VERSION ""

NS_ :

BS_:

BU_: CGM_HS TCM_HS RDCM_HS EPS_HS ECM_HS EBCM_HS BSM_HS BCM_HS

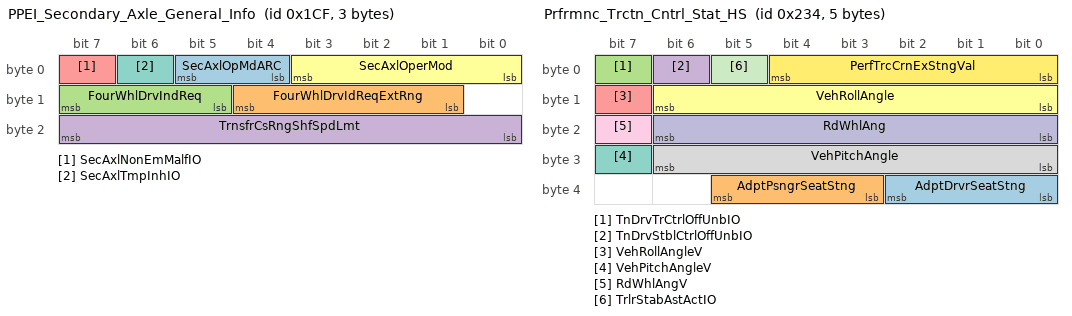
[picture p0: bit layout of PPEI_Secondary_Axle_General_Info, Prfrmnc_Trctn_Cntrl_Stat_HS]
BO_ 463 PPEI_Secondary_Axle_General_Info: 3 ECM_HS
 SG_ SecAxlOpMdARC : 5|2@0+ (1,0) [0|3] ""  CGM_HS,ECM_HS
 SG_ FourWhlDrvIdReqExtRng : 12|4@0+ (1,0) [0|15] ""  CGM_HS,BCM_HS
 SG_ FourWhlDrvIndReq : 15|3@0+ (1,0) [0|7] ""  CGM_HS,BCM_HS
 SG_ TrnsfrCsRngShfSpdLmt : 23|8@0+ (1,0) [0|255] "km / h"  CGM_HS,BCM_HS
 SG_ SecAxlNonEmMalfIO : 7|1@0+ (1,0) [0|1] ""  CGM_HS,BCM_HS
 SG_ SecAxlOperMod : 3|4@0+ (1,0) [0|15] ""  CGM_HS,TCM_HS,ECM_HS,EBCM_HS,BSM_HS,BCM_HS
 SG_ SecAxlTmpInhIO : 6|1@0+ (1,0) [0|1] ""  CGM_HS,BCM_HS

BO_ 869 CPS_Collision_Preparation_IO_HS: 4 CGM_HS
 SG_ TnDrvGapAdjUnbIO : 4|1@0+ (1,0) [0|1] ""  BCM_HS
 SG_ CPSCA_Resrv3Avail : 25|1@0+ (1,0) [0|1] ""  BCM_HS
 SG_ CPSCA_Resrv2Avail : 26|1@0+ (1,0) [0|1] ""  BCM_HS
 SG_ CPSCA_Resrv1Avail : 27|1@0+ (1,0) [0|1] ""  BCM_HS
 SG_ CPSCA_AlrtBrkStrAvail : 28|1@0+ (1,0) [0|1] ""  BCM_HS
 SG_ CPSCA_AlrtBrkAvail : 29|1@0+ (1,0) [0|1] ""  BCM_HS
 SG_ CPSCA_AlrtAvail : 30|1@0+ (1,0) [0|1] ""  BCM_HS
 SG_ CPSCA_OffAvail : 31|1@0+ (1,0) [0|1] ""  BCM_HS
 SG_ FwdClnMtgnBrkReqAct : 3|1@0+ (1,0) [0|1] ""  BCM_HS
 SG_ FCACustStngAvlbl : 23|1@0+ (1,0) [0|1] ""  BCM_HS
 SG_ FwdClnAlrtCustCrntSetngVal : 12|3@0+ (1,0) [0|7] ""  BCM_HS
 SG_ GNCustSetngAvlbl : 9|1@0+ (1,0) [0|1] ""  BCM_HS
 SG_ CPSUnblIO : 8|1@0+ (1,0) [0|1] ""  BCM_HS
 SG_ ColPrSysStngAvl : 7|1@0+ (1,0) [0|1] ""  BCM_HS
 SG_ CPSOffIO : 6|1@0+ (1,0) [0|1] ""  BCM_HS
 SG_ CPSFldIO : 5|1@0+ (1,0) [0|1] ""  BCM_HS
 SG_ ColPrSysCrntStng : 22|3@0+ (1,0) [0|7] ""  BCM_HS
 SG_ CPSAlrtOnlIO : 2|1@0+ (1,0) [0|1] ""  BCM_HS
 SG_ GNCustCrntStngVal : 15|3@0+ (1,0) [0|7] ""  BCM_HS

BO_ 564 Prfrmnc_Trctn_Cntrl_Stat_HS: 5 EBCM_HS
 SG_ AdptDrvrSeatStng : 34|3@0+ (1,0) [0|7] ""  CGM_HS,BCM_HS
 SG_ AdptPsngrSeatStng : 37|3@0+ (1,0) [0|7] ""  CGM_HS,BCM_HS
 SG_ TnDrvTrCtrlOffUnbIO : 7|1@0+ (1,0) [0|1] ""  CGM_HS,BCM_HS
 SG_ TnDrvStblCtrlOffUnbIO : 6|1@0+ (1,0) [0|1] ""  CGM_HS,BCM_HS
 SG_ VehRollAngleV : 15|1@0+ (1,0) [0|1] ""  CGM_HS,BCM_HS
 SG_ VehRollAngle : 14|7@0+ (0.703125,-45) [-45|44.296875] "deg"  CGM_HS,BCM_HS
 SG_ VehPitchAngleV : 31|1@0+ (1,0) [0|1] ""  CGM_HS,BCM_HS
 SG_ VehPitchAngle : 30|7@0+ (0.703125,-45) [-45|44.296875] "deg"  CGM_HS,BCM_HS
 SG_ RdWhlAngV : 23|1@0+ (1,0) [0|1] ""  CGM_HS,BCM_HS
 SG_ RdWhlAng : 22|7@0+ (0.703125,-45) [-45|44.296875] "deg"  CGM_HS,BCM_HS
 SG_ TrlrStabAstActIO : 5|1@0+ (1,0) [0|1] ""  CGM_HS,BCM_HS
 SG_ PerfTrcCrnExStngVal : 4|5@0+ (1,0) [0|31] ""  CGM_HS,BCM_HS

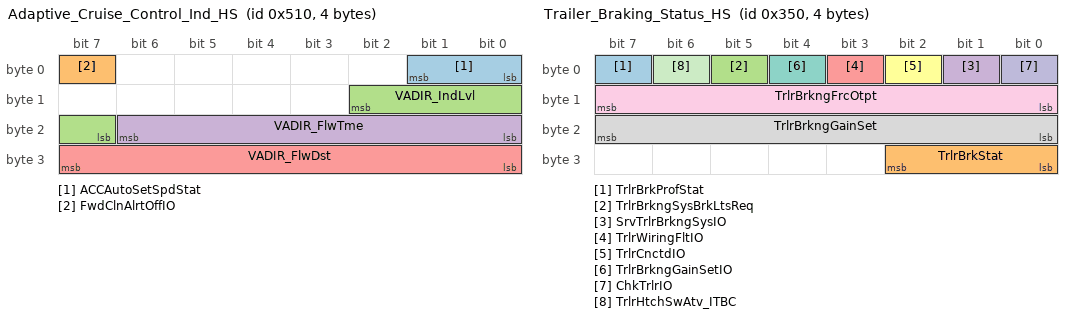
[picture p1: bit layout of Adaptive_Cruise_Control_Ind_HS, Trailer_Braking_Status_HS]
BO_ 1296 Adaptive_Cruise_Control_Ind_HS: 4 CGM_HS
 SG_ ACCAutoSetSpdStat : 1|2@0+ (1,0) [0|3] ""  BCM_HS
 SG_ FwdClnAlrtOffIO : 7|1@0+ (1,0) [0|1] ""  BCM_HS
 SG_ VADIR_IndLvl : 10|4@0+ (1,0) [0|15] ""  BCM_HS
 SG_ VADIR_FlwTme : 22|7@0+ (0.1,0) [0|12.7] "s"  BCM_HS
 SG_ VADIR_FlwDst : 31|8@0+ (1,0) [0|255] "m"  BCM_HS

BO_ 848 Trailer_Braking_Status_HS: 4 EBCM_HS
 SG_ TrlrBrkProfStat : 7|1@0+ (1,0) [0|1] ""  CGM_HS
 SG_ TrlrBrkStat : 26|3@0+ (1,0) [0|7] ""  CGM_HS,EBCM_HS
 SG_ TrlrBrkngSysBrkLtsReq : 5|1@0+ (1,0) [0|1] ""  CGM_HS,BCM_HS
 SG_ SrvTrlrBrkngSysIO : 1|1@0+ (1,0) [0|1] ""  CGM_HS,BCM_HS
 SG_ TrlrWiringFltIO : 3|1@0+ (1,0) [0|1] ""  CGM_HS,BCM_HS
 SG_ TrlrCnctdIO : 2|1@0+ (1,0) [0|1] ""  CGM_HS,BCM_HS
 SG_ TrlrBrkngGainSetIO : 4|1@0+ (1,0) [0|1] ""  CGM_HS,BCM_HS
 SG_ TrlrBrkngGainSet : 23|8@0+ (0.392157,0) [0|100.000035] "%"  CGM_HS,EBCM_HS,BCM_HS
 SG_ TrlrBrkngFrcOtpt : 15|8@0+ (0.392157,0) [0|100.000035] "%"  CGM_HS,EBCM_HS,BCM_HS
 SG_ ChkTrlrIO : 0|1@0+ (1,0) [0|1] ""  CGM_HS,BCM_HS
 SG_ TrlrHtchSwAtv_ITBC : 6|1@0+ (1,0) [0|1] ""  CGM_HS,BCM_HS

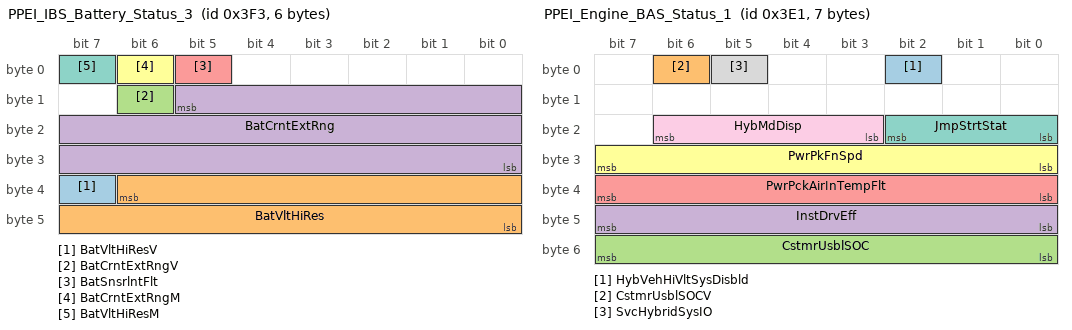
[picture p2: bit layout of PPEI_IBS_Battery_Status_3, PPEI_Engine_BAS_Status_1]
BO_ 1011 PPEI_IBS_Battery_Status_3: 6 ECM_HS
 SG_ BatVltHiResV : 39|1@0+ (1,0) [0|1] ""  CGM_HS,BCM_HS
 SG_ BatVltHiRes : 38|15@0+ (0.001,0) [0|32.767] "volts"  CGM_HS,BCM_HS
 SG_ BatCrntExtRngV : 14|1@0+ (1,0) [0|1] ""  CGM_HS,BCM_HS
 SG_ BatCrntExtRng : 13|22@0+ (0.001,-2097.152) [-2097.152|2097.151] "amps"  CGM_HS,BCM_HS
 SG_ BatSnsrlntFlt : 5|1@0+ (1,0) [0|1] ""  CGM_HS,BCM_HS
 SG_ BatCrntExtRngM : 6|1@0+ (1,0) [0|1] ""  CGM_HS,BCM_HS
 SG_ BatVltHiResM : 7|1@0+ (1,0) [0|1] ""  CGM_HS,BCM_HS

BO_ 993 PPEI_Engine_BAS_Status_1: 7 BSM_HS
 SG_ HybVehHiVltSysDisbld : 2|1@0+ (1,0) [0|1] ""  CGM_HS
 SG_ CstmrUsblSOCV : 6|1@0+ (1,0) [0|1] ""  CGM_HS,BCM_HS
 SG_ CstmrUsblSOC : 55|8@0+ (0.39216,0) [0|100.0008] "%"  CGM_HS,BCM_HS
 SG_ InstDrvEff : 47|8@0- (0.78125,0) [-100|99.21875] "%"  CGM_HS,BCM_HS
 SG_ PwrPckAirInTempFlt : 39|8@0+ (1,-40) [-40|215] "deg C"  CGM_HS,BCM_HS
 SG_ PwrPkFnSpd : 31|8@0+ (0.392157,0) [0|100.000035] "%"  CGM_HS,BCM_HS
 SG_ JmpStrtStat : 18|3@0+ (1,0) [0|7] ""  CGM_HS,BCM_HS
 SG_ SvcHybridSysIO : 5|1@0+ (1,0) [0|1] ""  CGM_HS,BCM_HS
 SG_ HybMdDisp : 22|4@0+ (1,0) [0|15] ""  CGM_HS,BCM_HS

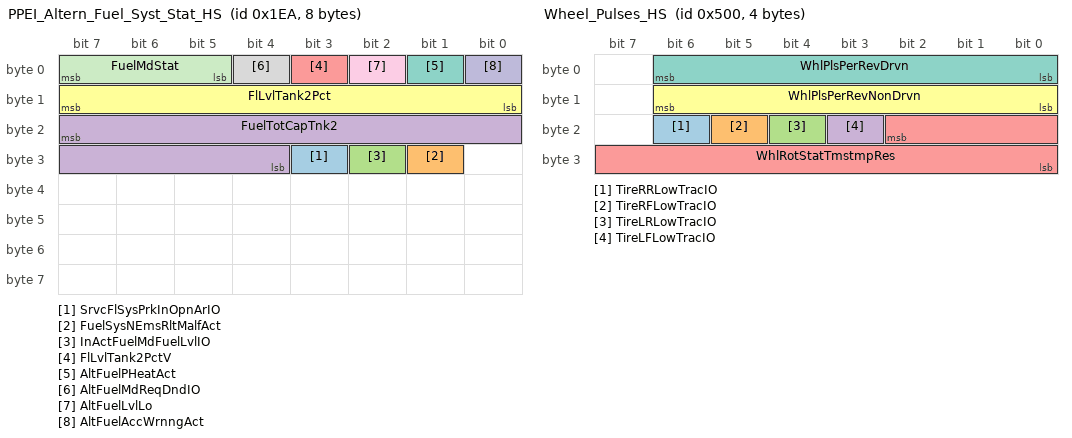
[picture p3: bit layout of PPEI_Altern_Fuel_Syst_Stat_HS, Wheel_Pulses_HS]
BO_ 490 PPEI_Altern_Fuel_Syst_Stat_HS: 8 ECM_HS
 SG_ SrvcFlSysPrkInOpnArIO : 27|1@0+ (1,0) [0|1] ""  CGM_HS,BCM_HS
 SG_ FuelSysNEmsRltMalfAct : 25|1@0+ (1,0) [0|1] ""  CGM_HS,BCM_HS
 SG_ InActFuelMdFuelLvlIO : 26|1@0+ (1,0) [0|1] ""  CGM_HS,BCM_HS
 SG_ FuelTotCapTnk2 : 23|12@0+ (0.125,0) [0|511.875] "liters"  CGM_HS,BCM_HS
 SG_ FlLvlTank2PctV : 3|1@0+ (1,0) [0|1] ""  CGM_HS,BCM_HS
 SG_ FlLvlTank2Pct : 15|8@0+ (0.392157,0) [0|100.000035] "%"  CGM_HS,BCM_HS
 SG_ AltFuelPHeatAct : 1|1@0+ (1,0) [0|1] ""  CGM_HS,ECM_HS,BCM_HS
 SG_ AltFuelMdReqDndIO : 4|1@0+ (1,0) [0|1] ""  CGM_HS,BCM_HS
 SG_ AltFuelLvlLo : 2|1@0+ (1,0) [0|1] ""  CGM_HS,ECM_HS,BCM_HS
 SG_ AltFuelAccWrnngAct : 0|1@0+ (1,0) [0|1] ""  CGM_HS,BCM_HS
 SG_ FuelMdStat : 7|3@0+ (1,0) [0|7] ""  CGM_HS,ECM_HS,BCM_HS

BO_ 452 PPEI_Torque_Request_Status: 8 ECM_HS
 SG_ ACCATCS_LmtgStat : 12|2@0+ (1,0) [0|3] ""  CGM_HS
 SG_ ACCATCS_RqStat : 15|3@0+ (1,0) [0|7] ""  CGM_HS
 SG_ RdLdNomAxlTrq : 10|19@0+ (0.125,-22534) [-22534|43001.875] "Nm"  CGM_HS
 SG_ CPSATCS_ReqStatus : 37|3@0+ (1,0) [0|7] ""  CGM_HS
 SG_ CPSATCS_LmtngStatus : 39|2@0+ (1,0) [0|3] ""  CGM_HS
 SG_ RVBATCS_ReqStat : 53|3@0+ (1,0) [0|7] ""  CGM_HS
 SG_ RVBATCS_LmtngStat : 55|2@0+ (1,0) [0|3] ""  CGM_HS
 SG_ FSpRgACCSwADdPVal : 50|2@0+ (1,0) [0|3] ""  CGM_HS,EBCM_HS
 SG_ FSpRgACCSwADdARC : 6|2@0+ (1,0) [0|3] ""  CGM_HS,EBCM_HS
 SG_ FSpRgACCSwADd : 7|1@0+ (1,0) [0|1] ""  CGM_HS,EBCM_HS
 SG_ AutBrkAccActPsStRC : 34|2@0+ (1,0) [0|3] ""  CGM_HS,EBCM_HS
 SG_ AutBrkAccActPsStPVal : 48|9@0+ (1,0) [0|511] ""  CGM_HS,EBCM_HS
 SG_ ABAAPS_AccPos : 47|8@0+ (0.392157,0) [0|100.000035] "%"  CGM_HS,EBCM_HS
 SG_ ABAAPS_AccPosV : 32|1@0+ (1,0) [0|1] ""  CGM_HS,EBCM_HS
 SG_ AccPdlOvrrdAtvProtVal : 1|2@0+ (1,0) [0|3] ""  CGM_HS,TCM_HS,EBCM_HS
 SG_ AccPdlOvrrdAtvARC : 3|2@0+ (1,0) [0|3] ""  CGM_HS,TCM_HS,EBCM_HS
 SG_ AccPdlOvrrdAtv : 4|1@0+ (1,0) [0|1] ""  CGM_HS,TCM_HS,EBCM_HS,BCM_HS

BO_ 1280 Wheel_Pulses_HS: 4 EBCM_HS
 SG_ TireRRLowTracIO : 22|1@0+ (1,0) [0|1] ""  CGM_HS,BCM_HS
 SG_ TireRFLowTracIO : 21|1@0+ (1,0) [0|1] ""  CGM_HS,BCM_HS
 SG_ TireLRLowTracIO : 20|1@0+ (1,0) [0|1] ""  CGM_HS,BCM_HS
 SG_ TireLFLowTracIO : 19|1@0+ (1,0) [0|1] ""  CGM_HS,BCM_HS
 SG_ WhlRotStatTmstmpRes : 18|11@0+ (0.002,0) [0|4.094] "uSec"  CGM_HS,EPS_HS,RDCM_HS,BCM_HS
 SG_ WhlPlsPerRevNonDrvn : 14|7@0+ (1,0) [0|127] ""  CGM_HS,EPS_HS,RDCM_HS,BCM_HS
 SG_ WhlPlsPerRevDrvn : 6|7@0+ (1,0) [0|127] ""  CGM_HS,EPS_HS,RDCM_HS,BCM_HS

BO_ 562 Driving_Mode_Control_HS: 8 EBCM_HS
 SG_ BrkSysAutBrkStat : 52|2@0+ (1,0) [0|3] ""  CGM_HS
 SG_ FSRACCBrkngReqDenied : 46|1@0+ (1,0) [0|1] ""  CGM_HS
 SG_ BrkSysExtHldCpbltyFld : 47|1@0+ (1,0) [0|1] ""  CGM_HS
 SG_ DrvlneMntsPerfMdRq : 50|3@0+ (1,0) [0|7] ""  CGM_HS,ECM_HS
 SG_ RideCntrlPerfMdRq : 18|3@0+ (1,0) [0|7] ""  CGM_HS
 SG_ StgSysPerfMdRq : 29|3@0+ (1,0) [0|7] ""  CGM_HS,EPS_HS
 SG_ DiffPerfMdRq : 26|3@0+ (1,0) [0|7] ""  CGM_HS
 SG_ ExhstPerfMdRq : 5|3@0+ (1,0) [0|7] ""  CGM_HS
 SG_ DrvMdCntrlState : 39|8@0+ (1,0) [0|255] ""  CGM_HS,EPS_HS,RDCM_HS
 SG_ AWDPerfMdRq : 2|3@0+ (1,0) [0|7] ""  CGM_HS,RDCM_HS
 SG_ SndPerfMdCsStAvl : 63|1@0+ (1,0) [0|1] ""  CGM_HS,BCM_HS
 SG_ SndPerfMdCsCrStVal : 62|3@0+ (1,0) [0|7] ""  CGM_HS,BCM_HS
 SG_ DispPerfMdCsStAvl : 59|1@0+ (1,0) [0|1] ""  CGM_HS,BCM_HS
 SG_ DispPerfMdCsCrStVal : 58|3@0+ (1,0) [0|7] ""  CGM_HS,BCM_HS
 SG_ SndEnhcmtPerfMdRq : 13|3@0+ (1,0) [0|7] ""  CGM_HS,BCM_HS
 SG_ DsplyPerfMdRq : 10|3@0+ (1,0) [0|7] ""  CGM_HS,BCM_HS
 SG_ HillDscntCntlSysStat : 55|3@0+ (1,0) [0|7] ""  CGM_HS,BCM_HS
 SG_ SusCustStngAvlbl : 23|1@0+ (1,0) [0|1] ""  CGM_HS,BCM_HS
 SG_ SusCustCurrStngVal : 45|3@0+ (1,0) [0|7] ""  CGM_HS,BCM_HS
 SG_ StrCustStngAvlbl : 7|1@0+ (1,0) [0|1] ""  CGM_HS,BCM_HS
 SG_ StrCustCurrStngVal : 42|3@0+ (1,0) [0|7] ""  CGM_HS,BCM_HS
 SG_ DrvlnCustStngAvlbl : 6|1@0+ (1,0) [0|1] ""  CGM_HS,BCM_HS
 SG_ DrvlnCustCurrStngVal : 22|3@0+ (1,0) [0|7] ""  CGM_HS,BCM_HS

BO_ 386 Environment_Id_Resp_4_HS: 8 EBCM_HS
 SG_ AdptCruzCtrlStg : 20|3@0+ (1,0) [0|7] ""  CGM_HS
 SG_ AHAct : 31|1@0+ (1,0) [0|1] ""  CGM_HS,BCM_HS
 SG_ AHEnbld : 30|1@0+ (1,0) [0|1] ""  CGM_HS,BCM_HS
 SG_ ShfToPrkBfExtngIO : 29|1@0+ (1,0) [0|1] ""  CGM_HS,BCM_HS
 SG_ AHServcIO : 28|1@0+ (1,0) [0|1] ""  CGM_HS,BCM_HS
 SG_ AHAppBrkPedlIO : 27|1@0+ (1,0) [0|1] ""  CGM_HS,BCM_HS
 SG_ AHDisbldStbltIO : 26|1@0+ (1,0) [0|1] ""  CGM_HS,BCM_HS
 SG_ AHDisbldDrOpnIO : 25|1@0+ (1,0) [0|1] ""  CGM_HS,BCM_HS
 SG_ PMVSS_Disps : 58|3@0+ (1,0) [0|7] ""  CGM_HS,BCM_HS
 SG_ PMVSS_Exhst : 61|3@0+ (1,0) [0|7] ""  CGM_HS,BCM_HS
 SG_ PMVSS_PsngrSeat : 48|3@0+ (1,0) [0|7] ""  CGM_HS,BCM_HS
 SG_ PMVSS_DrvrSeat : 51|3@0+ (1,0) [0|7] ""  CGM_HS,BCM_HS
 SG_ PMVSS_AdptCrsCnt : 54|3@0+ (1,0) [0|7] ""  CGM_HS,BCM_HS
 SG_ PMVSS_Drvln : 41|3@0+ (1,0) [0|7] ""  CGM_HS,BCM_HS
 SG_ PMVSS_Susp : 44|3@0+ (1,0) [0|7] ""  CGM_HS,BCM_HS
 SG_ PMVSS_Strng : 47|3@0+ (1,0) [0|7] ""  CGM_HS,BCM_HS
 SG_ PMVSS_Trans : 34|3@0+ (1,0) [0|7] ""  CGM_HS,BCM_HS
 SG_ PMVSS_Eng : 37|3@0+ (1,0) [0|7] ""  CGM_HS,BCM_HS
 SG_ PMVSS_Snd : 24|3@0+ (1,0) [0|7] ""  CGM_HS,BCM_HS
 SG_ AWDRecmndIO : 21|1@0+ (1,0) [0|1] ""  CGM_HS,BCM_HS
 SG_ EnvIdRsp4 : 7|16@0+ (1,0) [0|65535] ""  CGM_HS,BCM_HS
 SG_ EnvIdRspSt4 : 17|2@0+ (1,0) [0|3] ""  CGM_HS,BCM_HS

BO_ 532 Brake_Pedal_Driver_Status_HS: 6 EBCM_HS
 SG_ RedntVSEActARC : 38|2@0+ (1,0) [0|3] ""  CGM_HS,EPS_HS
 SG_ RedntVSEAct : 39|1@0+ (1,0) [0|1] ""  CGM_HS,EPS_HS
 SG_ AutoBrkngActARC : 22|2@0+ (1,0) [0|3] ""  CGM_HS
 SG_ VehHldDrvrDsblActvFlg : 36|1@0+ (1,0) [0|1] ""  CGM_HS
 SG_ ABSAutnmsBrkReqPVal : 41|2@0+ (1,0) [0|3] ""  CGM_HS
 SG_ AutoBrkngAvlbl : 17|1@0+ (1,0) [0|1] ""  CGM_HS,EPS_HS,ECM_HS
 SG_ ABSAutnmsBrkReqARC : 35|2@0+ (1,0) [0|3] ""  CGM_HS
 SG_ ABSAutnmsBrkReq : 33|1@0+ (1,0) [0|1] ""  CGM_HS
 SG_ ABSActvProtPVal : 43|2@0+ (1,0) [0|3] ""  CGM_HS,EPS_HS
 SG_ ABSActvProtARC : 45|2@0+ (1,0) [0|3] ""  CGM_HS,EPS_HS
 SG_ ABSActvProt : 46|1@0+ (1,0) [0|1] ""  CGM_HS,EPS_HS
 SG_ BrkPdDrvAPrsStaPVal : 16|9@0+ (1,0) [0|511] ""  CGM_HS
 SG_ BrkPdDrvAppPrsAlRC : 2|2@0+ (1,0) [0|3] ""  CGM_HS
 SG_ AutoBrkngAct : 18|1@0+ (1,0) [0|1] ""  CGM_HS
 SG_ HilRlbkCtrlActIO : 19|1@0+ (1,0) [0|1] ""  CGM_HS,BCM_HS
 SG_ HlStrAssActIO : 20|1@0+ (1,0) [0|1] ""  CGM_HS,BCM_HS
 SG_ BrkSysAutBrkFld : 5|1@0+ (1,0) [0|1] ""  CGM_HS,ECM_HS,BCM_HS
 SG_ IntBrkAssPreFilReq : 4|1@0+ (1,0) [0|1] "N/A"  CGM_HS,BCM_HS
 SG_ BrkSysMalFuncIndOn : 3|1@0+ (1,0) [0|1] ""  CGM_HS,BCM_HS
 SG_ BPDAPS_BkPDrvApPV : 8|1@0+ (1,0) [0|1] ""  CGM_HS,BCM_HS
 SG_ BPDAPS_BkPDrvApP : 0|8@0+ (75,0) [0|19125] "kPa"  CGM_HS,BCM_HS
 SG_ BrkFldLvlLwV : 7|1@0+ (1,0) [0|1] ""  CGM_HS,BCM_HS
 SG_ BrkFldLvlLw : 6|1@0+ (1,0) [0|1] ""  CGM_HS,BCM_HS

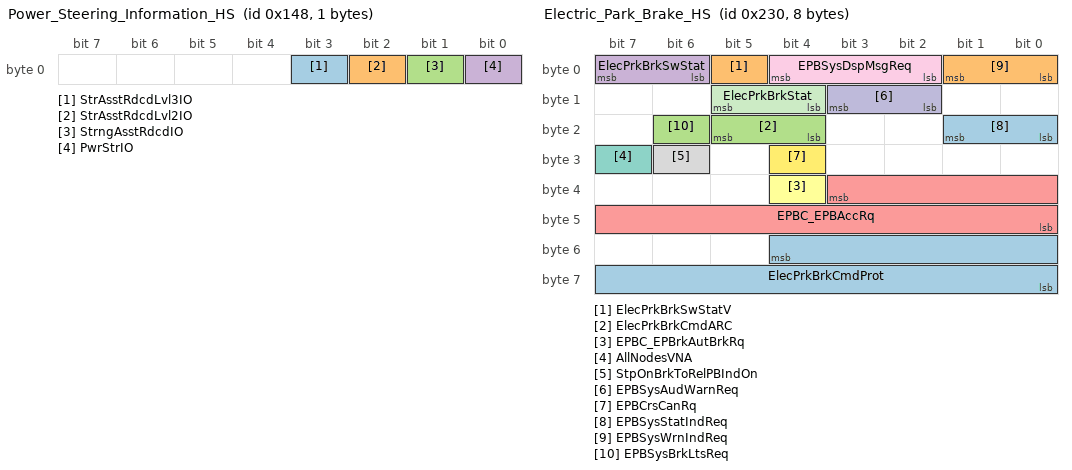
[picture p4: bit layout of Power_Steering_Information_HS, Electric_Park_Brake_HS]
BO_ 328 Power_Steering_Information_HS: 1 EBCM_HS
 SG_ StrAsstRdcdLvl3IO : 3|1@0+ (1,0) [0|1] ""  CGM_HS,BCM_HS
 SG_ StrAsstRdcdLvl2IO : 2|1@0+ (1,0) [0|1] ""  CGM_HS,BCM_HS
 SG_ StrngAsstRdcdIO : 1|1@0+ (1,0) [0|1] ""  CGM_HS,BCM_HS
 SG_ PwrStrIO : 0|1@0+ (1,0) [0|1] ""  CGM_HS,BCM_HS

BO_ 560 Electric_Park_Brake_HS: 8 EBCM_HS
 SG_ ElecPrkBrkCmdProt : 52|13@0+ (1,0) [0|8191] ""  CGM_HS
 SG_ ElecPrkBrkSwStatV : 5|1@0+ (1,0) [0|1] ""  CGM_HS
 SG_ ElecPrkBrkCmdARC : 21|2@0+ (1,0) [0|3] ""  CGM_HS
 SG_ ElecPrkBrkSwStat : 7|2@0+ (1,0) [0|3] ""  CGM_HS
 SG_ EPBC_EPBAccRq : 35|12@0- (0.01,0) [-20.48|20.47] "m/s^2"  CGM_HS
 SG_ EPBC_EPBrkAutBrkRq : 36|1@0+ (1,0) [0|1] ""  CGM_HS
 SG_ AllNodesVNA : 31|1@0+ (1,0) [0|1] ""  CGM_HS,BCM_HS
 SG_ StpOnBrkToRelPBIndOn : 30|1@0+ (1,0) [0|1] ""  CGM_HS,BCM_HS
 SG_ EPBSysDspMsgReq : 4|3@0+ (1,0) [0|7] ""  CGM_HS,BCM_HS
 SG_ EPBSysAudWarnReq : 11|2@0+ (1,0) [0|3] ""  CGM_HS,BCM_HS
 SG_ ElecPrkBrkStat : 13|2@0+ (1,0) [0|3] ""  CGM_HS,RDCM_HS,BCM_HS
 SG_ EPBCrsCanRq : 28|1@0+ (1,0) [0|1] ""  CGM_HS,BCM_HS
 SG_ EPBSysStatIndReq : 17|2@0+ (1,0) [0|3] ""  CGM_HS,BCM_HS
 SG_ EPBSysWrnIndReq : 1|2@0+ (1,0) [0|3] ""  CGM_HS,BCM_HS
 SG_ EPBSysBrkLtsReq : 22|1@0+ (1,0) [0|1] ""  CGM_HS,BCM_HS

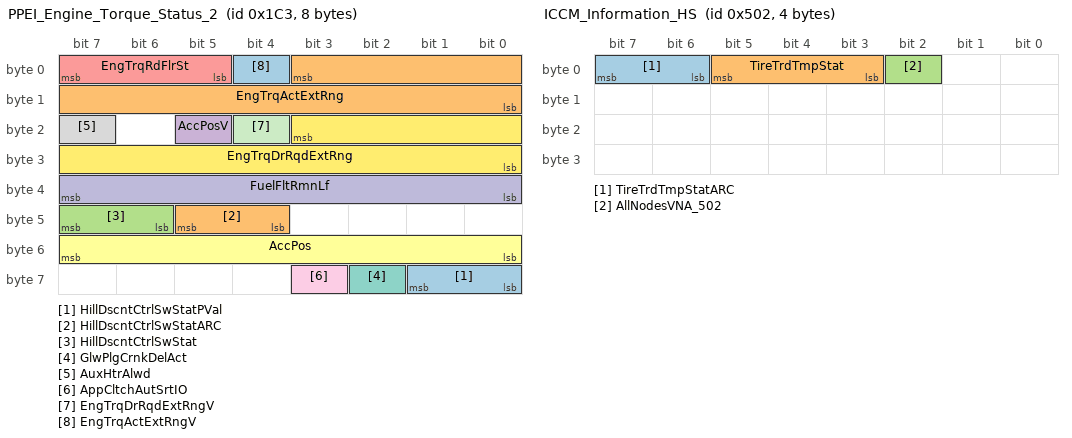
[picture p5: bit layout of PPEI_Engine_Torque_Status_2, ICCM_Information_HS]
BO_ 451 PPEI_Engine_Torque_Status_2: 8 ECM_HS
 SG_ HillDscntCtrlSwStatPVal : 57|2@0+ (1,0) [0|3] ""  CGM_HS,EBCM_HS
 SG_ HillDscntCtrlSwStatARC : 45|2@0+ (1,0) [0|3] ""  CGM_HS,EBCM_HS
 SG_ HillDscntCtrlSwStat : 47|2@0+ (1,0) [0|3] ""  CGM_HS,EBCM_HS
 SG_ AccPosV : 21|1@0+ (1,0) [0|1] ""  CGM_HS,RDCM_HS,EBCM_HS
 SG_ EngTrqRdFlrSt : 7|3@0+ (1,0) [0|7] ""  CGM_HS,EBCM_HS
 SG_ AccPos : 55|8@0+ (0.392157,0) [0|100.000035] "%"  CGM_HS,RDCM_HS,EBCM_HS,BSM_HS
 SG_ GlwPlgCrnkDelAct : 58|1@0+ (1,0) [0|1] ""  CGM_HS,BCM_HS
 SG_ AuxHtrAlwd : 23|1@0+ (1,0) [0|1] ""  CGM_HS,BCM_HS
 SG_ AppCltchAutSrtIO : 59|1@0+ (1,0) [0|1] ""  CGM_HS,BCM_HS
 SG_ FuelFltRmnLf : 39|8@0+ (0.392157,0) [0|100.000035] "%"  CGM_HS,BCM_HS
 SG_ EngTrqDrRqdExtRngV : 20|1@0+ (1,0) [0|1] ""  CGM_HS,RDCM_HS,EBCM_HS,BCM_HS
 SG_ EngTrqDrRqdExtRng : 19|12@0+ (0.5,-848) [-848|1199.5] "Nm"  CGM_HS,RDCM_HS,EBCM_HS,BCM_HS
 SG_ EngTrqActExtRngV : 4|1@0+ (1,0) [0|1] ""  CGM_HS,EPS_HS,RDCM_HS,EBCM_HS,BCM_HS
 SG_ EngTrqActExtRng : 3|12@0+ (0.5,-848) [-848|1199.5] "Nm"  CGM_HS,EPS_HS,RDCM_HS,EBCM_HS,BCM_HS

BO_ 1282 ICCM_Information_HS: 4 EBCM_HS
 SG_ TireTrdTmpStatARC : 7|2@0+ (1,0) [0|3] ""  CGM_HS,EBCM_HS
 SG_ TireTrdTmpStat : 5|3@0+ (1,0) [0|7] ""  CGM_HS,EBCM_HS,BCM_HS
 SG_ AllNodesVNA_502 : 2|1@0+ (1,0) [0|1] ""  CGM_HS,BCM_HS

BO_ 2033 PCU_Req_to_SDM_HS: 8 CGM_HS
 SG_ PCUInfo : 7|64@0+ (1,0) [0|1.84467440737096E+019] ""  CGM_HS,BCM_HS

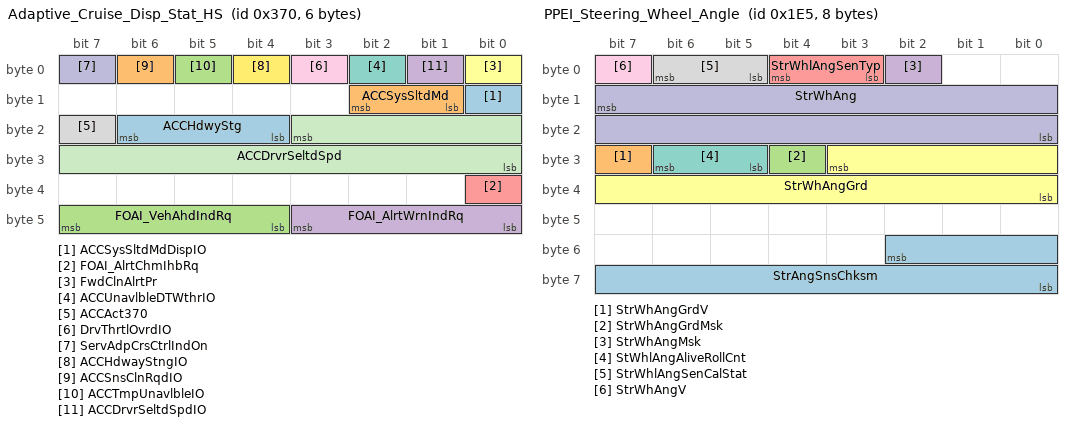
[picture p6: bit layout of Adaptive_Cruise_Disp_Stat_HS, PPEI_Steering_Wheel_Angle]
BO_ 880 Adaptive_Cruise_Disp_Stat_HS: 6 CGM_HS
 SG_ ACCSysSltdMdDispIO : 8|1@0+ (1,0) [0|1] ""  BCM_HS
 SG_ ACCSysSltdMd : 10|2@0+ (1,0) [0|3] ""  BCM_HS
 SG_ FOAI_VehAhdIndRq : 47|4@0+ (1,0) [0|15] ""  BCM_HS
 SG_ FOAI_AlrtWrnIndRq : 43|4@0+ (1,0) [0|15] ""  BCM_HS
 SG_ FOAI_AlrtChmIhbRq : 32|1@0+ (1,0) [0|1] ""  BCM_HS
 SG_ FwdClnAlrtPr : 0|1@0+ (1,0) [0|1] ""  BCM_HS
 SG_ ACCUnavlbleDTWthrIO : 2|1@0+ (1,0) [0|1] ""  BCM_HS
 SG_ ACCAct370 : 23|1@0+ (1,0) [0|1] ""  TCM_HS,EBCM_HS,BCM_HS
 SG_ DrvThrtlOvrdIO : 3|1@0+ (1,0) [0|1] ""  BCM_HS
 SG_ ServAdpCrsCtrlIndOn : 7|1@0+ (1,0) [0|1] ""  BCM_HS
 SG_ ACCDrvrSeltdSpd : 19|12@0+ (0.0625,0) [0|255.9375] "km / h"  ECM_HS,BCM_HS
 SG_ ACCHdwayStngIO : 4|1@0+ (1,0) [0|1] ""  BCM_HS
 SG_ ACCHdwyStg : 22|3@0+ (1,0) [0|7] ""  BCM_HS
 SG_ ACCSnsClnRqdIO : 6|1@0+ (1,0) [0|1] ""  BCM_HS
 SG_ ACCTmpUnavlbleIO : 5|1@0+ (1,0) [0|1] ""  BCM_HS
 SG_ ACCDrvrSeltdSpdIO : 1|1@0+ (1,0) [0|1] ""  BCM_HS

BO_ 577 USDT_Req_to_BCM_HS: 8 CGM_HS
 SG_ DgnInf : 7|64@0+ (1,0) [0|1.84467440737096E+019] ""  BCM_HS

BO_ 485 PPEI_Steering_Wheel_Angle: 8 EBCM_HS
 SG_ StrAngSnsChksm : 50|11@0+ (1,0) [0|2047] ""  CGM_HS,TCM_HS,EPS_HS,ECM_HS,EBCM_HS
 SG_ StrWhAngGrdV : 31|1@0+ (1,0) [0|1] ""  CGM_HS,TCM_HS,RDCM_HS,EPS_HS,ECM_HS,EBCM_HS
 SG_ StrWhAngGrdMsk : 28|1@0+ (1,0) [0|1] ""  CGM_HS,EPS_HS,EBCM_HS
 SG_ StrWhAngMsk : 2|1@0+ (1,0) [0|1] ""  CGM_HS,TCM_HS,RDCM_HS,EPS_HS,ECM_HS,EBCM_HS
 SG_ StrWhlAngSenTyp : 4|2@0+ (1,0) [0|3] ""  CGM_HS,EPS_HS,EBCM_HS
 SG_ StrWhAngGrd : 27|12@0- (1,0) [-2048|2047] "deg/sec"  CGM_HS,TCM_HS,RDCM_HS,EPS_HS,ECM_HS,EBCM_HS
 SG_ StWhlAngAliveRollCnt : 30|2@0+ (1,0) [0|3] ""  CGM_HS,TCM_HS,RDCM_HS,EPS_HS,ECM_HS,EBCM_HS
 SG_ StrWhlAngSenCalStat : 6|2@0+ (1,0) [0|3] ""  CGM_HS,TCM_HS,RDCM_HS,EPS_HS,ECM_HS,EBCM_HS,BCM_HS
 SG_ StrWhAngV : 7|1@0+ (1,0) [0|1] ""  CGM_HS,TCM_HS,RDCM_HS,EPS_HS,ECM_HS,EBCM_HS,BCM_HS
 SG_ StrWhAng : 15|16@0- (0.0625,0) [-2048|2047.9375] "deg"  CGM_HS,TCM_HS,RDCM_HS,EPS_HS,ECM_HS,EBCM_HS,BCM_HS

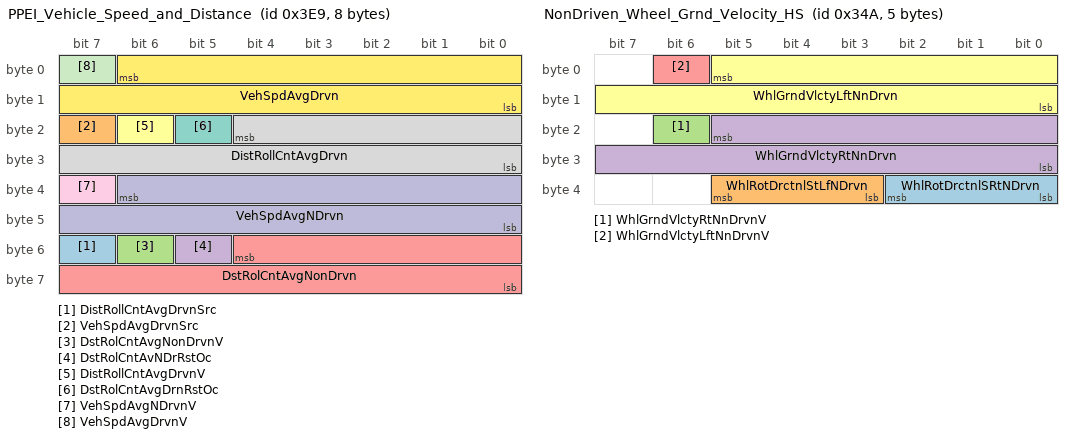
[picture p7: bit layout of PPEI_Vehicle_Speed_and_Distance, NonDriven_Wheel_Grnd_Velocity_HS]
BO_ 1001 PPEI_Vehicle_Speed_and_Distance: 8 ECM_HS
 SG_ DistRollCntAvgDrvnSrc : 55|1@0+ (1,0) [0|1] ""  CGM_HS,TCM_HS,EPS_HS,EBCM_HS,BSM_HS,BCM_HS
 SG_ VehSpdAvgDrvnSrc : 23|1@0+ (1,0) [0|1] ""  CGM_HS,TCM_HS,EPS_HS,EBCM_HS,BCM_HS
 SG_ DstRolCntAvgNonDrvnV : 54|1@0+ (1,0) [0|1] ""  CGM_HS,EPS_HS,EBCM_HS,BSM_HS,BCM_HS
 SG_ DstRolCntAvNDrRstOc : 53|1@0+ (1,0) [0|1] ""  CGM_HS,EPS_HS,EBCM_HS,BSM_HS,BCM_HS
 SG_ DstRolCntAvgNonDrvn : 52|13@0+ (0.125,0) [0|1023.875] "m"  CGM_HS,EPS_HS,EBCM_HS,BSM_HS,BCM_HS
 SG_ DistRollCntAvgDrvnV : 22|1@0+ (1,0) [0|1] ""  CGM_HS,TCM_HS,EPS_HS,EBCM_HS,BSM_HS,BCM_HS
 SG_ DstRolCntAvgDrnRstOc : 21|1@0+ (1,0) [0|1] ""  CGM_HS,TCM_HS,EPS_HS,EBCM_HS,BSM_HS,BCM_HS
 SG_ DistRollCntAvgDrvn : 20|13@0+ (0.125,0) [0|1023.875] "m"  CGM_HS,TCM_HS,EPS_HS,EBCM_HS,BSM_HS,BCM_HS
 SG_ VehSpdAvgNDrvnV : 39|1@0+ (1,0) [0|1] ""  CGM_HS,EPS_HS,EBCM_HS,BSM_HS,BCM_HS
 SG_ VehSpdAvgNDrvn : 38|15@0+ (0.015625,0) [0|511.984375] "km / h"  CGM_HS,EPS_HS,EBCM_HS,BSM_HS,BCM_HS
 SG_ VehSpdAvgDrvnV : 7|1@0+ (1,0) [0|1] ""  CGM_HS,TCM_HS,EPS_HS,EBCM_HS,BSM_HS,BCM_HS
 SG_ VehSpdAvgDrvn : 6|15@0+ (0.015625,0) [0|511.984375] "km / h"  CGM_HS,TCM_HS,EPS_HS,EBCM_HS,BSM_HS,BCM_HS

BO_ 961 PPEI_Powertrain_Immobilizer_Data: 8 ECM_HS
 SG_ PTImmblzerInfo : 7|64@0+ (1,0) [0|1.84467440737096E+019] ""  CGM_HS,ECM_HS,BCM_HS

BO_ 842 NonDriven_Wheel_Grnd_Velocity_HS: 5 EBCM_HS
 SG_ WhlRotDrctnlSRtNDrvn : 34|3@0+ (1,0) [0|7] ""  CGM_HS,EPS_HS
 SG_ WhlRotDrctnlStLfNDrvn : 37|3@0+ (1,0) [0|7] ""  CGM_HS,EPS_HS
 SG_ WhlGrndVlctyRtNnDrvnV : 22|1@0+ (1,0) [0|1] ""  CGM_HS,RDCM_HS,EPS_HS,BCM_HS
 SG_ WhlGrndVlctyRtNnDrvn : 21|14@0+ (0.03125,0) [0|511.96875] "km / h"  CGM_HS,RDCM_HS,EPS_HS,BCM_HS
 SG_ WhlGrndVlctyLftNnDrvnV : 6|1@0+ (1,0) [0|1] ""  CGM_HS,RDCM_HS,EPS_HS,BCM_HS
 SG_ WhlGrndVlctyLftNnDrvn : 5|14@0+ (0.03125,0) [0|511.96875] "km / h"  CGM_HS,RDCM_HS,EPS_HS,BCM_HS

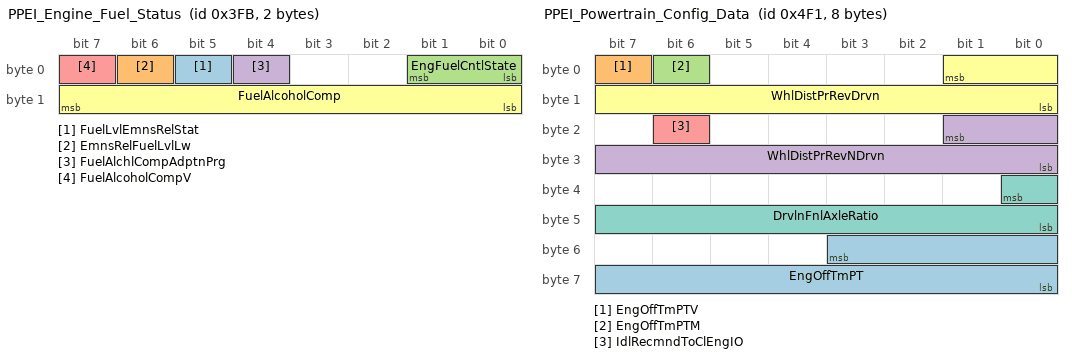
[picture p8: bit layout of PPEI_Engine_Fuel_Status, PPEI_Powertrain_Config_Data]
BO_ 1019 PPEI_Engine_Fuel_Status: 2 ECM_HS
 SG_ FuelLvlEmnsRelStat : 5|1@0+ (1,0) [0|1] ""  CGM_HS
 SG_ EmnsRelFuelLvlLw : 6|1@0+ (1,0) [0|1] ""  CGM_HS
 SG_ EngFuelCntlState : 1|2@0+ (1,0) [0|3] ""  CGM_HS
 SG_ FuelAlchlCompAdptnPrg : 4|1@0+ (1,0) [0|1] ""  CGM_HS,BCM_HS
 SG_ FuelAlcoholCompV : 7|1@0+ (1,0) [0|1] ""  CGM_HS,BSM_HS,BCM_HS
 SG_ FuelAlcoholComp : 15|8@0+ (0.392157,0) [0|100.000035] "%"  CGM_HS,BSM_HS,BCM_HS

BO_ 1265 PPEI_Powertrain_Config_Data: 8 ECM_HS
 SG_ EngOffTmPT : 51|12@0+ (0.5,0) [0|2047.5] "min"  CGM_HS,TCM_HS,EBCM_HS
 SG_ EngOffTmPTV : 7|1@0+ (1,0) [0|1] ""  CGM_HS,TCM_HS,EBCM_HS
 SG_ EngOffTmPTM : 6|1@0+ (1,0) [0|1] ""  CGM_HS,TCM_HS,EBCM_HS
 SG_ WhlDistPrRevNDrvn : 17|10@0+ (3,800) [800|3869] "mm"  CGM_HS,TCM_HS,RDCM_HS,EPS_HS,EBCM_HS
 SG_ IdlRecmndToClEngIO : 22|1@0+ (1,0) [0|1] ""  CGM_HS,BCM_HS
 SG_ WhlDistPrRevDrvn : 1|10@0+ (3,800) [800|3869] "mm"  CGM_HS,TCM_HS,RDCM_HS,EPS_HS,EBCM_HS,BCM_HS
 SG_ DrvlnFnlAxleRatio : 32|9@0+ (0.01,2) [2|7.11] ""  CGM_HS,TCM_HS,EBCM_HS,BCM_HS

BO_ 417 ETEI_Engine_General_Status: 7 ECM_HS
 SG_ EngRunng : 30|1@0+ (1,0) [0|1] ""  TCM_HS
 SG_ EngCrsCntrlMode : 29|3@0+ (1,0) [0|7] ""  CGM_HS,TCM_HS
 SG_ EngPstOxgSnsDgAstRq : 31|1@0+ (1,0) [0|1] ""  CGM_HS,TCM_HS
 SG_ CrsCtrlCnstSpdAct : 26|1@0+ (1,0) [0|1] ""  CGM_HS,TCM_HS
 SG_ WrmUpShftPtrnRq : 25|1@0+ (1,0) [0|1] ""  CGM_HS,TCM_HS
 SG_ EngIdlSpdRdcdRng : 39|8@0+ (8,0) [0|2040] "rpm"  CGM_HS,TCM_HS
 SG_ EngAlwCltAdp : 24|1@0+ (1,0) [0|1] ""  CGM_HS,TCM_HS
 SG_ BsTrgtEngIdlSpd : 47|8@0+ (8,0) [0|2040] "rpm"  CGM_HS,TCM_HS
 SG_ AccPdlPosPcntFullRngV : 17|1@0+ (1,0) [0|1] ""  CGM_HS,TCM_HS
 SG_ AccPdlPosPcntFullRng : 55|8@0+ (0.392157,0) [0|100.000035] "%"  CGM_HS,TCM_HS
 SG_ DslPrtFltrIdlRgtnMdReq : 20|1@0+ (1,0) [0|1] ""  CGM_HS,TCM_HS
 SG_ DslPartFltrClngAlgActM : 18|1@0+ (1,0) [0|1] ""  CGM_HS,TCM_HS
 SG_ DslPartFltrClngAlgAct : 19|1@0+ (1,0) [0|1] ""  CGM_HS,TCM_HS
 SG_ EngCylDeactMd : 9|2@0+ (1,0) [0|3] ""  CGM_HS,TCM_HS
 SG_ ParkNeutralSwStatV : 21|1@0+ (1,0) [0|1] ""  CGM_HS,TCM_HS
 SG_ ParkNeutralSwStat : 22|1@0+ (1,0) [0|1] ""  CGM_HS,TCM_HS
 SG_ EngColdHiIdleActive : 23|1@0+ (1,0) [0|1] ""  CGM_HS,TCM_HS
 SG_ EngCyDactTqSmtAct : 6|1@0+ (1,0) [0|1] ""  CGM_HS,TCM_HS
 SG_ EngBrkStat : 15|2@0+ (1,0) [0|3] ""  CGM_HS,TCM_HS
 SG_ TracCntlSysPwrtrnInhbt : 12|1@0+ (1,0) [0|1] ""  CGM_HS,TCM_HS
 SG_ EngMtlProtAtv : 11|1@0+ (1,0) [0|1] ""  CGM_HS,TCM_HS
 SG_ EngDgTrqCnvClUnlkRqd : 7|1@0+ (1,0) [0|1] ""  CGM_HS,TCM_HS
 SG_ EngCyldrDeactReqd : 10|1@0+ (1,0) [0|1] ""  CGM_HS,TCM_HS
 SG_ ETGRReqdGear : 3|4@0+ (1,0) [0|15] ""  CGM_HS,TCM_HS
 SG_ ETGRReqType : 5|2@0+ (1,0) [0|3] ""  CGM_HS,TCM_HS
 SG_ ACCmCltEngd : 13|1@0+ (1,0) [0|1] ""  CGM_HS,TCM_HS,BCM_HS

BO_ 1233 PPEI_Engine_General_Status_5: 8 ECM_HS
 SG_ a_12VBatSysUnstab : 30|1@0+ (1,0) [0|1] ""  BCM_HS,CGM_HS
 SG_ PTExPrtclFltWrng3IO : 63|1@0+ (1,0) [0|1] ""  CGM_HS,BCM_HS
 SG_ PTExPartFltManRegStat : 62|3@0+ (1,0) [0|7] ""  CGM_HS,BCM_HS
 SG_ EngShtdwnAct : 48|1@0+ (1,0) [0|1] ""  CGM_HS,BCM_HS
 SG_ EngShtdwnPndgIO : 49|1@0+ (1,0) [0|1] ""  CGM_HS,BCM_HS
 SG_ FuelFltChgNwIO : 51|1@0+ (1,0) [0|1] ""  CGM_HS,BCM_HS
 SG_ PTExPrtclFltrWrn2IO : 50|1@0+ (1,0) [0|1] ""  CGM_HS,BCM_HS
 SG_ PTHiElecLdReqd : 52|1@0+ (1,0) [0|1] ""  CGM_HS,BCM_HS
 SG_ PTExPrtclFltrWrnIO : 53|1@0+ (1,0) [0|1] ""  CGM_HS,BCM_HS
 SG_ AirCndOffIO : 0|1@0+ (1,0) [0|1] ""  CGM_HS,BCM_HS
 SG_ DslGlwPlgIO : 55|1@0+ (1,0) [0|1] ""  CGM_HS,BCM_HS
 SG_ RdcdPwrIO : 31|1@0+ (1,0) [0|1] ""  CGM_HS,BCM_HS
 SG_ FuelTotCap : 27|12@0+ (0.125,0) [0|511.875] "liters"  CGM_HS,BCM_HS
 SG_ FlLvlPctV : 28|1@0+ (1,0) [0|1] ""  CGM_HS,BCM_HS
 SG_ FlLvlPct : 47|8@0+ (0.392157,0) [0|100.000035] "%"  CGM_HS,BCM_HS
 SG_ EngWtrInFlIO : 54|1@0+ (1,0) [0|1] ""  CGM_HS,BCM_HS
 SG_ EngOilTmpV : 7|1@0+ (1,0) [0|1] ""  CGM_HS,EPS_HS,BCM_HS
 SG_ EngOilTmp : 15|8@0+ (1,-40) [-40|215] "deg C"  CGM_HS,EPS_HS,BCM_HS
 SG_ EngOilPrsV : 6|1@0+ (1,0) [0|1] ""  CGM_HS,BCM_HS
 SG_ EngOilPrsLwIO : 5|1@0+ (1,0) [0|1] ""  CGM_HS,BCM_HS
 SG_ EngOilPrs : 23|8@0+ (4,0) [0|1020] "kPa"  CGM_HS,BCM_HS
 SG_ EngOilLvlLwIO : 4|1@0+ (1,0) [0|1] ""  CGM_HS,BCM_HS
 SG_ EngOilChngIO : 3|1@0+ (1,0) [0|1] ""  CGM_HS,BCM_HS
 SG_ EngHt_StpEngIO : 1|1@0+ (1,0) [0|1] ""  CGM_HS,BCM_HS
 SG_ EngHotFuelEnrchmntIO : 2|1@0+ (1,0) [0|1] ""  CGM_HS,BCM_HS
 SG_ CkFlFilrCapIO : 29|1@0+ (1,0) [0|1] ""  CGM_HS,BCM_HS

BO_ 1217 PPEI_Engine_General_Status_4: 8 ECM_HS
 SG_ LDMaxEngCltTmpRchd : 55|1@0+ (1,0) [0|1] ""  CGM_HS,TCM_HS
 SG_ LDMinEngCltTmpRchd : 43|1@0+ (1,0) [0|1] ""  CGM_HS,TCM_HS
 SG_ CdClrInhbt : 42|1@0+ (1,0) [0|1] ""  CGM_HS,TCM_HS,EBCM_HS,BSM_HS
 SG_ LegPstDTCClrDrvCyCm : 40|1@0+ (1,0) [0|1] ""  CGM_HS,TCM_HS,EBCM_HS,BSM_HS
 SG_ EngIntAirTmpM : 44|1@0+ (1,0) [0|1] ""  CGM_HS,TCM_HS,BSM_HS
 SG_ LegDiagColdStCndMet : 47|1@0+ (1,0) [0|1] ""  CGM_HS,TCM_HS,EBCM_HS,BSM_HS
 SG_ LegDiagColdStCndFltPr : 46|1@0+ (1,0) [0|1] ""  CGM_HS,TCM_HS,EBCM_HS,BSM_HS
 SG_ LegDiagStndCndMet : 2|1@0+ (1,0) [0|1] ""  CGM_HS,TCM_HS,EBCM_HS,BSM_HS
 SG_ LegDiagStndCndFltPr : 1|1@0+ (1,0) [0|1] ""  CGM_HS,TCM_HS,EBCM_HS,BSM_HS
 SG_ EngWrmUpAch : 0|1@0+ (1,0) [0|1] ""  CGM_HS,TCM_HS,EBCM_HS,BSM_HS
 SG_ DslExhFldRmngDstHRsV : 41|1@0+ (1,0) [0|1] ""  CGM_HS,BCM_HS
 SG_ DslExhFldRmngDstHRs : 54|15@0+ (2,0) [0|65534] "km"  CGM_HS,BCM_HS
 SG_ EngOilHotIO : 45|1@0+ (1,0) [0|1] ""  CGM_HS,BCM_HS
 SG_ OAT_PT_EstV : 3|1@0+ (1,0) [0|1] ""  CGM_HS,TCM_HS,RDCM_HS,EBCM_HS,BSM_HS,BCM_HS
 SG_ OAT_PT_EstM : 4|1@0+ (1,0) [0|1] ""  CGM_HS,TCM_HS,RDCM_HS,EBCM_HS,BSM_HS,BCM_HS
 SG_ OAT_PT_Est : 39|8@0+ (0.5,-40) [-40|87.5] "deg C"  CGM_HS,TCM_HS,RDCM_HS,EBCM_HS,BSM_HS,BCM_HS
 SG_ EngIntAirTmpV : 5|1@0+ (1,0) [0|1] ""  CGM_HS,TCM_HS,RDCM_HS,EBCM_HS,BSM_HS,BCM_HS
 SG_ EngIntAirTmp : 31|8@0+ (1,-40) [-40|215] "deg C"  CGM_HS,TCM_HS,RDCM_HS,EBCM_HS,BSM_HS,BCM_HS
 SG_ EngCltTmpV : 6|1@0+ (1,0) [0|1] ""  CGM_HS,TCM_HS,EPS_HS,EBCM_HS,BSM_HS,BCM_HS
 SG_ EngCltTmp : 23|8@0+ (1,-40) [-40|215] "deg C"  CGM_HS,TCM_HS,EPS_HS,EBCM_HS,BSM_HS,BCM_HS
 SG_ BarPrsAbsV : 7|1@0+ (1,0) [0|1] ""  CGM_HS,TCM_HS,EBCM_HS,BSM_HS,BCM_HS
 SG_ BarPrsAbs : 15|8@0+ (0.5,0) [0|127.5] "kPa"  CGM_HS,TCM_HS,EBCM_HS,BSM_HS,BCM_HS

BO_ 665 PTEI_Bkup_Alt_Fuel_Syst_Cmd_HS: 6 ECM_HS
 SG_ EngFuelCntlState_299 : 47|2@0+ (1,0) [0|3] ""  CGM_HS
 SG_ TotAltFClsLpCBn2LwRes : 39|8@0- (0.0078125,0) [-1|0.9921875] ""  CGM_HS
 SG_ TotAltFClsLpCBn1LwRes : 15|8@0- (0.0078125,0) [-1|0.9921875] ""  CGM_HS
 SG_ RelBsAltFuelMassLwRes : 31|8@0+ (0.00390625,0) [0|0.99609375] ""  CGM_HS
 SG_ RdGasFuelDsblAct : 7|1@0+ (1,0) [0|1] ""  CGM_HS
 SG_ RdDistFuelMdCmd : 2|3@0+ (1,0) [0|7] ""  CGM_HS
 SG_ PetrolFuelSysReqAval : 4|2@0+ (1,0) [0|3] ""  CGM_HS
 SG_ AltFuelSysReqAlwd : 5|1@0+ (1,0) [0|1] ""  CGM_HS
 SG_ AltFuelInjHCmdLwRes : 16|1@0+ (1,0) [0|1] ""  CGM_HS
 SG_ AltFuelInjGCmdLwRes : 17|1@0+ (1,0) [0|1] ""  CGM_HS
 SG_ AltFuelInjFCmdLwRes : 18|1@0+ (1,0) [0|1] ""  CGM_HS
 SG_ AltFuelInjECmdLwRes : 19|1@0+ (1,0) [0|1] ""  CGM_HS
 SG_ AltFuelInjDCmdLwRes : 20|1@0+ (1,0) [0|1] ""  CGM_HS
 SG_ AltFuelInjCCmdLwRes : 21|1@0+ (1,0) [0|1] ""  CGM_HS
 SG_ AltFuelInjBCmdLwRes : 22|1@0+ (1,0) [0|1] ""  CGM_HS
 SG_ AltFuelInjACmdLwRes : 23|1@0+ (1,0) [0|1] ""  CGM_HS
 SG_ BiFuelRflGaslinIndReq : 45|3@0+ (1,0) [0|7] ""  CGM_HS,BCM_HS

BO_TX_BU_ 463 : RDCM_HS,ECM_HS;
BO_TX_BU_ 328 : EPS_HS,EBCM_HS;
BO_TX_BU_ 485 : EPS_HS,EBCM_HS;
CM_ BO_ 869 "EOCM algorithm will transmit this message at a 40 ms periodic rate";
CM_ SG_ 532 BrkSysAutBrkFld "BrakeSystemAutomaticBrakingFailed";
CM_ SG_ 532 IntBrkAssPreFilReq "IntelligentBrakeAssistPreFillRequest";
CM_ BO_ 880 "EOCM algorithm will transmit this message at a 40 ms periodic rate";
CM_ SG_ 880 ACCHdwyStg "Headway is the  time which results from dividing the following distance (or gap) between vehicles by the vehicle speed.  This setting allows the driver to choose a Headway Setting without actually knowing the value of this time.";
CM_ BO_ 485 "6443-Power Steering Indication On in this frame not used by GlobalA /JD";
CM_ SG_ 417 DslPrtFltrIdlRgtnMdReq "Diesel signal could be shared with a Gasoline application";
CM_ SG_ 417 DslPartFltrClngAlgActM "Diesel signal could be shared with a Gasoline application";
CM_ SG_ 417 DslPartFltrClngAlgAct "Diesel signal could be shared with a Gasoline application";
CM_ SG_ 417 TracCntlSysPwrtrnInhbt "ETEI 3.1";
BA_DEF_ SG_  "GenSigSendOnInit" ENUM  "Not Initialized","Application","Handler","DLCLS","DLCHS","DLCCE","DLCFO";
BA_DEF_ SG_  "GenSigSendType" ENUM  "not used","not used","not used","not used","not used","not used","not used","NoSigSendType","not used","not used","OnAnyChange","OnChangeIfActive","OnDelta","DLCLS","DLCHS","DLCCE","DLCFO";
BA_DEF_ SG_  "GenSigDeltaValue" INT 0 0;
BA_DEF_ SG_  "VNSigAllNodes" ENUM  "No","Yes","DLCLS","DLCHS","DLCCE","DLCFO";
BA_DEF_ SG_  "VNSigSLHSSharedDiagnostic" ENUM  "No","Yes","DLCLS","DLCHS","DLCCE","DLCFO";
BA_DEF_ SG_  "VNSigSLHS_VNReq" ENUM  "No","Yes","DLCLS","DLCHS","DLCCE","DLCFO";
BA_DEF_ SG_  "SignalType" STRING ;
BA_DEF_ SG_  "PacketOrder" INT 0 65535;
BA_DEF_ SG_  "SignalLongName" STRING ;
BA_DEF_ SG_  "GenSigStartValue" INT 0 65535;
BA_DEF_ SG_  "TxSignalSendOnInit" ENUM  "Not Initialized","Application","Handler";
BA_DEF_ BO_  "GenMsgILSupport" ENUM  "No","Yes","DLCLS","DLCHS","DLCCE","DLCFO";
BA_DEF_ BO_  "AppGenMsgCycleTime" INT 0 0;
BA_DEF_ BO_  "TpApplType" STRING ;
BA_DEF_ BO_  "Prio" INT 0 7;
BA_DEF_ BO_  "MessageSubnet" ENUM  "LS","MS","HS","CE","PE","HV","FO","S1","HE","LE","HE2","DLCLS","DLCHS","DLCCE","DLCFO","vector_leerstring";
BA_DEF_ BO_  "DiagState" ENUM  "No","Yes";
BA_DEF_ BO_  "GenMsgIlSupport" ENUM  "No","Yes";
BA_DEF_ BO_  "GenMsgStartDelayTime" INT 0 100000;
BA_DEF_ BO_  "GenMsgDelayTime" INT 0 100000;
BA_DEF_ BO_  "GenMsgCycleTime" INT 0 100000;
BA_DEF_ BO_  "GenMsgSendType" ENUM  "cyclicX","spontanX","cyclicIfActiveX","spontanWithDelay","cyclicAndSpontanX","cyclicAndSpontanWithDelay","spontanWithRepitition","cyclicIfActiveAndSpontanWD";
BA_DEF_ BO_  "DiagResponse" ENUM  "No","Yes";
BA_DEF_ BO_  "DiagRequest" ENUM  "No","Yes";
BA_DEF_ BO_  "NmMessage" ENUM  "No","Yes";
BA_DEF_REL_ BU_SG_REL_  "GenSigSuprvResp" ENUM  "None","Notify App","Substitute Default","DLCLS","DLCHS","DLCCE","DLCFO";
BA_DEF_REL_ BU_SG_REL_  "GenSigSuprvRespSubValue" INT 0 65535;
BA_DEF_REL_ BU_SG_REL_  "GenSigRxStartValue" STRING ;
BA_DEF_REL_ BU_SG_REL_  "GenSigVDAFailResp" ENUM  "No","Yes","DLCLS","DLCHS","DLCCE","DLCFO";
BA_DEF_REL_ BU_SG_REL_  "GenSigVDAFailComment" STRING ;
BA_DEF_REL_ BU_SG_REL_  "GenSigVBitRespComment" STRING ;
BA_DEF_REL_ BU_SG_REL_  "GenSigVBitResp" ENUM  "No","Yes","DLCLS","DLCHS","DLCCE","DLCFO";
BA_DEF_REL_ BU_SG_REL_  "GenSigSuprvRespComment" STRING ;
BA_DEF_REL_ BU_SG_REL_  "GenSigTimeoutMsg" HEX 0 268435455;
BA_DEF_REL_ BU_SG_REL_  "GenSigTimeoutTime" INT 0 5000;
BA_DEF_DEF_  "GenSigSendOnInit" "Not Initialized";
BA_DEF_DEF_  "GenSigSendType" "NoSigSendType";
BA_DEF_DEF_  "GenSigDeltaValue" 0;
BA_DEF_DEF_  "VNSigAllNodes" "No";
BA_DEF_DEF_  "VNSigSLHSSharedDiagnostic" "No";
BA_DEF_DEF_  "VNSigSLHS_VNReq" "No";
BA_DEF_DEF_  "SignalType" "";
BA_DEF_DEF_  "PacketOrder" 0;
BA_DEF_DEF_  "SignalLongName" "";
BA_DEF_DEF_  "GenSigStartValue" 0;
BA_DEF_DEF_  "TxSignalSendOnInit" "Not Initialized";
BA_DEF_DEF_  "GenMsgILSupport" "Yes";
BA_DEF_DEF_  "AppGenMsgCycleTime" 0;
BA_DEF_DEF_  "TpApplType" "";
BA_DEF_DEF_  "Prio" 0;
BA_DEF_DEF_  "MessageSubnet" "LS";
BA_DEF_DEF_  "DiagState" "No";
BA_DEF_DEF_  "GenMsgIlSupport" "Yes";
BA_DEF_DEF_  "GenMsgStartDelayTime" 0;
BA_DEF_DEF_  "GenMsgDelayTime" 0;
BA_DEF_DEF_  "GenMsgCycleTime" 0;
BA_DEF_DEF_  "GenMsgSendType" "spontanX";
BA_DEF_DEF_  "DiagResponse" "No";
BA_DEF_DEF_  "DiagRequest" "No";
BA_DEF_DEF_  "NmMessage" "No";
BA_DEF_DEF_REL_ "GenSigSuprvResp" "None";
BA_DEF_DEF_REL_ "GenSigSuprvRespSubValue" 0;
BA_DEF_DEF_REL_ "GenSigRxStartValue" "";
BA_DEF_DEF_REL_ "GenSigVDAFailResp" "No";
BA_DEF_DEF_REL_ "GenSigVDAFailComment" "";
BA_DEF_DEF_REL_ "GenSigVBitRespComment" "";
BA_DEF_DEF_REL_ "GenSigVBitResp" "No";
BA_DEF_DEF_REL_ "GenSigSuprvRespComment" "";
BA_DEF_DEF_REL_ "GenSigTimeoutMsg" 0;
BA_DEF_DEF_REL_ "GenSigTimeoutTime" 0;
BA_ "GenMsgSendType" BO_ 463 0;
BA_ "GenMsgCycleTime" BO_ 463 100;
BA_ "MessageSubnet" BO_ 463 2;
BA_ "MessageSubnet" BO_ 869 2;
BA_ "AppGenMsgCycleTime" BO_ 869 40;
BA_ "GenMsgSendType" BO_ 564 0;
BA_ "GenMsgCycleTime" BO_ 564 100;
BA_ "MessageSubnet" BO_ 564 2;
BA_ "GenMsgSendType" BO_ 1296 0;
BA_ "GenMsgCycleTime" BO_ 1296 100;
BA_ "MessageSubnet" BO_ 1296 2;
BA_ "GenMsgSendType" BO_ 848 0;
BA_ "GenMsgCycleTime" BO_ 848 50;
BA_ "MessageSubnet" BO_ 848 2;
BA_ "GenMsgSendType" BO_ 1011 0;
BA_ "GenMsgCycleTime" BO_ 1011 250;
BA_ "MessageSubnet" BO_ 1011 2;
BA_ "GenMsgSendType" BO_ 993 0;
BA_ "GenMsgCycleTime" BO_ 993 100;
BA_ "MessageSubnet" BO_ 993 2;
BA_ "GenMsgSendType" BO_ 490 0;
BA_ "GenMsgCycleTime" BO_ 490 12;
BA_ "MessageSubnet" BO_ 490 2;
BA_ "GenMsgSendType" BO_ 452 0;
BA_ "GenMsgCycleTime" BO_ 452 25;
BA_ "MessageSubnet" BO_ 452 2;
BA_ "GenMsgSendType" BO_ 1280 0;
BA_ "GenMsgCycleTime" BO_ 1280 1000;
BA_ "MessageSubnet" BO_ 1280 2;
BA_ "GenMsgSendType" BO_ 562 0;
BA_ "GenMsgCycleTime" BO_ 562 50;
BA_ "MessageSubnet" BO_ 562 2;
BA_ "GenMsgSendType" BO_ 386 0;
BA_ "GenMsgCycleTime" BO_ 386 100;
BA_ "MessageSubnet" BO_ 386 2;
BA_ "GenMsgSendType" BO_ 532 0;
BA_ "GenMsgCycleTime" BO_ 532 50;
BA_ "MessageSubnet" BO_ 532 2;
BA_ "GenMsgSendType" BO_ 328 0;
BA_ "GenMsgCycleTime" BO_ 328 1000;
BA_ "GenMsgDelayTime" BO_ 328 100;
BA_ "MessageSubnet" BO_ 328 2;
BA_ "GenMsgSendType" BO_ 560 0;
BA_ "GenMsgCycleTime" BO_ 560 50;
BA_ "MessageSubnet" BO_ 560 2;
BA_ "GenMsgSendType" BO_ 451 0;
BA_ "GenMsgCycleTime" BO_ 451 25;
BA_ "MessageSubnet" BO_ 451 2;
BA_ "GenMsgSendType" BO_ 1282 0;
BA_ "GenMsgCycleTime" BO_ 1282 500;
BA_ "MessageSubnet" BO_ 1282 2;
BA_ "MessageSubnet" BO_ 2033 2;
BA_ "MessageSubnet" BO_ 880 2;
BA_ "AppGenMsgCycleTime" BO_ 880 40;
BA_ "DiagRequest" BO_ 577 1;
BA_ "MessageSubnet" BO_ 577 2;
BA_ "GenMsgSendType" BO_ 485 0;
BA_ "GenMsgCycleTime" BO_ 485 10;
BA_ "MessageSubnet" BO_ 485 2;
BA_ "GenMsgSendType" BO_ 1001 0;
BA_ "GenMsgCycleTime" BO_ 1001 100;
BA_ "MessageSubnet" BO_ 1001 2;
BA_ "GenMsgSendType" BO_ 961 0;
BA_ "GenMsgCycleTime" BO_ 961 100;
BA_ "MessageSubnet" BO_ 961 2;
BA_ "GenMsgSendType" BO_ 842 0;
BA_ "GenMsgCycleTime" BO_ 842 50;
BA_ "MessageSubnet" BO_ 842 2;
BA_ "GenMsgSendType" BO_ 1019 0;
BA_ "GenMsgCycleTime" BO_ 1019 250;
BA_ "MessageSubnet" BO_ 1019 2;
BA_ "GenMsgSendType" BO_ 1265 0;
BA_ "GenMsgCycleTime" BO_ 1265 1000;
BA_ "MessageSubnet" BO_ 1265 2;
BA_ "GenMsgSendType" BO_ 417 0;
BA_ "GenMsgCycleTime" BO_ 417 25;
BA_ "MessageSubnet" BO_ 417 2;
BA_ "GenMsgSendType" BO_ 1233 0;
BA_ "GenMsgCycleTime" BO_ 1233 500;
BA_ "MessageSubnet" BO_ 1233 2;
BA_ "GenMsgSendType" BO_ 1217 0;
BA_ "GenMsgCycleTime" BO_ 1217 500;
BA_ "MessageSubnet" BO_ 1217 2;
BA_ "GenMsgSendType" BO_ 665 0;
BA_ "GenMsgCycleTime" BO_ 665 100;
BA_ "MessageSubnet" BO_ 665 2;
BA_ "SignalLongName" SG_ 463 SecAxlOpMdARC "Secondary Axle Operational Mode Alive Rolling Count";
BA_ "SignalType" SG_ 463 SecAxlOpMdARC "UNM";
BA_ "VNSigAllNodes" SG_ 463 SecAxlOpMdARC 1;
BA_ "SignalLongName" SG_ 463 FourWhlDrvIdReqExtRng "Four Wheel Drive Indication Request Extended Range";
BA_ "SignalType" SG_ 463 FourWhlDrvIdReqExtRng "ENM";
BA_ "VNSigAllNodes" SG_ 463 FourWhlDrvIdReqExtRng 1;
BA_ "GenSigSendType" SG_ 463 FourWhlDrvIdReqExtRng 10;
BA_ "GenSigSendOnInit" SG_ 463 FourWhlDrvIdReqExtRng 2;
BA_ "SignalLongName" SG_ 463 FourWhlDrvIndReq "Four Wheel Drive Indication Request";
BA_ "SignalType" SG_ 463 FourWhlDrvIndReq "ENM";
BA_ "VNSigAllNodes" SG_ 463 FourWhlDrvIndReq 1;
BA_ "SignalLongName" SG_ 463 TrnsfrCsRngShfSpdLmt "Transfer Case Range Shift Speed Limit";
BA_ "SignalType" SG_ 463 TrnsfrCsRngShfSpdLmt "UNM";
BA_ "VNSigAllNodes" SG_ 463 TrnsfrCsRngShfSpdLmt 1;
BA_ "SignalLongName" SG_ 463 SecAxlNonEmMalfIO "Secondary Axle Non-emissions Malf Ind On";
BA_ "SignalType" SG_ 463 SecAxlNonEmMalfIO "BLN";
BA_ "VNSigAllNodes" SG_ 463 SecAxlNonEmMalfIO 1;
BA_ "SignalLongName" SG_ 463 SecAxlOperMod "Secondary Axle Operational Mode";
BA_ "SignalType" SG_ 463 SecAxlOperMod "ENM";
BA_ "VNSigAllNodes" SG_ 463 SecAxlOperMod 1;
BA_ "SignalLongName" SG_ 463 SecAxlTmpInhIO "Secondary Axle Temporary Inhibit Indication On";
BA_ "SignalType" SG_ 463 SecAxlTmpInhIO "BLN";
BA_ "VNSigAllNodes" SG_ 463 SecAxlTmpInhIO 1;
BA_ "SignalLongName" SG_ 869 TnDrvGapAdjUnbIO "Teen Driver Gap Adjust Unavailable Indication On";
BA_ "SignalType" SG_ 869 TnDrvGapAdjUnbIO "BLN";
BA_ "VNSigAllNodes" SG_ 869 TnDrvGapAdjUnbIO 1;
BA_ "GenSigSendType" SG_ 869 TnDrvGapAdjUnbIO 10;
BA_ "SignalLongName" SG_ 869 CPSCA_Resrv3Avail "Collision Preparation System Customization Available : Reserved3 Available";
BA_ "PacketOrder" SG_ 869 CPSCA_Resrv3Avail 7;
BA_ "SignalType" SG_ 869 CPSCA_Resrv3Avail "BLN";
BA_ "VNSigAllNodes" SG_ 869 CPSCA_Resrv3Avail 1;
BA_ "GenSigSendType" SG_ 869 CPSCA_Resrv3Avail 10;
BA_ "GenSigSendOnInit" SG_ 869 CPSCA_Resrv3Avail 1;
BA_ "SignalLongName" SG_ 869 CPSCA_Resrv2Avail "Collision Preparation System Customization Available : Reserved2 Available";
BA_ "PacketOrder" SG_ 869 CPSCA_Resrv2Avail 6;
BA_ "SignalType" SG_ 869 CPSCA_Resrv2Avail "BLN";
BA_ "VNSigAllNodes" SG_ 869 CPSCA_Resrv2Avail 1;
BA_ "GenSigSendType" SG_ 869 CPSCA_Resrv2Avail 10;
BA_ "GenSigSendOnInit" SG_ 869 CPSCA_Resrv2Avail 1;
BA_ "SignalLongName" SG_ 869 CPSCA_Resrv1Avail "Collision Preparation System Customization Available : Reserved1 Available";
BA_ "PacketOrder" SG_ 869 CPSCA_Resrv1Avail 5;
BA_ "SignalType" SG_ 869 CPSCA_Resrv1Avail "BLN";
BA_ "VNSigAllNodes" SG_ 869 CPSCA_Resrv1Avail 1;
BA_ "GenSigSendType" SG_ 869 CPSCA_Resrv1Avail 10;
BA_ "GenSigSendOnInit" SG_ 869 CPSCA_Resrv1Avail 1;
BA_ "SignalLongName" SG_ 869 CPSCA_AlrtBrkStrAvail "Collision Preparation System Customization Available : Alert and Brake and Steer Available";
BA_ "PacketOrder" SG_ 869 CPSCA_AlrtBrkStrAvail 4;
BA_ "SignalType" SG_ 869 CPSCA_AlrtBrkStrAvail "BLN";
BA_ "VNSigAllNodes" SG_ 869 CPSCA_AlrtBrkStrAvail 1;
BA_ "GenSigSendType" SG_ 869 CPSCA_AlrtBrkStrAvail 10;
BA_ "GenSigSendOnInit" SG_ 869 CPSCA_AlrtBrkStrAvail 1;
BA_ "GenSigStartValue" SG_ 869 CPSCA_AlrtBrkAvail 1;
BA_ "SignalLongName" SG_ 869 CPSCA_AlrtBrkAvail "Collision Preparation System Customization Available : Alert and Brake Available";
BA_ "PacketOrder" SG_ 869 CPSCA_AlrtBrkAvail 3;
BA_ "SignalType" SG_ 869 CPSCA_AlrtBrkAvail "BLN";
BA_ "VNSigAllNodes" SG_ 869 CPSCA_AlrtBrkAvail 1;
BA_ "GenSigSendType" SG_ 869 CPSCA_AlrtBrkAvail 10;
BA_ "GenSigSendOnInit" SG_ 869 CPSCA_AlrtBrkAvail 1;
BA_ "GenSigStartValue" SG_ 869 CPSCA_AlrtAvail 1;
BA_ "SignalLongName" SG_ 869 CPSCA_AlrtAvail "Collision Preparation System Customization Available : Alert Available";
BA_ "PacketOrder" SG_ 869 CPSCA_AlrtAvail 2;
BA_ "SignalType" SG_ 869 CPSCA_AlrtAvail "BLN";
BA_ "VNSigAllNodes" SG_ 869 CPSCA_AlrtAvail 1;
BA_ "GenSigSendType" SG_ 869 CPSCA_AlrtAvail 10;
BA_ "GenSigSendOnInit" SG_ 869 CPSCA_AlrtAvail 1;
BA_ "GenSigStartValue" SG_ 869 CPSCA_OffAvail 1;
BA_ "SignalLongName" SG_ 869 CPSCA_OffAvail "Collision Preparation System Customization Available : Off Available";
BA_ "PacketOrder" SG_ 869 CPSCA_OffAvail 1;
BA_ "SignalType" SG_ 869 CPSCA_OffAvail "BLN";
BA_ "VNSigAllNodes" SG_ 869 CPSCA_OffAvail 1;
BA_ "GenSigSendType" SG_ 869 CPSCA_OffAvail 10;
BA_ "GenSigSendOnInit" SG_ 869 CPSCA_OffAvail 1;
BA_ "SignalLongName" SG_ 869 FwdClnMtgnBrkReqAct "Forward Collision Mitigation Braking Request Active";
BA_ "SignalType" SG_ 869 FwdClnMtgnBrkReqAct "BLN";
BA_ "VNSigAllNodes" SG_ 869 FwdClnMtgnBrkReqAct 1;
BA_ "GenSigSendType" SG_ 869 FwdClnMtgnBrkReqAct 10;
BA_ "SignalLongName" SG_ 869 FCACustStngAvlbl "Forward Collision Alert Customization Setting Available";
BA_ "SignalType" SG_ 869 FCACustStngAvlbl "BLN";
BA_ "VNSigAllNodes" SG_ 869 FCACustStngAvlbl 1;
BA_ "GenSigSendType" SG_ 869 FCACustStngAvlbl 10;
BA_ "GenSigSendOnInit" SG_ 869 FCACustStngAvlbl 2;
BA_ "SignalLongName" SG_ 869 FwdClnAlrtCustCrntSetngVal "Forward Collision Alert Customization Current Setting Value";
BA_ "SignalType" SG_ 869 FwdClnAlrtCustCrntSetngVal "ENM";
BA_ "VNSigAllNodes" SG_ 869 FwdClnAlrtCustCrntSetngVal 1;
BA_ "GenSigSendType" SG_ 869 FwdClnAlrtCustCrntSetngVal 10;
BA_ "GenSigSendOnInit" SG_ 869 FwdClnAlrtCustCrntSetngVal 2;
BA_ "SignalLongName" SG_ 869 GNCustSetngAvlbl "Go Notifier Customization Setting Available";
BA_ "SignalType" SG_ 869 GNCustSetngAvlbl "BLN";
BA_ "VNSigAllNodes" SG_ 869 GNCustSetngAvlbl 1;
BA_ "SignalLongName" SG_ 869 CPSUnblIO "Collision Preparation System Unavailable Indication On";
BA_ "SignalType" SG_ 869 CPSUnblIO "BLN";
BA_ "VNSigAllNodes" SG_ 869 CPSUnblIO 1;
BA_ "SignalLongName" SG_ 869 ColPrSysStngAvl "Collision Preparation System Setting Available";
BA_ "SignalType" SG_ 869 ColPrSysStngAvl "BLN";
BA_ "VNSigAllNodes" SG_ 869 ColPrSysStngAvl 1;
BA_ "SignalLongName" SG_ 869 CPSOffIO "Collision Preparation System Off Indication On";
BA_ "SignalType" SG_ 869 CPSOffIO "BLN";
BA_ "VNSigAllNodes" SG_ 869 CPSOffIO 1;
BA_ "SignalLongName" SG_ 869 CPSFldIO "Collision Preparation System Failed Indication On";
BA_ "SignalType" SG_ 869 CPSFldIO "BLN";
BA_ "VNSigAllNodes" SG_ 869 CPSFldIO 1;
BA_ "SignalLongName" SG_ 869 ColPrSysCrntStng "Collision Preparation System Current Setting Value";
BA_ "SignalType" SG_ 869 ColPrSysCrntStng "ENM";
BA_ "VNSigAllNodes" SG_ 869 ColPrSysCrntStng 1;
BA_ "SignalLongName" SG_ 869 CPSAlrtOnlIO "Collision Preparation System Alert Only Indication On";
BA_ "SignalType" SG_ 869 CPSAlrtOnlIO "BLN";
BA_ "VNSigAllNodes" SG_ 869 CPSAlrtOnlIO 1;
BA_ "SignalLongName" SG_ 869 GNCustCrntStngVal "Go Notifier Customization Current Setting Value";
BA_ "SignalType" SG_ 869 GNCustCrntStngVal "ENM";
BA_ "VNSigAllNodes" SG_ 869 GNCustCrntStngVal 1;
BA_ "SignalLongName" SG_ 564 AdptDrvrSeatStng "Adaptive Driver Seat Setting";
BA_ "SignalType" SG_ 564 AdptDrvrSeatStng "ENM";
BA_ "VNSigAllNodes" SG_ 564 AdptDrvrSeatStng 1;
BA_ "SignalLongName" SG_ 564 AdptPsngrSeatStng "Adaptive Passenger Seat Setting";
BA_ "SignalType" SG_ 564 AdptPsngrSeatStng "ENM";
BA_ "VNSigAllNodes" SG_ 564 AdptPsngrSeatStng 1;
BA_ "SignalLongName" SG_ 564 TnDrvTrCtrlOffUnbIO "Teen Driver Traction Control Off Unavailable Indication On";
BA_ "SignalType" SG_ 564 TnDrvTrCtrlOffUnbIO "BLN";
BA_ "VNSigAllNodes" SG_ 564 TnDrvTrCtrlOffUnbIO 1;
BA_ "GenSigSendType" SG_ 564 TnDrvTrCtrlOffUnbIO 10;
BA_ "SignalLongName" SG_ 564 TnDrvStblCtrlOffUnbIO "Teen Driver Stability Control Off Unavailable Indication On";
BA_ "SignalType" SG_ 564 TnDrvStblCtrlOffUnbIO "BLN";
BA_ "VNSigAllNodes" SG_ 564 TnDrvStblCtrlOffUnbIO 1;
BA_ "GenSigSendType" SG_ 564 TnDrvStblCtrlOffUnbIO 10;
BA_ "SignalLongName" SG_ 564 VehRollAngleV "Vehicle Roll Angle Validity";
BA_ "SignalType" SG_ 564 VehRollAngleV "ENM";
BA_ "VNSigAllNodes" SG_ 564 VehRollAngleV 1;
BA_ "SignalLongName" SG_ 564 VehRollAngle "Vehicle Roll Angle";
BA_ "SignalType" SG_ 564 VehRollAngle "UNM";
BA_ "VNSigAllNodes" SG_ 564 VehRollAngle 1;
BA_ "SignalLongName" SG_ 564 VehPitchAngleV "Vehicle Pitch Angle Validity";
BA_ "SignalType" SG_ 564 VehPitchAngleV "ENM";
BA_ "VNSigAllNodes" SG_ 564 VehPitchAngleV 1;
BA_ "SignalLongName" SG_ 564 VehPitchAngle "Vehicle Pitch Angle";
BA_ "SignalType" SG_ 564 VehPitchAngle "UNM";
BA_ "VNSigAllNodes" SG_ 564 VehPitchAngle 1;
BA_ "SignalLongName" SG_ 564 RdWhlAngV "Road Wheel Angle Validity";
BA_ "SignalType" SG_ 564 RdWhlAngV "ENM";
BA_ "VNSigAllNodes" SG_ 564 RdWhlAngV 1;
BA_ "SignalLongName" SG_ 564 RdWhlAng "Road Wheel Angle";
BA_ "SignalType" SG_ 564 RdWhlAng "UNM";
BA_ "VNSigAllNodes" SG_ 564 RdWhlAng 1;
BA_ "SignalLongName" SG_ 564 TrlrStabAstActIO "Trailer Stability Assist Active Indication On";
BA_ "SignalType" SG_ 564 TrlrStabAstActIO "BLN";
BA_ "VNSigAllNodes" SG_ 564 TrlrStabAstActIO 1;
BA_ "SignalLongName" SG_ 564 PerfTrcCrnExStngVal "Performance Traction Corner Exit Setting Value";
BA_ "SignalType" SG_ 564 PerfTrcCrnExStngVal "ENM";
BA_ "VNSigAllNodes" SG_ 564 PerfTrcCrnExStngVal 1;
BA_ "SignalLongName" SG_ 1296 ACCAutoSetSpdStat "Adaptive Cruise Control Auto Set Speed Status";
BA_ "SignalType" SG_ 1296 ACCAutoSetSpdStat "ENM";
BA_ "VNSigAllNodes" SG_ 1296 ACCAutoSetSpdStat 1;
BA_ "SignalLongName" SG_ 1296 FwdClnAlrtOffIO "Forward Collision Alert Off Indication On";
BA_ "SignalType" SG_ 1296 FwdClnAlrtOffIO "BLN";
BA_ "VNSigAllNodes" SG_ 1296 FwdClnAlrtOffIO 1;
BA_ "SignalLongName" SG_ 1296 VADIR_IndLvl "Vehicle Ahead Distance Indication Request : Indication Level";
BA_ "PacketOrder" SG_ 1296 VADIR_IndLvl 1;
BA_ "SignalType" SG_ 1296 VADIR_IndLvl "ENM";
BA_ "VNSigAllNodes" SG_ 1296 VADIR_IndLvl 1;
BA_ "GenSigSendType" SG_ 1296 VADIR_IndLvl 10;
BA_ "GenSigSendOnInit" SG_ 1296 VADIR_IndLvl 1;
BA_ "SignalLongName" SG_ 1296 VADIR_FlwTme "Vehicle Ahead Distance Indication Request : Following Time";
BA_ "PacketOrder" SG_ 1296 VADIR_FlwTme 2;
BA_ "SignalType" SG_ 1296 VADIR_FlwTme "UNM";
BA_ "VNSigAllNodes" SG_ 1296 VADIR_FlwTme 1;
BA_ "GenSigDeltaValue" SG_ 1296 VADIR_FlwTme 1;
BA_ "GenSigSendType" SG_ 1296 VADIR_FlwTme 12;
BA_ "GenSigSendOnInit" SG_ 1296 VADIR_FlwTme 1;
BA_ "SignalLongName" SG_ 1296 VADIR_FlwDst "Vehicle Ahead Distance Indication Request : Following Distance";
BA_ "PacketOrder" SG_ 1296 VADIR_FlwDst 3;
BA_ "SignalType" SG_ 1296 VADIR_FlwDst "UNM";
BA_ "VNSigAllNodes" SG_ 1296 VADIR_FlwDst 1;
BA_ "GenSigDeltaValue" SG_ 1296 VADIR_FlwDst 1;
BA_ "GenSigSendType" SG_ 1296 VADIR_FlwDst 12;
BA_ "GenSigSendOnInit" SG_ 1296 VADIR_FlwDst 1;
BA_ "SignalLongName" SG_ 848 TrlrBrkProfStat "Trailer Brake Profile Status";
BA_ "SignalType" SG_ 848 TrlrBrkProfStat "ENM";
BA_ "VNSigAllNodes" SG_ 848 TrlrBrkProfStat 1;
BA_ "SignalLongName" SG_ 848 TrlrBrkStat "Trailer Brake Status";
BA_ "SignalType" SG_ 848 TrlrBrkStat "ENM";
BA_ "VNSigAllNodes" SG_ 848 TrlrBrkStat 1;
BA_ "SignalLongName" SG_ 848 TrlrBrkngSysBrkLtsReq "Trailer Braking System Brake Lights Requested";
BA_ "SignalType" SG_ 848 TrlrBrkngSysBrkLtsReq "BLN";
BA_ "VNSigAllNodes" SG_ 848 TrlrBrkngSysBrkLtsReq 1;
BA_ "SignalLongName" SG_ 848 SrvTrlrBrkngSysIO "ServiceTrailer Braking System Indication On";
BA_ "SignalType" SG_ 848 SrvTrlrBrkngSysIO "BLN";
BA_ "VNSigAllNodes" SG_ 848 SrvTrlrBrkngSysIO 1;
BA_ "SignalLongName" SG_ 848 TrlrWiringFltIO "Trailer Wiring Fault Indication On";
BA_ "SignalType" SG_ 848 TrlrWiringFltIO "BLN";
BA_ "VNSigAllNodes" SG_ 848 TrlrWiringFltIO 1;
BA_ "SignalLongName" SG_ 848 TrlrCnctdIO "Trailer Connected Indication On";
BA_ "SignalType" SG_ 848 TrlrCnctdIO "BLN";
BA_ "VNSigAllNodes" SG_ 848 TrlrCnctdIO 1;
BA_ "SignalLongName" SG_ 848 TrlrBrkngGainSetIO "Trailer Braking Gain Setting Indication On";
BA_ "SignalType" SG_ 848 TrlrBrkngGainSetIO "BLN";
BA_ "VNSigAllNodes" SG_ 848 TrlrBrkngGainSetIO 1;
BA_ "SignalLongName" SG_ 848 TrlrBrkngGainSet "Trailer Braking Gain Setting";
BA_ "SignalType" SG_ 848 TrlrBrkngGainSet "UNM";
BA_ "VNSigAllNodes" SG_ 848 TrlrBrkngGainSet 1;
BA_ "SignalLongName" SG_ 848 TrlrBrkngFrcOtpt "Trailer Braking Force Output";
BA_ "SignalType" SG_ 848 TrlrBrkngFrcOtpt "UNM";
BA_ "VNSigAllNodes" SG_ 848 TrlrBrkngFrcOtpt 1;
BA_ "SignalLongName" SG_ 848 ChkTrlrIO "Check Trailer Indication On";
BA_ "SignalType" SG_ 848 ChkTrlrIO "BLN";
BA_ "VNSigAllNodes" SG_ 848 ChkTrlrIO 1;
BA_ "SignalLongName" SG_ 848 TrlrHtchSwAtv_ITBC "Trailer Hitch Switch Active ITBC";
BA_ "SignalType" SG_ 848 TrlrHtchSwAtv_ITBC "BLN";
BA_ "VNSigAllNodes" SG_ 848 TrlrHtchSwAtv_ITBC 1;
BA_ "SignalLongName" SG_ 1011 BatVltHiResV "Battery Voltage High Resolution Validity";
BA_ "SignalType" SG_ 1011 BatVltHiResV "ENM";
BA_ "VNSigAllNodes" SG_ 1011 BatVltHiResV 1;
BA_ "GenSigStartValue" SG_ 1011 BatVltHiRes 12800;
BA_ "SignalLongName" SG_ 1011 BatVltHiRes "Battery Voltage High Resolution";
BA_ "SignalType" SG_ 1011 BatVltHiRes "UNM";
BA_ "VNSigAllNodes" SG_ 1011 BatVltHiRes 1;
BA_ "SignalLongName" SG_ 1011 BatCrntExtRngV "Battery Current Extended Range Validity";
BA_ "SignalType" SG_ 1011 BatCrntExtRngV "ENM";
BA_ "VNSigAllNodes" SG_ 1011 BatCrntExtRngV 1;
BA_ "SignalLongName" SG_ 1011 BatCrntExtRng "Battery Current Extended Range";
BA_ "SignalType" SG_ 1011 BatCrntExtRng "UNM";
BA_ "VNSigAllNodes" SG_ 1011 BatCrntExtRng 1;
BA_ "SignalLongName" SG_ 1011 BatSnsrlntFlt "Intelligent Battery Sensor Internal Fault";
BA_ "SignalType" SG_ 1011 BatSnsrlntFlt "BLN";
BA_ "VNSigAllNodes" SG_ 1011 BatSnsrlntFlt 1;
BA_ "SignalLongName" SG_ 1011 BatCrntExtRngM "Battery Current Extended Range Mask";
BA_ "SignalType" SG_ 1011 BatCrntExtRngM "ENM";
BA_ "VNSigAllNodes" SG_ 1011 BatCrntExtRngM 1;
BA_ "SignalLongName" SG_ 1011 BatVltHiResM "Battery Voltage High Resolution Mask";
BA_ "SignalType" SG_ 1011 BatVltHiResM "ENM";
BA_ "VNSigAllNodes" SG_ 1011 BatVltHiResM 1;
BA_ "SignalLongName" SG_ 993 HybVehHiVltSysDisbld "Hybrid Vehicle High Voltage System Disabled";
BA_ "SignalType" SG_ 993 HybVehHiVltSysDisbld "BLN";
BA_ "VNSigAllNodes" SG_ 993 HybVehHiVltSysDisbld 1;
BA_ "SignalLongName" SG_ 993 CstmrUsblSOCV "Customer Usable State of Charge Validity";
BA_ "SignalType" SG_ 993 CstmrUsblSOCV "ENM";
BA_ "VNSigAllNodes" SG_ 993 CstmrUsblSOCV 1;
BA_ "GenSigSendType" SG_ 993 CstmrUsblSOCV 10;
BA_ "GenSigSendOnInit" SG_ 993 CstmrUsblSOCV 1;
BA_ "SignalLongName" SG_ 993 CstmrUsblSOC "Customer Usable State of Charge";
BA_ "SignalType" SG_ 993 CstmrUsblSOC "UNM";
BA_ "VNSigAllNodes" SG_ 993 CstmrUsblSOC 1;
BA_ "GenSigDeltaValue" SG_ 993 CstmrUsblSOC 1;
BA_ "GenSigSendType" SG_ 993 CstmrUsblSOC 12;
BA_ "GenSigSendOnInit" SG_ 993 CstmrUsblSOC 1;
BA_ "SignalLongName" SG_ 993 InstDrvEff "Instantaneous Drive Efficiency";
BA_ "SignalType" SG_ 993 InstDrvEff "SNM";
BA_ "VNSigAllNodes" SG_ 993 InstDrvEff 1;
BA_ "GenSigDeltaValue" SG_ 993 InstDrvEff 1;
BA_ "GenSigSendType" SG_ 993 InstDrvEff 12;
BA_ "GenSigSendOnInit" SG_ 993 InstDrvEff 1;
BA_ "SignalLongName" SG_ 993 PwrPckAirInTempFlt "Power Pack Air Inlet Temperature Filtered";
BA_ "SignalType" SG_ 993 PwrPckAirInTempFlt "UNM";
BA_ "VNSigAllNodes" SG_ 993 PwrPckAirInTempFlt 1;
BA_ "SignalLongName" SG_ 993 PwrPkFnSpd "Power Pack Fan Speed";
BA_ "SignalType" SG_ 993 PwrPkFnSpd "UNM";
BA_ "VNSigAllNodes" SG_ 993 PwrPkFnSpd 1;
BA_ "SignalLongName" SG_ 993 JmpStrtStat "Jump Start Status";
BA_ "SignalType" SG_ 993 JmpStrtStat "ENM";
BA_ "VNSigAllNodes" SG_ 993 JmpStrtStat 1;
BA_ "GenSigSendType" SG_ 993 JmpStrtStat 10;
BA_ "GenSigSendOnInit" SG_ 993 JmpStrtStat 1;
BA_ "SignalLongName" SG_ 993 SvcHybridSysIO "Service Hybrid System Indication On";
BA_ "SignalType" SG_ 993 SvcHybridSysIO "BLN";
BA_ "VNSigAllNodes" SG_ 993 SvcHybridSysIO 1;
BA_ "GenSigSendType" SG_ 993 SvcHybridSysIO 10;
BA_ "GenSigSendOnInit" SG_ 993 SvcHybridSysIO 1;
BA_ "SignalLongName" SG_ 993 HybMdDisp "Hybrid Mode Display";
BA_ "SignalType" SG_ 993 HybMdDisp "ENM";
BA_ "VNSigAllNodes" SG_ 993 HybMdDisp 1;
BA_ "GenSigSendType" SG_ 993 HybMdDisp 10;
BA_ "GenSigSendOnInit" SG_ 993 HybMdDisp 1;
BA_ "SignalLongName" SG_ 490 SrvcFlSysPrkInOpnArIO "Service Fuel System Park In Open Area Indication On";
BA_ "SignalType" SG_ 490 SrvcFlSysPrkInOpnArIO "BLN";
BA_ "VNSigAllNodes" SG_ 490 SrvcFlSysPrkInOpnArIO 1;
BA_ "GenSigSendType" SG_ 490 SrvcFlSysPrkInOpnArIO 10;
BA_ "SignalLongName" SG_ 490 FuelSysNEmsRltMalfAct "Fuel System Non Emissions Related Malfunction Active";
BA_ "SignalType" SG_ 490 FuelSysNEmsRltMalfAct "BLN";
BA_ "VNSigAllNodes" SG_ 490 FuelSysNEmsRltMalfAct 1;
BA_ "GenSigSendType" SG_ 490 FuelSysNEmsRltMalfAct 10;
BA_ "SignalLongName" SG_ 490 InActFuelMdFuelLvlIO "Inactive Fuel Mode Fuel Level Indication On";
BA_ "SignalType" SG_ 490 InActFuelMdFuelLvlIO "BLN";
BA_ "VNSigAllNodes" SG_ 490 InActFuelMdFuelLvlIO 1;
BA_ "GenSigSendType" SG_ 490 InActFuelMdFuelLvlIO 10;
BA_ "SignalLongName" SG_ 490 FuelTotCapTnk2 "Fuel Total Capacity Tank 2";
BA_ "SignalType" SG_ 490 FuelTotCapTnk2 "UNM";
BA_ "VNSigAllNodes" SG_ 490 FuelTotCapTnk2 1;
BA_ "SignalLongName" SG_ 490 FlLvlTank2PctV "Fuel Level Tank 2 Percent Validity";
BA_ "SignalType" SG_ 490 FlLvlTank2PctV "ENM";
BA_ "VNSigAllNodes" SG_ 490 FlLvlTank2PctV 1;
BA_ "SignalLongName" SG_ 490 FlLvlTank2Pct "Fuel Level Tank 2 Percent";
BA_ "SignalType" SG_ 490 FlLvlTank2Pct "UNM";
BA_ "VNSigAllNodes" SG_ 490 FlLvlTank2Pct 1;
BA_ "SignalLongName" SG_ 490 AltFuelPHeatAct "Alternative Fuel Pre-heating Active";
BA_ "SignalType" SG_ 490 AltFuelPHeatAct "BLN";
BA_ "VNSigAllNodes" SG_ 490 AltFuelPHeatAct 1;
BA_ "SignalLongName" SG_ 490 AltFuelMdReqDndIO "Alternative Fuel Mode Request Denied Indication On";
BA_ "SignalType" SG_ 490 AltFuelMdReqDndIO "BLN";
BA_ "VNSigAllNodes" SG_ 490 AltFuelMdReqDndIO 1;
BA_ "SignalLongName" SG_ 490 AltFuelLvlLo "Alternative Fuel Level Low";
BA_ "SignalType" SG_ 490 AltFuelLvlLo "BLN";
BA_ "VNSigAllNodes" SG_ 490 AltFuelLvlLo 1;
BA_ "SignalLongName" SG_ 490 AltFuelAccWrnngAct "Alternative Fuel Acceleration Warning Active";
BA_ "SignalType" SG_ 490 AltFuelAccWrnngAct "BLN";
BA_ "VNSigAllNodes" SG_ 490 AltFuelAccWrnngAct 1;
BA_ "SignalLongName" SG_ 490 FuelMdStat "Fuel Mode Status";
BA_ "SignalType" SG_ 490 FuelMdStat "ENM";
BA_ "VNSigAllNodes" SG_ 490 FuelMdStat 1;
BA_ "SignalLongName" SG_ 452 ACCATCS_LmtgStat "Adaptive Cruise Control Axle Torque Command Status : Limiting Status";
BA_ "PacketOrder" SG_ 452 ACCATCS_LmtgStat 2;
BA_ "SignalType" SG_ 452 ACCATCS_LmtgStat "ENM";
BA_ "VNSigAllNodes" SG_ 452 ACCATCS_LmtgStat 1;
BA_ "SignalLongName" SG_ 452 ACCATCS_RqStat "Adaptive Cruise Control Axle Torque Command Status : Request Status";
BA_ "PacketOrder" SG_ 452 ACCATCS_RqStat 1;
BA_ "SignalType" SG_ 452 ACCATCS_RqStat "ENM";
BA_ "VNSigAllNodes" SG_ 452 ACCATCS_RqStat 1;
BA_ "SignalLongName" SG_ 452 RdLdNomAxlTrq "Road Load Nominal Axle Torque";
BA_ "SignalType" SG_ 452 RdLdNomAxlTrq "UNM";
BA_ "VNSigAllNodes" SG_ 452 RdLdNomAxlTrq 1;
BA_ "SignalLongName" SG_ 452 CPSATCS_ReqStatus "Collision Preparation System Axle Torque Command Status : Request Status";
BA_ "PacketOrder" SG_ 452 CPSATCS_ReqStatus 2;
BA_ "SignalType" SG_ 452 CPSATCS_ReqStatus "ENM";
BA_ "VNSigAllNodes" SG_ 452 CPSATCS_ReqStatus 1;
BA_ "SignalLongName" SG_ 452 CPSATCS_LmtngStatus "Collision Preparation System Axle Torque Command Status : Limiting Status";
BA_ "PacketOrder" SG_ 452 CPSATCS_LmtngStatus 1;
BA_ "SignalType" SG_ 452 CPSATCS_LmtngStatus "ENM";
BA_ "VNSigAllNodes" SG_ 452 CPSATCS_LmtngStatus 1;
BA_ "SignalLongName" SG_ 452 RVBATCS_ReqStat "Rear Virtual Bumper Axle Torque Command Status : Request Status";
BA_ "PacketOrder" SG_ 452 RVBATCS_ReqStat 2;
BA_ "SignalType" SG_ 452 RVBATCS_ReqStat "ENM";
BA_ "VNSigAllNodes" SG_ 452 RVBATCS_ReqStat 1;
BA_ "SignalLongName" SG_ 452 RVBATCS_LmtngStat "Rear Virtual Bumper Axle Torque Command Status : Limiting Status";
BA_ "PacketOrder" SG_ 452 RVBATCS_LmtngStat 1;
BA_ "SignalType" SG_ 452 RVBATCS_LmtngStat "ENM";
BA_ "VNSigAllNodes" SG_ 452 RVBATCS_LmtngStat 1;
BA_ "SignalLongName" SG_ 452 FSpRgACCSwADdPVal "Full Speed Range ACC Cruise Switch Action Detected Protection Value";
BA_ "SignalType" SG_ 452 FSpRgACCSwADdPVal "UNM";
BA_ "VNSigAllNodes" SG_ 452 FSpRgACCSwADdPVal 1;
BA_ "SignalLongName" SG_ 452 FSpRgACCSwADdARC "Full Speed Range ACC Cruise Switch Action Detected Alive Rolling Count";
BA_ "SignalType" SG_ 452 FSpRgACCSwADdARC "UNM";
BA_ "VNSigAllNodes" SG_ 452 FSpRgACCSwADdARC 1;
BA_ "SignalLongName" SG_ 452 FSpRgACCSwADd "Full Speed Range ACC Cruise Switch Action Detected";
BA_ "SignalType" SG_ 452 FSpRgACCSwADd "BLN";
BA_ "VNSigAllNodes" SG_ 452 FSpRgACCSwADd 1;
BA_ "SignalLongName" SG_ 452 AutBrkAccActPsStRC "Autonomous Braking Accelerator Actual Position Status Rolling Count";
BA_ "SignalType" SG_ 452 AutBrkAccActPsStRC "UNM";
BA_ "VNSigAllNodes" SG_ 452 AutBrkAccActPsStRC 1;
BA_ "SignalLongName" SG_ 452 AutBrkAccActPsStPVal "Autonomous Braking Accelerator Actual Position Status Protection Value";
BA_ "SignalType" SG_ 452 AutBrkAccActPsStPVal "UNM";
BA_ "VNSigAllNodes" SG_ 452 AutBrkAccActPsStPVal 1;
BA_ "SignalLongName" SG_ 452 ABAAPS_AccPos "Autonomous Braking Accelerator Actual Position Status : Accelerator Position";
BA_ "PacketOrder" SG_ 452 ABAAPS_AccPos 2;
BA_ "SignalType" SG_ 452 ABAAPS_AccPos "UNM";
BA_ "VNSigAllNodes" SG_ 452 ABAAPS_AccPos 1;
BA_ "SignalLongName" SG_ 452 ABAAPS_AccPosV "Autonomous Braking Accelerator Actual Position Status : Accelerator Position Validity";
BA_ "PacketOrder" SG_ 452 ABAAPS_AccPosV 1;
BA_ "SignalType" SG_ 452 ABAAPS_AccPosV "ENM";
BA_ "VNSigAllNodes" SG_ 452 ABAAPS_AccPosV 1;
BA_ "SignalLongName" SG_ 452 AccPdlOvrrdAtvProtVal "Accelerator Pedal Override Active Protection Value";
BA_ "SignalType" SG_ 452 AccPdlOvrrdAtvProtVal "UNM";
BA_ "VNSigAllNodes" SG_ 452 AccPdlOvrrdAtvProtVal 1;
BA_ "SignalLongName" SG_ 452 AccPdlOvrrdAtvARC "Accelerator Pedal Override Active Alive Rolling Count";
BA_ "SignalType" SG_ 452 AccPdlOvrrdAtvARC "UNM";
BA_ "VNSigAllNodes" SG_ 452 AccPdlOvrrdAtvARC 1;
BA_ "SignalLongName" SG_ 452 AccPdlOvrrdAtv "Accelerator Pedal Override Active";
BA_ "SignalType" SG_ 452 AccPdlOvrrdAtv "BLN";
BA_ "VNSigAllNodes" SG_ 452 AccPdlOvrrdAtv 1;
BA_ "SignalLongName" SG_ 1280 TireRRLowTracIO "Tire Right Rear Low Traction Indication On";
BA_ "SignalType" SG_ 1280 TireRRLowTracIO "BLN";
BA_ "VNSigAllNodes" SG_ 1280 TireRRLowTracIO 1;
BA_ "GenSigSendType" SG_ 1280 TireRRLowTracIO 10;
BA_ "SignalLongName" SG_ 1280 TireRFLowTracIO "Tire Right Front Low Traction Indication On";
BA_ "SignalType" SG_ 1280 TireRFLowTracIO "BLN";
BA_ "VNSigAllNodes" SG_ 1280 TireRFLowTracIO 1;
BA_ "GenSigSendType" SG_ 1280 TireRFLowTracIO 10;
BA_ "SignalLongName" SG_ 1280 TireLRLowTracIO "Tire Left Rear Low Traction Indication On";
BA_ "SignalType" SG_ 1280 TireLRLowTracIO "BLN";
BA_ "VNSigAllNodes" SG_ 1280 TireLRLowTracIO 1;
BA_ "GenSigSendType" SG_ 1280 TireLRLowTracIO 10;
BA_ "SignalLongName" SG_ 1280 TireLFLowTracIO "Tire Left Front Low Traction Indication On";
BA_ "SignalType" SG_ 1280 TireLFLowTracIO "BLN";
BA_ "VNSigAllNodes" SG_ 1280 TireLFLowTracIO 1;
BA_ "GenSigSendType" SG_ 1280 TireLFLowTracIO 10;
BA_ "SignalLongName" SG_ 1280 WhlRotStatTmstmpRes "Wheel Rotational Status Timestamp Resolution";
BA_ "SignalType" SG_ 1280 WhlRotStatTmstmpRes "UNM";
BA_ "VNSigAllNodes" SG_ 1280 WhlRotStatTmstmpRes 1;
BA_ "SignalLongName" SG_ 1280 WhlPlsPerRevNonDrvn "Wheel Pulses Per Revolution Non Driven";
BA_ "SignalType" SG_ 1280 WhlPlsPerRevNonDrvn "UNM";
BA_ "VNSigAllNodes" SG_ 1280 WhlPlsPerRevNonDrvn 1;
BA_ "SignalLongName" SG_ 1280 WhlPlsPerRevDrvn "Wheel Pulses Per Revolution Driven";
BA_ "SignalType" SG_ 1280 WhlPlsPerRevDrvn "UNM";
BA_ "VNSigAllNodes" SG_ 1280 WhlPlsPerRevDrvn 1;
BA_ "SignalLongName" SG_ 562 BrkSysAutBrkStat "Brake System Automatic Braking Status";
BA_ "SignalType" SG_ 562 BrkSysAutBrkStat "ENM";
BA_ "VNSigAllNodes" SG_ 562 BrkSysAutBrkStat 1;
BA_ "SignalLongName" SG_ 562 FSRACCBrkngReqDenied "Full Speed Range Adaptive Cruise Control Braking Request Denied";
BA_ "SignalType" SG_ 562 FSRACCBrkngReqDenied "BLN";
BA_ "VNSigAllNodes" SG_ 562 FSRACCBrkngReqDenied 1;
BA_ "SignalLongName" SG_ 562 BrkSysExtHldCpbltyFld "Brake System Extended Hold Capability Failed";
BA_ "SignalType" SG_ 562 BrkSysExtHldCpbltyFld "BLN";
BA_ "VNSigAllNodes" SG_ 562 BrkSysExtHldCpbltyFld 1;
BA_ "SignalLongName" SG_ 562 DrvlneMntsPerfMdRq "Driveline Mounts Performance Mode Request";
BA_ "SignalType" SG_ 562 DrvlneMntsPerfMdRq "ENM";
BA_ "VNSigAllNodes" SG_ 562 DrvlneMntsPerfMdRq 1;
BA_ "SignalLongName" SG_ 562 RideCntrlPerfMdRq "Ride Control Performance Mode Request";
BA_ "SignalType" SG_ 562 RideCntrlPerfMdRq "ENM";
BA_ "VNSigAllNodes" SG_ 562 RideCntrlPerfMdRq 1;
BA_ "SignalLongName" SG_ 562 StgSysPerfMdRq "Steering System Performance Mode Request";
BA_ "SignalType" SG_ 562 StgSysPerfMdRq "ENM";
BA_ "VNSigAllNodes" SG_ 562 StgSysPerfMdRq 1;
BA_ "SignalLongName" SG_ 562 DiffPerfMdRq "Differential Performance Mode Request";
BA_ "SignalType" SG_ 562 DiffPerfMdRq "ENM";
BA_ "VNSigAllNodes" SG_ 562 DiffPerfMdRq 1;
BA_ "SignalLongName" SG_ 562 ExhstPerfMdRq "Exhaust Performance Mode Request";
BA_ "SignalType" SG_ 562 ExhstPerfMdRq "ENM";
BA_ "VNSigAllNodes" SG_ 562 ExhstPerfMdRq 1;
BA_ "SignalLongName" SG_ 562 DrvMdCntrlState "Driving Mode Control State";
BA_ "SignalType" SG_ 562 DrvMdCntrlState "UNM";
BA_ "VNSigAllNodes" SG_ 562 DrvMdCntrlState 1;
BA_ "SignalLongName" SG_ 562 AWDPerfMdRq "AWD Performance Mode Request";
BA_ "SignalType" SG_ 562 AWDPerfMdRq "ENM";
BA_ "VNSigAllNodes" SG_ 562 AWDPerfMdRq 1;
BA_ "SignalLongName" SG_ 562 SndPerfMdCsStAvl "Sound Performance Mode Customization Setting Available";
BA_ "SignalType" SG_ 562 SndPerfMdCsStAvl "BLN";
BA_ "VNSigAllNodes" SG_ 562 SndPerfMdCsStAvl 1;
BA_ "SignalLongName" SG_ 562 SndPerfMdCsCrStVal "Sound Performance Mode Customization Current Setting Value";
BA_ "SignalType" SG_ 562 SndPerfMdCsCrStVal "ENM";
BA_ "VNSigAllNodes" SG_ 562 SndPerfMdCsCrStVal 1;
BA_ "SignalLongName" SG_ 562 DispPerfMdCsStAvl "Display Performance Mode Customization Setting Available";
BA_ "SignalType" SG_ 562 DispPerfMdCsStAvl "BLN";
BA_ "VNSigAllNodes" SG_ 562 DispPerfMdCsStAvl 1;
BA_ "SignalLongName" SG_ 562 DispPerfMdCsCrStVal "Display Performance Mode Customization Current Setting Value";
BA_ "SignalType" SG_ 562 DispPerfMdCsCrStVal "ENM";
BA_ "VNSigAllNodes" SG_ 562 DispPerfMdCsCrStVal 1;
BA_ "SignalLongName" SG_ 562 SndEnhcmtPerfMdRq "Sound Enhancement Performance Mode Request";
BA_ "SignalType" SG_ 562 SndEnhcmtPerfMdRq "ENM";
BA_ "VNSigAllNodes" SG_ 562 SndEnhcmtPerfMdRq 1;
BA_ "SignalLongName" SG_ 562 DsplyPerfMdRq "Display Performance Mode Request";
BA_ "SignalType" SG_ 562 DsplyPerfMdRq "ENM";
BA_ "VNSigAllNodes" SG_ 562 DsplyPerfMdRq 1;
BA_ "GenSigSendType" SG_ 562 DsplyPerfMdRq 10;
BA_ "SignalLongName" SG_ 562 HillDscntCntlSysStat "Hill Descent Control System Status";
BA_ "SignalType" SG_ 562 HillDscntCntlSysStat "ENM";
BA_ "VNSigAllNodes" SG_ 562 HillDscntCntlSysStat 1;
BA_ "SignalLongName" SG_ 562 SusCustStngAvlbl "Suspension Customization Setting Available";
BA_ "SignalType" SG_ 562 SusCustStngAvlbl "BLN";
BA_ "VNSigAllNodes" SG_ 562 SusCustStngAvlbl 1;
BA_ "SignalLongName" SG_ 562 SusCustCurrStngVal "Suspension Customization Current Setting Value";
BA_ "SignalType" SG_ 562 SusCustCurrStngVal "ENM";
BA_ "VNSigAllNodes" SG_ 562 SusCustCurrStngVal 1;
BA_ "SignalLongName" SG_ 562 StrCustStngAvlbl "Steering Customization Setting Available";
BA_ "SignalType" SG_ 562 StrCustStngAvlbl "BLN";
BA_ "VNSigAllNodes" SG_ 562 StrCustStngAvlbl 1;
BA_ "SignalLongName" SG_ 562 StrCustCurrStngVal "Steering Customization Current Setting Value";
BA_ "SignalType" SG_ 562 StrCustCurrStngVal "ENM";
BA_ "VNSigAllNodes" SG_ 562 StrCustCurrStngVal 1;
BA_ "SignalLongName" SG_ 562 DrvlnCustStngAvlbl "Driveline Customization Setting Available";
BA_ "SignalType" SG_ 562 DrvlnCustStngAvlbl "BLN";
BA_ "VNSigAllNodes" SG_ 562 DrvlnCustStngAvlbl 1;
BA_ "SignalLongName" SG_ 562 DrvlnCustCurrStngVal "Driveline Customization Current Setting Value";
BA_ "SignalType" SG_ 562 DrvlnCustCurrStngVal "ENM";
BA_ "VNSigAllNodes" SG_ 562 DrvlnCustCurrStngVal 1;
BA_ "SignalLongName" SG_ 386 AdptCruzCtrlStg "Adaptive Cruise Control Setting";
BA_ "SignalType" SG_ 386 AdptCruzCtrlStg "ENM";
BA_ "VNSigAllNodes" SG_ 386 AdptCruzCtrlStg 1;
BA_ "SignalLongName" SG_ 386 AHAct "Auto Hold Active";
BA_ "SignalType" SG_ 386 AHAct "BLN";
BA_ "VNSigAllNodes" SG_ 386 AHAct 1;
BA_ "SignalLongName" SG_ 386 AHEnbld "Auto Hold Enabled";
BA_ "SignalType" SG_ 386 AHEnbld "BLN";
BA_ "VNSigAllNodes" SG_ 386 AHEnbld 1;
BA_ "SignalLongName" SG_ 386 ShfToPrkBfExtngIO "Shift To Park Before Exiting Indication On";
BA_ "SignalType" SG_ 386 ShfToPrkBfExtngIO "BLN";
BA_ "VNSigAllNodes" SG_ 386 ShfToPrkBfExtngIO 1;
BA_ "SignalLongName" SG_ 386 AHServcIO "Auto Hold Service Indication On";
BA_ "SignalType" SG_ 386 AHServcIO "BLN";
BA_ "VNSigAllNodes" SG_ 386 AHServcIO 1;
BA_ "SignalLongName" SG_ 386 AHAppBrkPedlIO "Auto Hold Apply Brake Pedal Indication On";
BA_ "SignalType" SG_ 386 AHAppBrkPedlIO "BLN";
BA_ "VNSigAllNodes" SG_ 386 AHAppBrkPedlIO 1;
BA_ "SignalLongName" SG_ 386 AHDisbldStbltIO "Auto Hold Disabled Seatbelt Indication On";
BA_ "SignalType" SG_ 386 AHDisbldStbltIO "BLN";
BA_ "VNSigAllNodes" SG_ 386 AHDisbldStbltIO 1;
BA_ "SignalLongName" SG_ 386 AHDisbldDrOpnIO "Auto Hold Disabled Door Open Indication On";
BA_ "SignalType" SG_ 386 AHDisbldDrOpnIO "BLN";
BA_ "VNSigAllNodes" SG_ 386 AHDisbldDrOpnIO 1;
BA_ "SignalLongName" SG_ 386 PMVSS_Disps "Performance Mode Visualization Screen Status : Displays";
BA_ "PacketOrder" SG_ 386 PMVSS_Disps 11;
BA_ "SignalType" SG_ 386 PMVSS_Disps "ENM";
BA_ "VNSigAllNodes" SG_ 386 PMVSS_Disps 1;
BA_ "GenSigSendType" SG_ 386 PMVSS_Disps 10;
BA_ "GenSigSendOnInit" SG_ 386 PMVSS_Disps 2;
BA_ "SignalLongName" SG_ 386 PMVSS_Exhst "Performance Mode Visualization Screen Status : Exhaust";
BA_ "PacketOrder" SG_ 386 PMVSS_Exhst 10;
BA_ "SignalType" SG_ 386 PMVSS_Exhst "ENM";
BA_ "VNSigAllNodes" SG_ 386 PMVSS_Exhst 1;
BA_ "GenSigSendType" SG_ 386 PMVSS_Exhst 10;
BA_ "GenSigSendOnInit" SG_ 386 PMVSS_Exhst 2;
BA_ "SignalLongName" SG_ 386 PMVSS_PsngrSeat "Performance Mode Visualization Screen Status : Passenger Seat";
BA_ "PacketOrder" SG_ 386 PMVSS_PsngrSeat 9;
BA_ "SignalType" SG_ 386 PMVSS_PsngrSeat "ENM";
BA_ "VNSigAllNodes" SG_ 386 PMVSS_PsngrSeat 1;
BA_ "GenSigSendType" SG_ 386 PMVSS_PsngrSeat 10;
BA_ "GenSigSendOnInit" SG_ 386 PMVSS_PsngrSeat 2;
BA_ "SignalLongName" SG_ 386 PMVSS_DrvrSeat "Performance Mode Visualization Screen Status : Driver Seat";
BA_ "PacketOrder" SG_ 386 PMVSS_DrvrSeat 8;
BA_ "SignalType" SG_ 386 PMVSS_DrvrSeat "ENM";
BA_ "VNSigAllNodes" SG_ 386 PMVSS_DrvrSeat 1;
BA_ "GenSigSendType" SG_ 386 PMVSS_DrvrSeat 10;
BA_ "GenSigSendOnInit" SG_ 386 PMVSS_DrvrSeat 2;
BA_ "SignalLongName" SG_ 386 PMVSS_AdptCrsCnt "Performance Mode Visualization Screen Status : Adaptive Cruise Control";
BA_ "PacketOrder" SG_ 386 PMVSS_AdptCrsCnt 7;
BA_ "SignalType" SG_ 386 PMVSS_AdptCrsCnt "ENM";
BA_ "VNSigAllNodes" SG_ 386 PMVSS_AdptCrsCnt 1;
BA_ "GenSigSendType" SG_ 386 PMVSS_AdptCrsCnt 10;
BA_ "GenSigSendOnInit" SG_ 386 PMVSS_AdptCrsCnt 2;
BA_ "SignalLongName" SG_ 386 PMVSS_Drvln "Performance Mode Visualization Screen Status : Driveline";
BA_ "PacketOrder" SG_ 386 PMVSS_Drvln 6;
BA_ "SignalType" SG_ 386 PMVSS_Drvln "ENM";
BA_ "VNSigAllNodes" SG_ 386 PMVSS_Drvln 1;
BA_ "GenSigSendType" SG_ 386 PMVSS_Drvln 10;
BA_ "GenSigSendOnInit" SG_ 386 PMVSS_Drvln 2;
BA_ "SignalLongName" SG_ 386 PMVSS_Susp "Performance Mode Visualization Screen Status : Suspension";
BA_ "PacketOrder" SG_ 386 PMVSS_Susp 5;
BA_ "SignalType" SG_ 386 PMVSS_Susp "ENM";
BA_ "VNSigAllNodes" SG_ 386 PMVSS_Susp 1;
BA_ "GenSigSendType" SG_ 386 PMVSS_Susp 10;
BA_ "GenSigSendOnInit" SG_ 386 PMVSS_Susp 2;
BA_ "SignalLongName" SG_ 386 PMVSS_Strng "Performance Mode Visualization Screen Status : Steering";
BA_ "PacketOrder" SG_ 386 PMVSS_Strng 4;
BA_ "SignalType" SG_ 386 PMVSS_Strng "ENM";
BA_ "VNSigAllNodes" SG_ 386 PMVSS_Strng 1;
BA_ "GenSigSendType" SG_ 386 PMVSS_Strng 10;
BA_ "GenSigSendOnInit" SG_ 386 PMVSS_Strng 2;
BA_ "SignalLongName" SG_ 386 PMVSS_Trans "Performance Mode Visualization Screen Status : Transmission";
BA_ "PacketOrder" SG_ 386 PMVSS_Trans 3;
BA_ "SignalType" SG_ 386 PMVSS_Trans "ENM";
BA_ "VNSigAllNodes" SG_ 386 PMVSS_Trans 1;
BA_ "GenSigSendType" SG_ 386 PMVSS_Trans 10;
BA_ "GenSigSendOnInit" SG_ 386 PMVSS_Trans 2;
BA_ "SignalLongName" SG_ 386 PMVSS_Eng "Performance Mode Visualization Screen Status : Engine";
BA_ "PacketOrder" SG_ 386 PMVSS_Eng 2;
BA_ "SignalType" SG_ 386 PMVSS_Eng "ENM";
BA_ "VNSigAllNodes" SG_ 386 PMVSS_Eng 1;
BA_ "GenSigSendType" SG_ 386 PMVSS_Eng 10;
BA_ "GenSigSendOnInit" SG_ 386 PMVSS_Eng 2;
BA_ "SignalLongName" SG_ 386 PMVSS_Snd "Performance Mode Visualization Screen Status : Sound";
BA_ "PacketOrder" SG_ 386 PMVSS_Snd 1;
BA_ "SignalType" SG_ 386 PMVSS_Snd "ENM";
BA_ "VNSigAllNodes" SG_ 386 PMVSS_Snd 1;
BA_ "GenSigSendType" SG_ 386 PMVSS_Snd 10;
BA_ "GenSigSendOnInit" SG_ 386 PMVSS_Snd 2;
BA_ "SignalLongName" SG_ 386 AWDRecmndIO "All Wheel Drive Recommended Indication On";
BA_ "SignalType" SG_ 386 AWDRecmndIO "BLN";
BA_ "VNSigAllNodes" SG_ 386 AWDRecmndIO 1;
BA_ "GenSigSendType" SG_ 386 AWDRecmndIO 10;
BA_ "SignalLongName" SG_ 386 EnvIdRsp4 "Environment Identification Response 4";
BA_ "SignalType" SG_ 386 EnvIdRsp4 "UNM";
BA_ "VNSigAllNodes" SG_ 386 EnvIdRsp4 1;
BA_ "SignalLongName" SG_ 386 EnvIdRspSt4 "Environment Identification Response Status 4";
BA_ "SignalType" SG_ 386 EnvIdRspSt4 "ENM";
BA_ "VNSigAllNodes" SG_ 386 EnvIdRspSt4 1;
BA_ "SignalLongName" SG_ 532 RedntVSEActARC "Redundant Vehicle Stability Enhancement System Active Alive Rolling Count";
BA_ "SignalType" SG_ 532 RedntVSEActARC "UNM";
BA_ "VNSigAllNodes" SG_ 532 RedntVSEActARC 1;
BA_ "SignalLongName" SG_ 532 RedntVSEAct "Redundant Vehicle Stability Enhancement System Active";
BA_ "SignalType" SG_ 532 RedntVSEAct "BLN";
BA_ "VNSigAllNodes" SG_ 532 RedntVSEAct 1;
BA_ "SignalLongName" SG_ 532 AutoBrkngActARC "Automatic Braking Active Alive Rolling Count";
BA_ "SignalType" SG_ 532 AutoBrkngActARC "UNM";
BA_ "VNSigAllNodes" SG_ 532 AutoBrkngActARC 1;
BA_ "SignalLongName" SG_ 532 VehHldDrvrDsblActvFlg "Vehicle Hold Driver Disable Active Flag";
BA_ "SignalType" SG_ 532 VehHldDrvrDsblActvFlg "BLN";
BA_ "VNSigAllNodes" SG_ 532 VehHldDrvrDsblActvFlg 1;
BA_ "SignalLongName" SG_ 532 ABSAutnmsBrkReqPVal "Antilock Brake System Autonomous Braking Request Protection Value";
BA_ "SignalType" SG_ 532 ABSAutnmsBrkReqPVal "UNM";
BA_ "VNSigAllNodes" SG_ 532 ABSAutnmsBrkReqPVal 1;
BA_ "SignalLongName" SG_ 532 AutoBrkngAvlbl "Automatic Braking Available";
BA_ "SignalType" SG_ 532 AutoBrkngAvlbl "BLN";
BA_ "VNSigAllNodes" SG_ 532 AutoBrkngAvlbl 1;
BA_ "SignalLongName" SG_ 532 ABSAutnmsBrkReqARC "Antilock Brake System Autonomous Braking Request Alive Rolling Count";
BA_ "SignalType" SG_ 532 ABSAutnmsBrkReqARC "UNM";
BA_ "VNSigAllNodes" SG_ 532 ABSAutnmsBrkReqARC 1;
BA_ "SignalLongName" SG_ 532 ABSAutnmsBrkReq "Antilock Brake System Autonomous Braking Request";
BA_ "SignalType" SG_ 532 ABSAutnmsBrkReq "BLN";
BA_ "VNSigAllNodes" SG_ 532 ABSAutnmsBrkReq 1;
BA_ "SignalLongName" SG_ 532 ABSActvProtPVal "Antilock Brake System Active Protected Protection Value";
BA_ "SignalType" SG_ 532 ABSActvProtPVal "UNM";
BA_ "VNSigAllNodes" SG_ 532 ABSActvProtPVal 1;
BA_ "SignalLongName" SG_ 532 ABSActvProtARC "Antilock Brake System Active Protected Alive Rolling Count";
BA_ "SignalType" SG_ 532 ABSActvProtARC "UNM";
BA_ "VNSigAllNodes" SG_ 532 ABSActvProtARC 1;
BA_ "SignalLongName" SG_ 532 ABSActvProt "Antilock Brake System Active Protected";
BA_ "SignalType" SG_ 532 ABSActvProt "BLN";
BA_ "VNSigAllNodes" SG_ 532 ABSActvProt 1;
BA_ "SignalLongName" SG_ 532 BrkPdDrvAPrsStaPVal "Brake Pedal Driver Applied Pressure Status Protection Value";
BA_ "SignalType" SG_ 532 BrkPdDrvAPrsStaPVal "UNM";
BA_ "VNSigAllNodes" SG_ 532 BrkPdDrvAPrsStaPVal 1;
BA_ "SignalLongName" SG_ 532 BrkPdDrvAppPrsAlRC "Brake Pedal Driver Applied Pressure Alive Rolling Count";
BA_ "SignalType" SG_ 532 BrkPdDrvAppPrsAlRC "UNM";
BA_ "VNSigAllNodes" SG_ 532 BrkPdDrvAppPrsAlRC 1;
BA_ "SignalLongName" SG_ 532 AutoBrkngAct "Automatic Braking Active";
BA_ "SignalType" SG_ 532 AutoBrkngAct "BLN";
BA_ "VNSigAllNodes" SG_ 532 AutoBrkngAct 1;
BA_ "SignalLongName" SG_ 532 HilRlbkCtrlActIO "Hill Rollback Control Active Indiction On";
BA_ "SignalType" SG_ 532 HilRlbkCtrlActIO "BLN";
BA_ "VNSigAllNodes" SG_ 532 HilRlbkCtrlActIO 1;
BA_ "GenSigSendType" SG_ 532 HilRlbkCtrlActIO 10;
BA_ "SignalLongName" SG_ 532 HlStrAssActIO "Hill Start Assist Active Indication On";
BA_ "SignalType" SG_ 532 HlStrAssActIO "BLN";
BA_ "VNSigAllNodes" SG_ 532 HlStrAssActIO 1;
BA_ "SignalLongName" SG_ 532 BrkSysAutBrkFld "Brake System Automatic Braking Failed";
BA_ "SignalType" SG_ 532 BrkSysAutBrkFld "BLN";
BA_ "VNSigAllNodes" SG_ 532 BrkSysAutBrkFld 1;
BA_ "SignalLongName" SG_ 532 IntBrkAssPreFilReq "Inteligent Brake Assist Pre-Fil Request";
BA_ "SignalType" SG_ 532 IntBrkAssPreFilReq "BLN";
BA_ "VNSigAllNodes" SG_ 532 IntBrkAssPreFilReq 1;
BA_ "SignalLongName" SG_ 532 BrkSysMalFuncIndOn "Brake System Malfunction Indication On";
BA_ "SignalType" SG_ 532 BrkSysMalFuncIndOn "BLN";
BA_ "VNSigAllNodes" SG_ 532 BrkSysMalFuncIndOn 1;
BA_ "SignalLongName" SG_ 532 BPDAPS_BkPDrvApPV "Brake Pedal Driver Applied Pressure Status : Brake Pedal Driver Applied Pressure Validity";
BA_ "PacketOrder" SG_ 532 BPDAPS_BkPDrvApPV 2;
BA_ "SignalType" SG_ 532 BPDAPS_BkPDrvApPV "ENM";
BA_ "VNSigAllNodes" SG_ 532 BPDAPS_BkPDrvApPV 1;
BA_ "SignalLongName" SG_ 532 BPDAPS_BkPDrvApP "Brake Pedal Driver Applied Pressure Status : Brake Pedal Driver Applied Pressure";
BA_ "PacketOrder" SG_ 532 BPDAPS_BkPDrvApP 1;
BA_ "SignalType" SG_ 532 BPDAPS_BkPDrvApP "UNM";
BA_ "VNSigAllNodes" SG_ 532 BPDAPS_BkPDrvApP 1;
BA_ "SignalLongName" SG_ 532 BrkFldLvlLwV "Brake Fluid Level Low Validity";
BA_ "SignalType" SG_ 532 BrkFldLvlLwV "ENM";
BA_ "VNSigAllNodes" SG_ 532 BrkFldLvlLwV 1;
BA_ "SignalLongName" SG_ 532 BrkFldLvlLw "Brake Fluid Level Low";
BA_ "SignalType" SG_ 532 BrkFldLvlLw "BLN";
BA_ "VNSigAllNodes" SG_ 532 BrkFldLvlLw 1;
BA_ "SignalLongName" SG_ 328 StrAsstRdcdLvl3IO "Steering Assist Reduced Level 3 Indication On";
BA_ "SignalType" SG_ 328 StrAsstRdcdLvl3IO "BLN";
BA_ "VNSigAllNodes" SG_ 328 StrAsstRdcdLvl3IO 1;
BA_ "GenSigSendType" SG_ 328 StrAsstRdcdLvl3IO 10;
BA_ "SignalLongName" SG_ 328 StrAsstRdcdLvl2IO "Steering Assist Reduced Level 2 Indication On";
BA_ "SignalType" SG_ 328 StrAsstRdcdLvl2IO "BLN";
BA_ "VNSigAllNodes" SG_ 328 StrAsstRdcdLvl2IO 1;
BA_ "GenSigSendType" SG_ 328 StrAsstRdcdLvl2IO 10;
BA_ "SignalLongName" SG_ 328 StrngAsstRdcdIO "Steering Assist Reduced Indication On";
BA_ "SignalType" SG_ 328 StrngAsstRdcdIO "BLN";
BA_ "VNSigAllNodes" SG_ 328 StrngAsstRdcdIO 1;
BA_ "GenSigSendType" SG_ 328 StrngAsstRdcdIO 10;
BA_ "SignalLongName" SG_ 328 PwrStrIO "Power Steering Indication On";
BA_ "SignalType" SG_ 328 PwrStrIO "BLN";
BA_ "VNSigAllNodes" SG_ 328 PwrStrIO 1;
BA_ "GenSigSendType" SG_ 328 PwrStrIO 10;
BA_ "SignalLongName" SG_ 560 ElecPrkBrkCmdProt "Electric Park Brake Command Protection";
BA_ "SignalType" SG_ 560 ElecPrkBrkCmdProt "UNM";
BA_ "VNSigAllNodes" SG_ 560 ElecPrkBrkCmdProt 1;
BA_ "SignalLongName" SG_ 560 ElecPrkBrkSwStatV "Electric Park Brake Switch Status Validity";
BA_ "SignalType" SG_ 560 ElecPrkBrkSwStatV "ENM";
BA_ "VNSigAllNodes" SG_ 560 ElecPrkBrkSwStatV 1;
BA_ "SignalLongName" SG_ 560 ElecPrkBrkCmdARC "Electric Park Brake Command Alive Rolling Count";
BA_ "SignalType" SG_ 560 ElecPrkBrkCmdARC "UNM";
BA_ "VNSigAllNodes" SG_ 560 ElecPrkBrkCmdARC 1;
BA_ "SignalLongName" SG_ 560 ElecPrkBrkSwStat "Electric Park Brake Switch Status";
BA_ "SignalType" SG_ 560 ElecPrkBrkSwStat "ENM";
BA_ "VNSigAllNodes" SG_ 560 ElecPrkBrkSwStat 1;
BA_ "SignalLongName" SG_ 560 EPBC_EPBAccRq "Electric Park Brake Command : Electric Park Brake Acceleration Requested";
BA_ "PacketOrder" SG_ 560 EPBC_EPBAccRq 2;
BA_ "SignalType" SG_ 560 EPBC_EPBAccRq "SNM";
BA_ "VNSigAllNodes" SG_ 560 EPBC_EPBAccRq 1;
BA_ "SignalLongName" SG_ 560 EPBC_EPBrkAutBrkRq "Electric Park Brake Command : Electric Park Brake Automatic Braking Requested";
BA_ "PacketOrder" SG_ 560 EPBC_EPBrkAutBrkRq 1;
BA_ "SignalType" SG_ 560 EPBC_EPBrkAutBrkRq "BLN";
BA_ "VNSigAllNodes" SG_ 560 EPBC_EPBrkAutBrkRq 1;
BA_ "SignalLongName" SG_ 560 AllNodesVNA "All Nodes Virtual Network Activation";
BA_ "SignalType" SG_ 560 AllNodesVNA "ENM";
BA_ "VNSigSLHS_VNReq" SG_ 560 AllNodesVNA 1;
BA_ "VNSigAllNodes" SG_ 560 AllNodesVNA 1;
BA_ "SignalLongName" SG_ 560 StpOnBrkToRelPBIndOn "Step On Brake To Release Park Brake Indication On";
BA_ "SignalType" SG_ 560 StpOnBrkToRelPBIndOn "BLN";
BA_ "VNSigAllNodes" SG_ 560 StpOnBrkToRelPBIndOn 1;
BA_ "SignalLongName" SG_ 560 EPBSysDspMsgReq "Electric Park Brake System Display Message Request";
BA_ "SignalType" SG_ 560 EPBSysDspMsgReq "ENM";
BA_ "VNSigAllNodes" SG_ 560 EPBSysDspMsgReq 1;
BA_ "SignalLongName" SG_ 560 EPBSysAudWarnReq "Electric Park Brake System Audible Warning Request";
BA_ "SignalType" SG_ 560 EPBSysAudWarnReq "ENM";
BA_ "VNSigAllNodes" SG_ 560 EPBSysAudWarnReq 1;
BA_ "SignalLongName" SG_ 560 ElecPrkBrkStat "Electric Park Brake Status";
BA_ "SignalType" SG_ 560 ElecPrkBrkStat "ENM";
BA_ "VNSigAllNodes" SG_ 560 ElecPrkBrkStat 1;
BA_ "SignalLongName" SG_ 560 EPBCrsCanRq "Electric Park Brake Cruise Control Cancel Requested";
BA_ "SignalType" SG_ 560 EPBCrsCanRq "BLN";
BA_ "VNSigAllNodes" SG_ 560 EPBCrsCanRq 1;
BA_ "SignalLongName" SG_ 560 EPBSysStatIndReq "Electric Park Brake System Status Indication Request";
BA_ "SignalType" SG_ 560 EPBSysStatIndReq "ENM";
BA_ "VNSigAllNodes" SG_ 560 EPBSysStatIndReq 1;
BA_ "SignalLongName" SG_ 560 EPBSysWrnIndReq "Electric Park Brake System Warning Indication Request";
BA_ "SignalType" SG_ 560 EPBSysWrnIndReq "ENM";
BA_ "VNSigAllNodes" SG_ 560 EPBSysWrnIndReq 1;
BA_ "SignalLongName" SG_ 560 EPBSysBrkLtsReq "Electric Park Brake System Brake Lights Requested";
BA_ "SignalType" SG_ 560 EPBSysBrkLtsReq "BLN";
BA_ "VNSigAllNodes" SG_ 560 EPBSysBrkLtsReq 1;
BA_ "SignalLongName" SG_ 451 HillDscntCtrlSwStatPVal "Hill Descent Control Switch Status Protection Value";
BA_ "SignalType" SG_ 451 HillDscntCtrlSwStatPVal "UNM";
BA_ "VNSigAllNodes" SG_ 451 HillDscntCtrlSwStatPVal 1;
BA_ "SignalLongName" SG_ 451 HillDscntCtrlSwStatARC "Hill Descent Control Switch Status Alive Rolling Count";
BA_ "SignalType" SG_ 451 HillDscntCtrlSwStatARC "UNM";
BA_ "VNSigAllNodes" SG_ 451 HillDscntCtrlSwStatARC 1;
BA_ "SignalLongName" SG_ 451 HillDscntCtrlSwStat "Hill Descent Control Switch Status";
BA_ "SignalType" SG_ 451 HillDscntCtrlSwStat "ENM";
BA_ "VNSigAllNodes" SG_ 451 HillDscntCtrlSwStat 1;
BA_ "SignalLongName" SG_ 451 AccPosV "Accelerator Effective Position Validity";
BA_ "SignalType" SG_ 451 AccPosV "ENM";
BA_ "VNSigAllNodes" SG_ 451 AccPosV 1;
BA_ "SignalLongName" SG_ 451 EngTrqRdFlrSt "Engine Torque Reduction Failure Status";
BA_ "SignalType" SG_ 451 EngTrqRdFlrSt "ENM";
BA_ "VNSigAllNodes" SG_ 451 EngTrqRdFlrSt 1;
BA_ "SignalLongName" SG_ 451 AccPos "Accelerator Effective Position";
BA_ "SignalType" SG_ 451 AccPos "UNM";
BA_ "VNSigAllNodes" SG_ 451 AccPos 1;
BA_ "SignalLongName" SG_ 451 GlwPlgCrnkDelAct "Glow Plugs Crank Delay Active";
BA_ "SignalType" SG_ 451 GlwPlgCrnkDelAct "BLN";
BA_ "VNSigAllNodes" SG_ 451 GlwPlgCrnkDelAct 1;
BA_ "SignalLongName" SG_ 451 AuxHtrAlwd "Auxiliary Heater Allowed";
BA_ "SignalType" SG_ 451 AuxHtrAlwd "BLN";
BA_ "VNSigAllNodes" SG_ 451 AuxHtrAlwd 1;
BA_ "GenSigSendType" SG_ 451 AuxHtrAlwd 10;
BA_ "SignalLongName" SG_ 451 AppCltchAutSrtIO "Apply Clutch For Automatic Start Indication On";
BA_ "SignalType" SG_ 451 AppCltchAutSrtIO "BLN";
BA_ "VNSigAllNodes" SG_ 451 AppCltchAutSrtIO 1;
BA_ "SignalLongName" SG_ 451 FuelFltRmnLf "Fuel Filter Remaining Life";
BA_ "SignalType" SG_ 451 FuelFltRmnLf "UNM";
BA_ "VNSigAllNodes" SG_ 451 FuelFltRmnLf 1;
BA_ "SignalLongName" SG_ 451 EngTrqDrRqdExtRngV "Engine Torque Driver Requested Extended Range Validity";
BA_ "SignalType" SG_ 451 EngTrqDrRqdExtRngV "ENM";
BA_ "VNSigAllNodes" SG_ 451 EngTrqDrRqdExtRngV 1;
BA_ "GenSigStartValue" SG_ 451 EngTrqDrRqdExtRng 1696;
BA_ "SignalLongName" SG_ 451 EngTrqDrRqdExtRng "Engine Torque Driver Requested Extended Range";
BA_ "SignalType" SG_ 451 EngTrqDrRqdExtRng "UNM";
BA_ "VNSigAllNodes" SG_ 451 EngTrqDrRqdExtRng 1;
BA_ "SignalLongName" SG_ 451 EngTrqActExtRngV "Engine Torque Actual Extended Range Validity";
BA_ "SignalType" SG_ 451 EngTrqActExtRngV "ENM";
BA_ "VNSigAllNodes" SG_ 451 EngTrqActExtRngV 1;
BA_ "GenSigStartValue" SG_ 451 EngTrqActExtRng 1696;
BA_ "SignalLongName" SG_ 451 EngTrqActExtRng "Engine Torque Actual Extended Range";
BA_ "SignalType" SG_ 451 EngTrqActExtRng "UNM";
BA_ "VNSigAllNodes" SG_ 451 EngTrqActExtRng 1;
BA_ "SignalLongName" SG_ 1282 TireTrdTmpStatARC "Tire Tread Temperature Status Alive Rolling Count";
BA_ "SignalType" SG_ 1282 TireTrdTmpStatARC "UNM";
BA_ "VNSigAllNodes" SG_ 1282 TireTrdTmpStatARC 1;
BA_ "SignalLongName" SG_ 1282 TireTrdTmpStat "Tire Tread Temperature Status";
BA_ "SignalType" SG_ 1282 TireTrdTmpStat "ENM";
BA_ "VNSigAllNodes" SG_ 1282 TireTrdTmpStat 1;
BA_ "GenSigSendType" SG_ 1282 TireTrdTmpStat 10;
BA_ "SignalLongName" SG_ 1282 AllNodesVNA_502 "All Nodes Virtual Network Activation";
BA_ "SignalType" SG_ 1282 AllNodesVNA_502 "ENM";
BA_ "VNSigSLHS_VNReq" SG_ 1282 AllNodesVNA_502 1;
BA_ "VNSigAllNodes" SG_ 1282 AllNodesVNA_502 1;
BA_ "SignalLongName" SG_ 2033 PCUInfo "Pyrotechnical Control Unit Information";
BA_ "SignalType" SG_ 2033 PCUInfo "UNM";
BA_ "VNSigAllNodes" SG_ 2033 PCUInfo 1;
BA_ "GenSigDeltaValue" SG_ 2033 PCUInfo 1;
BA_ "GenSigSendType" SG_ 2033 PCUInfo 12;
BA_ "SignalLongName" SG_ 880 ACCSysSltdMdDispIO "Adaptive Cruise Control System Selected Mode Display Indication On";
BA_ "SignalType" SG_ 880 ACCSysSltdMdDispIO "BLN";
BA_ "VNSigAllNodes" SG_ 880 ACCSysSltdMdDispIO 1;
BA_ "GenSigSendType" SG_ 880 ACCSysSltdMdDispIO 10;
BA_ "GenSigSendOnInit" SG_ 880 ACCSysSltdMdDispIO 2;
BA_ "SignalLongName" SG_ 880 ACCSysSltdMd "Adaptive Cruise Control System Selected Mode";
BA_ "SignalType" SG_ 880 ACCSysSltdMd "ENM";
BA_ "VNSigAllNodes" SG_ 880 ACCSysSltdMd 1;
BA_ "GenSigSendType" SG_ 880 ACCSysSltdMd 10;
BA_ "GenSigSendOnInit" SG_ 880 ACCSysSltdMd 2;
BA_ "SignalLongName" SG_ 880 FOAI_VehAhdIndRq "Forward Object Alert Indications : Vehicle Ahead Indication Request";
BA_ "PacketOrder" SG_ 880 FOAI_VehAhdIndRq 2;
BA_ "SignalType" SG_ 880 FOAI_VehAhdIndRq "ENM";
BA_ "VNSigAllNodes" SG_ 880 FOAI_VehAhdIndRq 1;
BA_ "SignalLongName" SG_ 880 FOAI_AlrtWrnIndRq "Forward Object Alert Indications : Alert Warning Indication Request";
BA_ "PacketOrder" SG_ 880 FOAI_AlrtWrnIndRq 3;
BA_ "SignalType" SG_ 880 FOAI_AlrtWrnIndRq "ENM";
BA_ "VNSigAllNodes" SG_ 880 FOAI_AlrtWrnIndRq 1;
BA_ "SignalLongName" SG_ 880 FOAI_AlrtChmIhbRq "Forward Object Alert Indications : Alert Warning Chime Inhibit Request";
BA_ "PacketOrder" SG_ 880 FOAI_AlrtChmIhbRq 1;
BA_ "SignalType" SG_ 880 FOAI_AlrtChmIhbRq "ENM";
BA_ "VNSigAllNodes" SG_ 880 FOAI_AlrtChmIhbRq 1;
BA_ "SignalLongName" SG_ 880 FwdClnAlrtPr "Forward Collision Alert Present";
BA_ "SignalType" SG_ 880 FwdClnAlrtPr "BLN";
BA_ "VNSigAllNodes" SG_ 880 FwdClnAlrtPr 1;
BA_ "SignalLongName" SG_ 880 ACCUnavlbleDTWthrIO "Adaptive Cruise Unavailable Due To Weather Indication On";
BA_ "SignalType" SG_ 880 ACCUnavlbleDTWthrIO "BLN";
BA_ "VNSigAllNodes" SG_ 880 ACCUnavlbleDTWthrIO 1;
BA_ "SignalLongName" SG_ 880 ACCAct370 "Adaptive Cruise Control Active";
BA_ "SignalType" SG_ 880 ACCAct370 "BLN";
BA_ "VNSigAllNodes" SG_ 880 ACCAct370 1;
BA_ "SignalLongName" SG_ 880 DrvThrtlOvrdIO "Driver Throttle Override Indication On";
BA_ "SignalType" SG_ 880 DrvThrtlOvrdIO "BLN";
BA_ "VNSigAllNodes" SG_ 880 DrvThrtlOvrdIO 1;
BA_ "SignalLongName" SG_ 880 ServAdpCrsCtrlIndOn "Service Adaptive Cruise Control Indication On";
BA_ "SignalType" SG_ 880 ServAdpCrsCtrlIndOn "BLN";
BA_ "VNSigAllNodes" SG_ 880 ServAdpCrsCtrlIndOn 1;
BA_ "SignalLongName" SG_ 880 ACCDrvrSeltdSpd "Adaptive Cruise Control Driver Selected Speed";
BA_ "SignalType" SG_ 880 ACCDrvrSeltdSpd "UNM";
BA_ "VNSigAllNodes" SG_ 880 ACCDrvrSeltdSpd 1;
BA_ "SignalLongName" SG_ 880 ACCHdwayStngIO "Adaptive Cruise Control Headway Setting Indication On";
BA_ "SignalType" SG_ 880 ACCHdwayStngIO "BLN";
BA_ "VNSigAllNodes" SG_ 880 ACCHdwayStngIO 1;
BA_ "SignalLongName" SG_ 880 ACCHdwyStg "Adaptive Cruise Control Headway Setting";
BA_ "SignalType" SG_ 880 ACCHdwyStg "ENM";
BA_ "VNSigAllNodes" SG_ 880 ACCHdwyStg 1;
BA_ "SignalLongName" SG_ 880 ACCSnsClnRqdIO "Adaptive Cruise Control Sensor Cleaning Required Indication On";
BA_ "SignalType" SG_ 880 ACCSnsClnRqdIO "BLN";
BA_ "VNSigAllNodes" SG_ 880 ACCSnsClnRqdIO 1;
BA_ "SignalLongName" SG_ 880 ACCTmpUnavlbleIO "Adaptive Cruise Control Temporarily Unavailable Indication On";
BA_ "SignalType" SG_ 880 ACCTmpUnavlbleIO "BLN";
BA_ "VNSigAllNodes" SG_ 880 ACCTmpUnavlbleIO 1;
BA_ "SignalLongName" SG_ 880 ACCDrvrSeltdSpdIO "Adaptive Cruise Control Driver Selected Speed Indication On";
BA_ "SignalType" SG_ 880 ACCDrvrSeltdSpdIO "BLN";
BA_ "VNSigAllNodes" SG_ 880 ACCDrvrSeltdSpdIO 1;
BA_ "SignalLongName" SG_ 577 DgnInf "Diagnostic Information";
BA_ "SignalType" SG_ 577 DgnInf "UNM";
BA_ "VNSigSLHSSharedDiagnostic" SG_ 577 DgnInf 1;
BA_ "VNSigAllNodes" SG_ 577 DgnInf 1;
BA_ "GenSigDeltaValue" SG_ 577 DgnInf 1;
BA_ "GenSigSendType" SG_ 577 DgnInf 12;
BA_ "SignalLongName" SG_ 485 StrAngSnsChksm "Steering Angle Sensor Checksum";
BA_ "SignalType" SG_ 485 StrAngSnsChksm "UNM";
BA_ "VNSigAllNodes" SG_ 485 StrAngSnsChksm 1;
BA_ "SignalLongName" SG_ 485 StrWhAngGrdV "Steering Wheel Angle Gradient Validity";
BA_ "SignalType" SG_ 485 StrWhAngGrdV "ENM";
BA_ "VNSigAllNodes" SG_ 485 StrWhAngGrdV 1;
BA_ "SignalLongName" SG_ 485 StrWhAngGrdMsk "Steering Wheel Angle Gradient Mask";
BA_ "SignalType" SG_ 485 StrWhAngGrdMsk "ENM";
BA_ "VNSigAllNodes" SG_ 485 StrWhAngGrdMsk 1;
BA_ "SignalLongName" SG_ 485 StrWhAngMsk "Steering Wheel Angle Mask";
BA_ "SignalType" SG_ 485 StrWhAngMsk "ENM";
BA_ "VNSigAllNodes" SG_ 485 StrWhAngMsk 1;
BA_ "SignalLongName" SG_ 485 StrWhlAngSenTyp "Steering Wheel Angle Sensor Type";
BA_ "SignalType" SG_ 485 StrWhlAngSenTyp "ENM";
BA_ "VNSigAllNodes" SG_ 485 StrWhlAngSenTyp 1;
BA_ "SignalLongName" SG_ 485 StrWhAngGrd "Steering Wheel Angle Gradient";
BA_ "SignalType" SG_ 485 StrWhAngGrd "SNM";
BA_ "VNSigAllNodes" SG_ 485 StrWhAngGrd 1;
BA_ "SignalLongName" SG_ 485 StWhlAngAliveRollCnt "Steering Wheel Angle Alive Rolling Count";
BA_ "SignalType" SG_ 485 StWhlAngAliveRollCnt "UNM";
BA_ "VNSigAllNodes" SG_ 485 StWhlAngAliveRollCnt 1;
BA_ "SignalLongName" SG_ 485 StrWhlAngSenCalStat "Steering Wheel Angle Sensor Calibration Status";
BA_ "SignalType" SG_ 485 StrWhlAngSenCalStat "ENM";
BA_ "VNSigAllNodes" SG_ 485 StrWhlAngSenCalStat 1;
BA_ "SignalLongName" SG_ 485 StrWhAngV "Steering Wheel Angle Validity";
BA_ "SignalType" SG_ 485 StrWhAngV "ENM";
BA_ "VNSigAllNodes" SG_ 485 StrWhAngV 1;
BA_ "SignalLongName" SG_ 485 StrWhAng "Steering Wheel Angle";
BA_ "SignalType" SG_ 485 StrWhAng "SNM";
BA_ "VNSigAllNodes" SG_ 485 StrWhAng 1;
BA_ "SignalLongName" SG_ 1001 DistRollCntAvgDrvnSrc "Distance Rolling Count Average Driven Source";
BA_ "SignalType" SG_ 1001 DistRollCntAvgDrvnSrc "ENM";
BA_ "VNSigAllNodes" SG_ 1001 DistRollCntAvgDrvnSrc 1;
BA_ "SignalLongName" SG_ 1001 VehSpdAvgDrvnSrc "Vehicle Speed Average Driven Source";
BA_ "SignalType" SG_ 1001 VehSpdAvgDrvnSrc "ENM";
BA_ "VNSigAllNodes" SG_ 1001 VehSpdAvgDrvnSrc 1;
BA_ "SignalLongName" SG_ 1001 DstRolCntAvgNonDrvnV "Distance Rolling Count Average Non Driven Validity";
BA_ "SignalType" SG_ 1001 DstRolCntAvgNonDrvnV "ENM";
BA_ "VNSigAllNodes" SG_ 1001 DstRolCntAvgNonDrvnV 1;
BA_ "SignalLongName" SG_ 1001 DstRolCntAvNDrRstOc "Distance Rolling Count Average Non Driven Reset Occurred";
BA_ "SignalType" SG_ 1001 DstRolCntAvNDrRstOc "BLN";
BA_ "VNSigAllNodes" SG_ 1001 DstRolCntAvNDrRstOc 1;
BA_ "SignalLongName" SG_ 1001 DstRolCntAvgNonDrvn "Distance Rolling Count Average Non Driven";
BA_ "SignalType" SG_ 1001 DstRolCntAvgNonDrvn "UNM";
BA_ "VNSigAllNodes" SG_ 1001 DstRolCntAvgNonDrvn 1;
BA_ "SignalLongName" SG_ 1001 DistRollCntAvgDrvnV "Distance Rolling Count Average Driven Validity";
BA_ "SignalType" SG_ 1001 DistRollCntAvgDrvnV "ENM";
BA_ "VNSigAllNodes" SG_ 1001 DistRollCntAvgDrvnV 1;
BA_ "SignalLongName" SG_ 1001 DstRolCntAvgDrnRstOc "Distance Rolling Count Average Driven Reset Occurred";
BA_ "SignalType" SG_ 1001 DstRolCntAvgDrnRstOc "BLN";
BA_ "VNSigAllNodes" SG_ 1001 DstRolCntAvgDrnRstOc 1;
BA_ "SignalLongName" SG_ 1001 DistRollCntAvgDrvn "Distance Rolling Count Average Driven";
BA_ "SignalType" SG_ 1001 DistRollCntAvgDrvn "UNM";
BA_ "VNSigAllNodes" SG_ 1001 DistRollCntAvgDrvn 1;
BA_ "SignalLongName" SG_ 1001 VehSpdAvgNDrvnV "Vehicle Speed Average Non Driven Validity";
BA_ "SignalType" SG_ 1001 VehSpdAvgNDrvnV "ENM";
BA_ "VNSigAllNodes" SG_ 1001 VehSpdAvgNDrvnV 1;
BA_ "SignalLongName" SG_ 1001 VehSpdAvgNDrvn "Vehicle Speed Average Non Driven";
BA_ "SignalType" SG_ 1001 VehSpdAvgNDrvn "UNM";
BA_ "VNSigAllNodes" SG_ 1001 VehSpdAvgNDrvn 1;
BA_ "GenSigSendOnInit" SG_ 1001 VehSpdAvgNDrvn 1;
BA_ "SignalLongName" SG_ 1001 VehSpdAvgDrvnV "Vehicle Speed Average Driven Validity";
BA_ "SignalType" SG_ 1001 VehSpdAvgDrvnV "ENM";
BA_ "VNSigAllNodes" SG_ 1001 VehSpdAvgDrvnV 1;
BA_ "SignalLongName" SG_ 1001 VehSpdAvgDrvn "Vehicle Speed Average Driven";
BA_ "SignalType" SG_ 1001 VehSpdAvgDrvn "UNM";
BA_ "VNSigAllNodes" SG_ 1001 VehSpdAvgDrvn 1;
BA_ "SignalLongName" SG_ 961 PTImmblzerInfo "Powertrain Immobilizer Information";
BA_ "SignalType" SG_ 961 PTImmblzerInfo "UNM";
BA_ "VNSigAllNodes" SG_ 961 PTImmblzerInfo 1;
BA_ "SignalLongName" SG_ 842 WhlRotDrctnlSRtNDrvn "Wheel Rotational Directional Status Right Non Driven";
BA_ "SignalType" SG_ 842 WhlRotDrctnlSRtNDrvn "ENM";
BA_ "VNSigAllNodes" SG_ 842 WhlRotDrctnlSRtNDrvn 1;
BA_ "SignalLongName" SG_ 842 WhlRotDrctnlStLfNDrvn "Wheel Rotational Directional Status Left Non Driven";
BA_ "SignalType" SG_ 842 WhlRotDrctnlStLfNDrvn "ENM";
BA_ "VNSigAllNodes" SG_ 842 WhlRotDrctnlStLfNDrvn 1;
BA_ "SignalLongName" SG_ 842 WhlGrndVlctyRtNnDrvnV "Wheel Ground Velocity Right Non Driven Validity";
BA_ "SignalType" SG_ 842 WhlGrndVlctyRtNnDrvnV "ENM";
BA_ "VNSigAllNodes" SG_ 842 WhlGrndVlctyRtNnDrvnV 1;
BA_ "SignalLongName" SG_ 842 WhlGrndVlctyRtNnDrvn "Wheel Ground Velocity Right Non Driven";
BA_ "SignalType" SG_ 842 WhlGrndVlctyRtNnDrvn "UNM";
BA_ "VNSigAllNodes" SG_ 842 WhlGrndVlctyRtNnDrvn 1;
BA_ "SignalLongName" SG_ 842 WhlGrndVlctyLftNnDrvnV "Wheel Ground Velocity Left Non Driven Validity";
BA_ "SignalType" SG_ 842 WhlGrndVlctyLftNnDrvnV "ENM";
BA_ "VNSigAllNodes" SG_ 842 WhlGrndVlctyLftNnDrvnV 1;
BA_ "SignalLongName" SG_ 842 WhlGrndVlctyLftNnDrvn "Wheel Ground Velocity Left Non Driven";
BA_ "SignalType" SG_ 842 WhlGrndVlctyLftNnDrvn "UNM";
BA_ "VNSigAllNodes" SG_ 842 WhlGrndVlctyLftNnDrvn 1;
BA_ "SignalLongName" SG_ 1019 FuelLvlEmnsRelStat "Fuel Level Emissions Related Status";
BA_ "SignalType" SG_ 1019 FuelLvlEmnsRelStat "ENM";
BA_ "VNSigAllNodes" SG_ 1019 FuelLvlEmnsRelStat 1;
BA_ "SignalLongName" SG_ 1019 EmnsRelFuelLvlLw "Emissions Related Fuel Level Low";
BA_ "SignalType" SG_ 1019 EmnsRelFuelLvlLw "BLN";
BA_ "VNSigAllNodes" SG_ 1019 EmnsRelFuelLvlLw 1;
BA_ "SignalLongName" SG_ 1019 EngFuelCntlState "Engine Fuel Control State";
BA_ "SignalType" SG_ 1019 EngFuelCntlState "ENM";
BA_ "VNSigAllNodes" SG_ 1019 EngFuelCntlState 1;
BA_ "SignalLongName" SG_ 1019 FuelAlchlCompAdptnPrg "Fuel Alcohol Composition Adaptation in Progress";
BA_ "SignalType" SG_ 1019 FuelAlchlCompAdptnPrg "BLN";
BA_ "VNSigAllNodes" SG_ 1019 FuelAlchlCompAdptnPrg 1;
BA_ "SignalLongName" SG_ 1019 FuelAlcoholCompV "Fuel Alcohol Composition Validity";
BA_ "SignalType" SG_ 1019 FuelAlcoholCompV "ENM";
BA_ "VNSigAllNodes" SG_ 1019 FuelAlcoholCompV 1;
BA_ "SignalLongName" SG_ 1019 FuelAlcoholComp "Fuel Alcohol Composition";
BA_ "SignalType" SG_ 1019 FuelAlcoholComp "UNM";
BA_ "VNSigAllNodes" SG_ 1019 FuelAlcoholComp 1;
BA_ "SignalLongName" SG_ 1265 EngOffTmPT "Engine Off Time Powertrain";
BA_ "SignalType" SG_ 1265 EngOffTmPT "UNM";
BA_ "VNSigAllNodes" SG_ 1265 EngOffTmPT 1;
BA_ "SignalLongName" SG_ 1265 EngOffTmPTV "Engine Off Time Powertrain Validity";
BA_ "SignalType" SG_ 1265 EngOffTmPTV "ENM";
BA_ "VNSigAllNodes" SG_ 1265 EngOffTmPTV 1;
BA_ "SignalLongName" SG_ 1265 EngOffTmPTM "Engine Off Time Powertrain Mask";
BA_ "SignalType" SG_ 1265 EngOffTmPTM "ENM";
BA_ "VNSigAllNodes" SG_ 1265 EngOffTmPTM 1;
BA_ "SignalLongName" SG_ 1265 WhlDistPrRevNDrvn "Wheel Distance Per Revolution Non Driven";
BA_ "SignalType" SG_ 1265 WhlDistPrRevNDrvn "UNM";
BA_ "VNSigAllNodes" SG_ 1265 WhlDistPrRevNDrvn 1;
BA_ "SignalLongName" SG_ 1265 IdlRecmndToClEngIO "Idle Recommended to Cool Engine Indication On";
BA_ "SignalType" SG_ 1265 IdlRecmndToClEngIO "BLN";
BA_ "VNSigAllNodes" SG_ 1265 IdlRecmndToClEngIO 1;
BA_ "GenSigSendType" SG_ 1265 IdlRecmndToClEngIO 10;
BA_ "SignalLongName" SG_ 1265 WhlDistPrRevDrvn "Wheel Distance Per Revolution Driven";
BA_ "SignalType" SG_ 1265 WhlDistPrRevDrvn "UNM";
BA_ "VNSigAllNodes" SG_ 1265 WhlDistPrRevDrvn 1;
BA_ "SignalLongName" SG_ 1265 DrvlnFnlAxleRatio "Driveline Final Axle Ratio";
BA_ "SignalType" SG_ 1265 DrvlnFnlAxleRatio "UNM";
BA_ "VNSigAllNodes" SG_ 1265 DrvlnFnlAxleRatio 1;
BA_ "SignalLongName" SG_ 417 EngRunng "Engine Running";
BA_ "SignalType" SG_ 417 EngRunng "BLN";
BA_ "VNSigAllNodes" SG_ 417 EngRunng 1;
BA_ "SignalLongName" SG_ 417 EngCrsCntrlMode "Engine Cruise Control Mode";
BA_ "SignalType" SG_ 417 EngCrsCntrlMode "ENM";
BA_ "VNSigAllNodes" SG_ 417 EngCrsCntrlMode 1;
BA_ "SignalLongName" SG_ 417 EngPstOxgSnsDgAstRq "Engine Post Oxygen Sensor Diagnostic Assistance Requested";
BA_ "SignalType" SG_ 417 EngPstOxgSnsDgAstRq "BLN";
BA_ "VNSigAllNodes" SG_ 417 EngPstOxgSnsDgAstRq 1;
BA_ "SignalLongName" SG_ 417 CrsCtrlCnstSpdAct "Cruise Control Constant Speed Active";
BA_ "SignalType" SG_ 417 CrsCtrlCnstSpdAct "BLN";
BA_ "VNSigAllNodes" SG_ 417 CrsCtrlCnstSpdAct 1;
BA_ "SignalLongName" SG_ 417 WrmUpShftPtrnRq "Warm Up Shift Pattern Request";
BA_ "SignalType" SG_ 417 WrmUpShftPtrnRq "ENM";
BA_ "VNSigAllNodes" SG_ 417 WrmUpShftPtrnRq 1;
BA_ "SignalLongName" SG_ 417 EngIdlSpdRdcdRng "Engine Idle Speed Reduced Range";
BA_ "SignalType" SG_ 417 EngIdlSpdRdcdRng "UNM";
BA_ "VNSigAllNodes" SG_ 417 EngIdlSpdRdcdRng 1;
BA_ "SignalLongName" SG_ 417 EngAlwCltAdp "Engine Allowed Clutch Adaptation";
BA_ "SignalType" SG_ 417 EngAlwCltAdp "BLN";
BA_ "VNSigAllNodes" SG_ 417 EngAlwCltAdp 1;
BA_ "SignalLongName" SG_ 417 BsTrgtEngIdlSpd "Base Target Engine Idle Speed";
BA_ "SignalType" SG_ 417 BsTrgtEngIdlSpd "UNM";
BA_ "VNSigAllNodes" SG_ 417 BsTrgtEngIdlSpd 1;
BA_ "SignalLongName" SG_ 417 AccPdlPosPcntFullRngV "Accelerator Pedal Position Percent Full Range Validity";
BA_ "SignalType" SG_ 417 AccPdlPosPcntFullRngV "ENM";
BA_ "VNSigAllNodes" SG_ 417 AccPdlPosPcntFullRngV 1;
BA_ "SignalLongName" SG_ 417 AccPdlPosPcntFullRng "Accelerator Pedal Position Percent Full Range";
BA_ "SignalType" SG_ 417 AccPdlPosPcntFullRng "UNM";
BA_ "VNSigAllNodes" SG_ 417 AccPdlPosPcntFullRng 1;
BA_ "SignalLongName" SG_ 417 DslPrtFltrIdlRgtnMdReq "Diesel Particulate Filter Idle Regeneration Mode Request";
BA_ "SignalType" SG_ 417 DslPrtFltrIdlRgtnMdReq "BLN";
BA_ "VNSigAllNodes" SG_ 417 DslPrtFltrIdlRgtnMdReq 1;
BA_ "SignalLongName" SG_ 417 DslPartFltrClngAlgActM "Diesel Particle Filter Cleaning Algorithm Active Mask";
BA_ "SignalType" SG_ 417 DslPartFltrClngAlgActM "ENM";
BA_ "VNSigAllNodes" SG_ 417 DslPartFltrClngAlgActM 1;
BA_ "SignalLongName" SG_ 417 DslPartFltrClngAlgAct "Diesel Particle Filter Cleaning Algorithm Active";
BA_ "SignalType" SG_ 417 DslPartFltrClngAlgAct "BLN";
BA_ "VNSigAllNodes" SG_ 417 DslPartFltrClngAlgAct 1;
BA_ "SignalLongName" SG_ 417 EngCylDeactMd "Engine Cylinder Deactivation Mode";
BA_ "SignalType" SG_ 417 EngCylDeactMd "ENM";
BA_ "VNSigAllNodes" SG_ 417 EngCylDeactMd 1;
BA_ "SignalLongName" SG_ 417 ParkNeutralSwStatV "Park Neutral Switch Status Validity";
BA_ "SignalType" SG_ 417 ParkNeutralSwStatV "ENM";
BA_ "VNSigAllNodes" SG_ 417 ParkNeutralSwStatV 1;
BA_ "SignalLongName" SG_ 417 ParkNeutralSwStat "Park Neutral Switch Status";
BA_ "SignalType" SG_ 417 ParkNeutralSwStat "ENM";
BA_ "VNSigAllNodes" SG_ 417 ParkNeutralSwStat 1;
BA_ "SignalLongName" SG_ 417 EngColdHiIdleActive "Engine Cold High Idle Active";
BA_ "SignalType" SG_ 417 EngColdHiIdleActive "BLN";
BA_ "VNSigAllNodes" SG_ 417 EngColdHiIdleActive 1;
BA_ "SignalLongName" SG_ 417 EngCyDactTqSmtAct "Engine Cylinder Deactivation Torque Smoothing Active";
BA_ "SignalType" SG_ 417 EngCyDactTqSmtAct "BLN";
BA_ "VNSigAllNodes" SG_ 417 EngCyDactTqSmtAct 1;
BA_ "SignalLongName" SG_ 417 EngBrkStat "Engine Brake Status";
BA_ "SignalType" SG_ 417 EngBrkStat "ENM";
BA_ "VNSigAllNodes" SG_ 417 EngBrkStat 1;
BA_ "SignalLongName" SG_ 417 TracCntlSysPwrtrnInhbt "Traction Control System Powertrain Inhibit";
BA_ "SignalType" SG_ 417 TracCntlSysPwrtrnInhbt "BLN";
BA_ "VNSigAllNodes" SG_ 417 TracCntlSysPwrtrnInhbt 1;
BA_ "SignalLongName" SG_ 417 EngMtlProtAtv "Engine Metal Protection Active";
BA_ "SignalType" SG_ 417 EngMtlProtAtv "BLN";
BA_ "VNSigAllNodes" SG_ 417 EngMtlProtAtv 1;
BA_ "SignalLongName" SG_ 417 EngDgTrqCnvClUnlkRqd "Engine Diagnostic Torque Converter Clutch Unlock Requested";
BA_ "SignalType" SG_ 417 EngDgTrqCnvClUnlkRqd "BLN";
BA_ "VNSigAllNodes" SG_ 417 EngDgTrqCnvClUnlkRqd 1;
BA_ "SignalLongName" SG_ 417 EngCyldrDeactReqd "Engine Cylinder Deactivation Requested";
BA_ "SignalType" SG_ 417 EngCyldrDeactReqd "BLN";
BA_ "VNSigAllNodes" SG_ 417 EngCyldrDeactReqd 1;
BA_ "SignalLongName" SG_ 417 ETGRReqdGear "Engine Transmission Gear Request : Requested Gear";
BA_ "PacketOrder" SG_ 417 ETGRReqdGear 2;
BA_ "SignalType" SG_ 417 ETGRReqdGear "ENM";
BA_ "VNSigAllNodes" SG_ 417 ETGRReqdGear 1;
BA_ "SignalLongName" SG_ 417 ETGRReqType "Engine Transmission Gear Request : Request Type";
BA_ "PacketOrder" SG_ 417 ETGRReqType 1;
BA_ "SignalType" SG_ 417 ETGRReqType "ENM";
BA_ "VNSigAllNodes" SG_ 417 ETGRReqType 1;
BA_ "SignalLongName" SG_ 417 ACCmCltEngd "Air Conditioning Compressor Clutch Engaged";
BA_ "SignalType" SG_ 417 ACCmCltEngd "BLN";
BA_ "VNSigAllNodes" SG_ 417 ACCmCltEngd 1;
BA_ "SignalLongName" SG_ 1233 a_12VBatSysUnstab "12 Volt Battery System Unstable";
BA_ "SignalType" SG_ 1233 a_12VBatSysUnstab "BLN";
BA_ "VNSigAllNodes" SG_ 1233 a_12VBatSysUnstab 1;
BA_ "GenSigSendType" SG_ 1233 a_12VBatSysUnstab 10;
BA_ "SignalLongName" SG_ 1233 PTExPrtclFltWrng3IO "Powertrain Exhaust Particle Filter Warning 3 Indication On";
BA_ "SignalType" SG_ 1233 PTExPrtclFltWrng3IO "BLN";
BA_ "VNSigAllNodes" SG_ 1233 PTExPrtclFltWrng3IO 1;
BA_ "GenSigSendType" SG_ 1233 PTExPrtclFltWrng3IO 10;
BA_ "SignalLongName" SG_ 1233 PTExPartFltManRegStat "Powertrain Exhaust Particle Filter Manual Regeneration Status";
BA_ "SignalType" SG_ 1233 PTExPartFltManRegStat "ENM";
BA_ "VNSigAllNodes" SG_ 1233 PTExPartFltManRegStat 1;
BA_ "GenSigSendType" SG_ 1233 PTExPartFltManRegStat 10;
BA_ "SignalLongName" SG_ 1233 EngShtdwnAct "Engine Shutdown Active";
BA_ "SignalType" SG_ 1233 EngShtdwnAct "BLN";
BA_ "VNSigAllNodes" SG_ 1233 EngShtdwnAct 1;
BA_ "SignalLongName" SG_ 1233 EngShtdwnPndgIO "Engine Shutdown Pending Indication On";
BA_ "SignalType" SG_ 1233 EngShtdwnPndgIO "BLN";
BA_ "VNSigAllNodes" SG_ 1233 EngShtdwnPndgIO 1;
BA_ "SignalLongName" SG_ 1233 FuelFltChgNwIO "Fuel Filter Change Now Indication On";
BA_ "SignalType" SG_ 1233 FuelFltChgNwIO "BLN";
BA_ "VNSigAllNodes" SG_ 1233 FuelFltChgNwIO 1;
BA_ "SignalLongName" SG_ 1233 PTExPrtclFltrWrn2IO "Powertrain Exhaust Particle Filter Warning 2 Indication On";
BA_ "SignalType" SG_ 1233 PTExPrtclFltrWrn2IO "BLN";
BA_ "VNSigAllNodes" SG_ 1233 PTExPrtclFltrWrn2IO 1;
BA_ "SignalLongName" SG_ 1233 PTHiElecLdReqd "Powertrain High Electrical Load Requested";
BA_ "SignalType" SG_ 1233 PTHiElecLdReqd "BLN";
BA_ "VNSigAllNodes" SG_ 1233 PTHiElecLdReqd 1;
BA_ "SignalLongName" SG_ 1233 PTExPrtclFltrWrnIO "Powertrain Exhaust Particle Filter Warning Indication On";
BA_ "SignalType" SG_ 1233 PTExPrtclFltrWrnIO "BLN";
BA_ "VNSigAllNodes" SG_ 1233 PTExPrtclFltrWrnIO 1;
BA_ "SignalLongName" SG_ 1233 AirCndOffIO "Air Conditioning Off Indication On";
BA_ "SignalType" SG_ 1233 AirCndOffIO "BLN";
BA_ "VNSigAllNodes" SG_ 1233 AirCndOffIO 1;
BA_ "SignalLongName" SG_ 1233 DslGlwPlgIO "Diesel Glow Plug Indication On";
BA_ "SignalType" SG_ 1233 DslGlwPlgIO "BLN";
BA_ "VNSigAllNodes" SG_ 1233 DslGlwPlgIO 1;
BA_ "GenSigSendType" SG_ 1233 DslGlwPlgIO 10;
BA_ "SignalLongName" SG_ 1233 RdcdPwrIO "Reduced Power Indication On";
BA_ "SignalType" SG_ 1233 RdcdPwrIO "BLN";
BA_ "VNSigAllNodes" SG_ 1233 RdcdPwrIO 1;
BA_ "SignalLongName" SG_ 1233 FuelTotCap "Fuel Total Capacity";
BA_ "SignalType" SG_ 1233 FuelTotCap "UNM";
BA_ "VNSigAllNodes" SG_ 1233 FuelTotCap 1;
BA_ "GenSigSendOnInit" SG_ 1233 FuelTotCap 1;
BA_ "SignalLongName" SG_ 1233 FlLvlPctV "Fuel Level Percent Validity";
BA_ "SignalType" SG_ 1233 FlLvlPctV "ENM";
BA_ "VNSigAllNodes" SG_ 1233 FlLvlPctV 1;
BA_ "GenSigSendOnInit" SG_ 1233 FlLvlPctV 1;
BA_ "SignalLongName" SG_ 1233 FlLvlPct "Fuel Level Percent";
BA_ "SignalType" SG_ 1233 FlLvlPct "UNM";
BA_ "VNSigAllNodes" SG_ 1233 FlLvlPct 1;
BA_ "GenSigDeltaValue" SG_ 1233 FlLvlPct 2;
BA_ "GenSigSendOnInit" SG_ 1233 FlLvlPct 1;
BA_ "SignalLongName" SG_ 1233 EngWtrInFlIO "Engine Water In Fuel Indication On";
BA_ "SignalType" SG_ 1233 EngWtrInFlIO "BLN";
BA_ "VNSigAllNodes" SG_ 1233 EngWtrInFlIO 1;
BA_ "SignalLongName" SG_ 1233 EngOilTmpV "Engine Oil Temperature Validity";
BA_ "SignalType" SG_ 1233 EngOilTmpV "ENM";
BA_ "VNSigAllNodes" SG_ 1233 EngOilTmpV 1;
BA_ "SignalLongName" SG_ 1233 EngOilTmp "Engine Oil Temperature";
BA_ "SignalType" SG_ 1233 EngOilTmp "UNM";
BA_ "VNSigAllNodes" SG_ 1233 EngOilTmp 1;
BA_ "SignalLongName" SG_ 1233 EngOilPrsV "Engine Oil Pressure Validity";
BA_ "SignalType" SG_ 1233 EngOilPrsV "ENM";
BA_ "VNSigAllNodes" SG_ 1233 EngOilPrsV 1;
BA_ "SignalLongName" SG_ 1233 EngOilPrsLwIO "Engine Oil Pressure Low Indication On";
BA_ "SignalType" SG_ 1233 EngOilPrsLwIO "BLN";
BA_ "VNSigAllNodes" SG_ 1233 EngOilPrsLwIO 1;
BA_ "SignalLongName" SG_ 1233 EngOilPrs "Engine Oil Pressure";
BA_ "SignalType" SG_ 1233 EngOilPrs "UNM";
BA_ "VNSigAllNodes" SG_ 1233 EngOilPrs 1;
BA_ "SignalLongName" SG_ 1233 EngOilLvlLwIO "Engine Oil Level Low Indication On";
BA_ "SignalType" SG_ 1233 EngOilLvlLwIO "BLN";
BA_ "VNSigAllNodes" SG_ 1233 EngOilLvlLwIO 1;
BA_ "SignalLongName" SG_ 1233 EngOilChngIO "Engine Oil Change Indication On";
BA_ "SignalType" SG_ 1233 EngOilChngIO "BLN";
BA_ "VNSigAllNodes" SG_ 1233 EngOilChngIO 1;
BA_ "SignalLongName" SG_ 1233 EngHt_StpEngIO "Engine Hot / Stop Engine Indication On";
BA_ "SignalType" SG_ 1233 EngHt_StpEngIO "BLN";
BA_ "VNSigAllNodes" SG_ 1233 EngHt_StpEngIO 1;
BA_ "SignalLongName" SG_ 1233 EngHotFuelEnrchmntIO "Engine Hot Fuel Enrichment Indication On";
BA_ "SignalType" SG_ 1233 EngHotFuelEnrchmntIO "BLN";
BA_ "VNSigAllNodes" SG_ 1233 EngHotFuelEnrchmntIO 1;
BA_ "SignalLongName" SG_ 1233 CkFlFilrCapIO "Check Fuel Filler Cap Indication On";
BA_ "SignalType" SG_ 1233 CkFlFilrCapIO "BLN";
BA_ "VNSigAllNodes" SG_ 1233 CkFlFilrCapIO 1;
BA_ "SignalLongName" SG_ 1217 LDMaxEngCltTmpRchd "Legislated Diagnostics Maximum Engine Coolant Temperature Reached";
BA_ "SignalType" SG_ 1217 LDMaxEngCltTmpRchd "BLN";
BA_ "VNSigAllNodes" SG_ 1217 LDMaxEngCltTmpRchd 1;
BA_ "SignalLongName" SG_ 1217 LDMinEngCltTmpRchd "Legislated Diagnostics Minimum Engine Coolant Temperature Reached";
BA_ "SignalType" SG_ 1217 LDMinEngCltTmpRchd "BLN";
BA_ "VNSigAllNodes" SG_ 1217 LDMinEngCltTmpRchd 1;
BA_ "SignalLongName" SG_ 1217 CdClrInhbt "Code Clear Inhibit";
BA_ "SignalType" SG_ 1217 CdClrInhbt "BLN";
BA_ "VNSigAllNodes" SG_ 1217 CdClrInhbt 1;
BA_ "SignalLongName" SG_ 1217 LegPstDTCClrDrvCyCm "Legislated Post DTC Clear Drive Cycle Complete";
BA_ "SignalType" SG_ 1217 LegPstDTCClrDrvCyCm "BLN";
BA_ "VNSigAllNodes" SG_ 1217 LegPstDTCClrDrvCyCm 1;
BA_ "SignalLongName" SG_ 1217 EngIntAirTmpM "Engine Intake Air Temperature Mask";
BA_ "SignalType" SG_ 1217 EngIntAirTmpM "ENM";
BA_ "VNSigAllNodes" SG_ 1217 EngIntAirTmpM 1;
BA_ "SignalLongName" SG_ 1217 LegDiagColdStCndMet "Legislated Diagnostics Cold Start Conditions Met";
BA_ "SignalType" SG_ 1217 LegDiagColdStCndMet "BLN";
BA_ "VNSigAllNodes" SG_ 1217 LegDiagColdStCndMet 1;
BA_ "SignalLongName" SG_ 1217 LegDiagColdStCndFltPr "Legislated Diagnostics Cold Start Conditions Fault Present";
BA_ "SignalType" SG_ 1217 LegDiagColdStCndFltPr "BLN";
BA_ "VNSigAllNodes" SG_ 1217 LegDiagColdStCndFltPr 1;
BA_ "SignalLongName" SG_ 1217 LegDiagStndCndMet "Legislated Diagnostics Standard Conditions Met";
BA_ "SignalType" SG_ 1217 LegDiagStndCndMet "BLN";
BA_ "VNSigAllNodes" SG_ 1217 LegDiagStndCndMet 1;
BA_ "SignalLongName" SG_ 1217 LegDiagStndCndFltPr "Legislated Diagnostics Standard Conditions Fault Present";
BA_ "SignalType" SG_ 1217 LegDiagStndCndFltPr "BLN";
BA_ "VNSigAllNodes" SG_ 1217 LegDiagStndCndFltPr 1;
BA_ "SignalLongName" SG_ 1217 EngWrmUpAch "Engine Warm Up Cycle Achieved";
BA_ "SignalType" SG_ 1217 EngWrmUpAch "BLN";
BA_ "VNSigAllNodes" SG_ 1217 EngWrmUpAch 1;
BA_ "SignalLongName" SG_ 1217 DslExhFldRmngDstHRsV "Diesel Exhaust Fluid Remaining Distance High Resolution Validity";
BA_ "SignalType" SG_ 1217 DslExhFldRmngDstHRsV "ENM";
BA_ "VNSigAllNodes" SG_ 1217 DslExhFldRmngDstHRsV 1;
BA_ "SignalLongName" SG_ 1217 DslExhFldRmngDstHRs "Diesel Exhaust Fluid Remaining Distance High Resolution";
BA_ "SignalType" SG_ 1217 DslExhFldRmngDstHRs "UNM";
BA_ "VNSigAllNodes" SG_ 1217 DslExhFldRmngDstHRs 1;
BA_ "SignalLongName" SG_ 1217 EngOilHotIO "Engine Oil Hot Indication On";
BA_ "SignalType" SG_ 1217 EngOilHotIO "BLN";
BA_ "VNSigAllNodes" SG_ 1217 EngOilHotIO 1;
BA_ "SignalLongName" SG_ 1217 OAT_PT_EstV "Outside Air Temperature Powertrain Estimated Validity";
BA_ "SignalType" SG_ 1217 OAT_PT_EstV "ENM";
BA_ "VNSigAllNodes" SG_ 1217 OAT_PT_EstV 1;
BA_ "SignalLongName" SG_ 1217 OAT_PT_EstM "Outside Air Temperature Powertrain Estimated Mask";
BA_ "SignalType" SG_ 1217 OAT_PT_EstM "ENM";
BA_ "VNSigAllNodes" SG_ 1217 OAT_PT_EstM 1;
BA_ "SignalLongName" SG_ 1217 OAT_PT_Est "Outside Air Temperature Powertrain Estimated";
BA_ "SignalType" SG_ 1217 OAT_PT_Est "UNM";
BA_ "VNSigAllNodes" SG_ 1217 OAT_PT_Est 1;
BA_ "SignalLongName" SG_ 1217 EngIntAirTmpV "Engine Intake Air Temperature Validity";
BA_ "SignalType" SG_ 1217 EngIntAirTmpV "ENM";
BA_ "VNSigAllNodes" SG_ 1217 EngIntAirTmpV 1;
BA_ "SignalLongName" SG_ 1217 EngIntAirTmp "Engine Intake Air Temperature";
BA_ "SignalType" SG_ 1217 EngIntAirTmp "UNM";
BA_ "VNSigAllNodes" SG_ 1217 EngIntAirTmp 1;
BA_ "SignalLongName" SG_ 1217 EngCltTmpV "Engine Coolant Temperature Validity";
BA_ "SignalType" SG_ 1217 EngCltTmpV "ENM";
BA_ "VNSigAllNodes" SG_ 1217 EngCltTmpV 1;
BA_ "GenSigSendOnInit" SG_ 1217 EngCltTmpV 1;
BA_ "SignalLongName" SG_ 1217 EngCltTmp "Engine Coolant Temperature";
BA_ "SignalType" SG_ 1217 EngCltTmp "UNM";
BA_ "VNSigAllNodes" SG_ 1217 EngCltTmp 1;
BA_ "GenSigSendOnInit" SG_ 1217 EngCltTmp 1;
BA_ "SignalLongName" SG_ 1217 BarPrsAbsV "Barometric Pressure Absolute Validity";
BA_ "SignalType" SG_ 1217 BarPrsAbsV "ENM";
BA_ "VNSigAllNodes" SG_ 1217 BarPrsAbsV 1;
BA_ "SignalLongName" SG_ 1217 BarPrsAbs "Barometric Pressure Absolute";
BA_ "SignalType" SG_ 1217 BarPrsAbs "UNM";
BA_ "VNSigAllNodes" SG_ 1217 BarPrsAbs 1;
BA_ "SignalLongName" SG_ 665 EngFuelCntlState_299 "Engine Fuel Control State";
BA_ "SignalType" SG_ 665 EngFuelCntlState_299 "ENM";
BA_ "VNSigAllNodes" SG_ 665 EngFuelCntlState_299 1;
BA_ "SignalLongName" SG_ 665 TotAltFClsLpCBn2LwRes "Total Alternative Fuel Closed Loop Correction Bank 2 Low Resolution";
BA_ "SignalType" SG_ 665 TotAltFClsLpCBn2LwRes "SNM";
BA_ "VNSigAllNodes" SG_ 665 TotAltFClsLpCBn2LwRes 1;
BA_ "SignalLongName" SG_ 665 TotAltFClsLpCBn1LwRes "Total Alternative Fuel Closed Loop Correction Bank 1 Low Resolution";
BA_ "SignalType" SG_ 665 TotAltFClsLpCBn1LwRes "SNM";
BA_ "VNSigAllNodes" SG_ 665 TotAltFClsLpCBn1LwRes 1;
BA_ "SignalLongName" SG_ 665 RelBsAltFuelMassLwRes "Relative Base Alternative Fuel Mass Low Resolution";
BA_ "SignalType" SG_ 665 RelBsAltFuelMassLwRes "UNM";
BA_ "VNSigAllNodes" SG_ 665 RelBsAltFuelMassLwRes 1;
BA_ "SignalLongName" SG_ 665 RdGasFuelDsblAct "Redundant Gaseous Fuel Disable Active";
BA_ "SignalType" SG_ 665 RdGasFuelDsblAct "BLN";
BA_ "VNSigAllNodes" SG_ 665 RdGasFuelDsblAct 1;
BA_ "SignalLongName" SG_ 665 RdDistFuelMdCmd "Redundant Distributed Fuel Mode Command";
BA_ "SignalType" SG_ 665 RdDistFuelMdCmd "ENM";
BA_ "VNSigAllNodes" SG_ 665 RdDistFuelMdCmd 1;
BA_ "SignalLongName" SG_ 665 PetrolFuelSysReqAval "Petrol Fuel System Request Availability";
BA_ "SignalType" SG_ 665 PetrolFuelSysReqAval "ENM";
BA_ "VNSigAllNodes" SG_ 665 PetrolFuelSysReqAval 1;
BA_ "SignalLongName" SG_ 665 AltFuelSysReqAlwd "Alternative Fuel System Request Allowed";
BA_ "SignalType" SG_ 665 AltFuelSysReqAlwd "BLN";
BA_ "VNSigAllNodes" SG_ 665 AltFuelSysReqAlwd 1;
BA_ "SignalLongName" SG_ 665 AltFuelInjHCmdLwRes "Alternative Fuel Injector H Command Low Resolution";
BA_ "SignalType" SG_ 665 AltFuelInjHCmdLwRes "ENM";
BA_ "VNSigAllNodes" SG_ 665 AltFuelInjHCmdLwRes 1;
BA_ "SignalLongName" SG_ 665 AltFuelInjGCmdLwRes "Alternative Fuel Injector G Command Low Resolution";
BA_ "SignalType" SG_ 665 AltFuelInjGCmdLwRes "ENM";
BA_ "VNSigAllNodes" SG_ 665 AltFuelInjGCmdLwRes 1;
BA_ "SignalLongName" SG_ 665 AltFuelInjFCmdLwRes "Alternative Fuel Injector F Command Low Resolution";
BA_ "SignalType" SG_ 665 AltFuelInjFCmdLwRes "ENM";
BA_ "VNSigAllNodes" SG_ 665 AltFuelInjFCmdLwRes 1;
BA_ "SignalLongName" SG_ 665 AltFuelInjECmdLwRes "Alternative Fuel Injector E Command Low Resolution";
BA_ "SignalType" SG_ 665 AltFuelInjECmdLwRes "ENM";
BA_ "VNSigAllNodes" SG_ 665 AltFuelInjECmdLwRes 1;
BA_ "SignalLongName" SG_ 665 AltFuelInjDCmdLwRes "Alternative Fuel Injector D Command Low Resolution";
BA_ "SignalType" SG_ 665 AltFuelInjDCmdLwRes "ENM";
BA_ "VNSigAllNodes" SG_ 665 AltFuelInjDCmdLwRes 1;
BA_ "SignalLongName" SG_ 665 AltFuelInjCCmdLwRes "Alternative Fuel Injector C Command Low Resolution";
BA_ "SignalType" SG_ 665 AltFuelInjCCmdLwRes "ENM";
BA_ "VNSigAllNodes" SG_ 665 AltFuelInjCCmdLwRes 1;
BA_ "SignalLongName" SG_ 665 AltFuelInjBCmdLwRes "Alternative Fuel Injector B Command Low Resolution";
BA_ "SignalType" SG_ 665 AltFuelInjBCmdLwRes "ENM";
BA_ "VNSigAllNodes" SG_ 665 AltFuelInjBCmdLwRes 1;
BA_ "SignalLongName" SG_ 665 AltFuelInjACmdLwRes "Alternative Fuel Injector A Command Low Resolution";
BA_ "SignalType" SG_ 665 AltFuelInjACmdLwRes "ENM";
BA_ "VNSigAllNodes" SG_ 665 AltFuelInjACmdLwRes 1;
BA_ "SignalLongName" SG_ 665 BiFuelRflGaslinIndReq "Bi Fuel Refill Gasoline Indication Request";
BA_ "SignalType" SG_ 665 BiFuelRflGaslinIndReq "ENM";
BA_ "VNSigAllNodes" SG_ 665 BiFuelRflGaslinIndReq 1;
BA_ "GenSigSendType" SG_ 665 BiFuelRflGaslinIndReq 10;
BA_REL_ "GenSigTimeoutTime" BU_SG_REL_ BCM_HS SG_ 463 FourWhlDrvIndReq 250;
BA_REL_ "GenSigTimeoutMsg" BU_SG_REL_ BCM_HS SG_ 463 FourWhlDrvIndReq 463;
BA_REL_ "GenSigSuprvResp" BU_SG_REL_ BCM_HS SG_ 463 FourWhlDrvIndReq 1;
BA_REL_ "GenSigTimeoutTime" BU_SG_REL_ BCM_HS SG_ 463 TrnsfrCsRngShfSpdLmt 250;
BA_REL_ "GenSigTimeoutMsg" BU_SG_REL_ BCM_HS SG_ 463 TrnsfrCsRngShfSpdLmt 463;
BA_REL_ "GenSigSuprvResp" BU_SG_REL_ BCM_HS SG_ 463 TrnsfrCsRngShfSpdLmt 1;
BA_REL_ "GenSigTimeoutTime" BU_SG_REL_ BCM_HS SG_ 463 SecAxlNonEmMalfIO 250;
BA_REL_ "GenSigTimeoutMsg" BU_SG_REL_ BCM_HS SG_ 463 SecAxlNonEmMalfIO 463;
BA_REL_ "GenSigSuprvResp" BU_SG_REL_ BCM_HS SG_ 463 SecAxlNonEmMalfIO 1;
BA_REL_ "GenSigTimeoutTime" BU_SG_REL_ EBCM_HS SG_ 463 SecAxlOperMod 500;
BA_REL_ "GenSigTimeoutMsg" BU_SG_REL_ EBCM_HS SG_ 463 SecAxlOperMod 463;
BA_REL_ "GenSigSuprvResp" BU_SG_REL_ EBCM_HS SG_ 463 SecAxlOperMod 1;
BA_REL_ "GenSigTimeoutTime" BU_SG_REL_ BSM_HS SG_ 463 SecAxlOperMod 500;
BA_REL_ "GenSigTimeoutMsg" BU_SG_REL_ BSM_HS SG_ 463 SecAxlOperMod 463;
BA_REL_ "GenSigSuprvResp" BU_SG_REL_ BSM_HS SG_ 463 SecAxlOperMod 1;
BA_REL_ "GenSigTimeoutTime" BU_SG_REL_ BCM_HS SG_ 463 SecAxlOperMod 250;
BA_REL_ "GenSigTimeoutMsg" BU_SG_REL_ BCM_HS SG_ 463 SecAxlOperMod 463;
BA_REL_ "GenSigSuprvResp" BU_SG_REL_ BCM_HS SG_ 463 SecAxlOperMod 1;
BA_REL_ "GenSigTimeoutTime" BU_SG_REL_ BCM_HS SG_ 869 TnDrvGapAdjUnbIO 250;
BA_REL_ "GenSigTimeoutMsg" BU_SG_REL_ BCM_HS SG_ 869 TnDrvGapAdjUnbIO 869;
BA_REL_ "GenSigSuprvResp" BU_SG_REL_ BCM_HS SG_ 869 TnDrvGapAdjUnbIO 1;
BA_REL_ "GenSigTimeoutTime" BU_SG_REL_ BCM_HS SG_ 869 FwdClnMtgnBrkReqAct 250;
BA_REL_ "GenSigTimeoutMsg" BU_SG_REL_ BCM_HS SG_ 869 FwdClnMtgnBrkReqAct 869;
BA_REL_ "GenSigSuprvResp" BU_SG_REL_ BCM_HS SG_ 869 FwdClnMtgnBrkReqAct 1;
BA_REL_ "GenSigTimeoutTime" BU_SG_REL_ BCM_HS SG_ 869 FCACustStngAvlbl 250;
BA_REL_ "GenSigSuprvResp" BU_SG_REL_ BCM_HS SG_ 869 FCACustStngAvlbl 1;
BA_REL_ "GenSigTimeoutTime" BU_SG_REL_ BCM_HS SG_ 869 FwdClnAlrtCustCrntSetngVal 250;
BA_REL_ "GenSigSuprvResp" BU_SG_REL_ BCM_HS SG_ 869 FwdClnAlrtCustCrntSetngVal 1;
BA_REL_ "GenSigTimeoutTime" BU_SG_REL_ BCM_HS SG_ 869 GNCustSetngAvlbl 250;
BA_REL_ "GenSigSuprvResp" BU_SG_REL_ BCM_HS SG_ 869 GNCustSetngAvlbl 1;
BA_REL_ "GenSigTimeoutTime" BU_SG_REL_ BCM_HS SG_ 869 CPSUnblIO 250;
BA_REL_ "GenSigSuprvResp" BU_SG_REL_ BCM_HS SG_ 869 CPSUnblIO 1;
BA_REL_ "GenSigTimeoutTime" BU_SG_REL_ BCM_HS SG_ 869 ColPrSysStngAvl 250;
BA_REL_ "GenSigSuprvResp" BU_SG_REL_ BCM_HS SG_ 869 ColPrSysStngAvl 1;
BA_REL_ "GenSigTimeoutTime" BU_SG_REL_ BCM_HS SG_ 869 CPSOffIO 250;
BA_REL_ "GenSigSuprvResp" BU_SG_REL_ BCM_HS SG_ 869 CPSOffIO 1;
BA_REL_ "GenSigTimeoutTime" BU_SG_REL_ BCM_HS SG_ 869 CPSFldIO 250;
BA_REL_ "GenSigSuprvResp" BU_SG_REL_ BCM_HS SG_ 869 CPSFldIO 1;
BA_REL_ "GenSigTimeoutTime" BU_SG_REL_ BCM_HS SG_ 869 ColPrSysCrntStng 250;
BA_REL_ "GenSigSuprvResp" BU_SG_REL_ BCM_HS SG_ 869 ColPrSysCrntStng 1;
BA_REL_ "GenSigTimeoutTime" BU_SG_REL_ BCM_HS SG_ 869 CPSAlrtOnlIO 250;
BA_REL_ "GenSigSuprvResp" BU_SG_REL_ BCM_HS SG_ 869 CPSAlrtOnlIO 1;
BA_REL_ "GenSigTimeoutTime" BU_SG_REL_ BCM_HS SG_ 869 GNCustCrntStngVal 250;
BA_REL_ "GenSigSuprvResp" BU_SG_REL_ BCM_HS SG_ 869 GNCustCrntStngVal 1;
BA_REL_ "GenSigTimeoutTime" BU_SG_REL_ BCM_HS SG_ 564 AdptDrvrSeatStng 250;
BA_REL_ "GenSigTimeoutMsg" BU_SG_REL_ BCM_HS SG_ 564 AdptDrvrSeatStng 564;
BA_REL_ "GenSigSuprvResp" BU_SG_REL_ BCM_HS SG_ 564 AdptDrvrSeatStng 1;
BA_REL_ "GenSigTimeoutTime" BU_SG_REL_ BCM_HS SG_ 564 AdptPsngrSeatStng 250;
BA_REL_ "GenSigTimeoutMsg" BU_SG_REL_ BCM_HS SG_ 564 AdptPsngrSeatStng 564;
BA_REL_ "GenSigSuprvResp" BU_SG_REL_ BCM_HS SG_ 564 AdptPsngrSeatStng 1;
BA_REL_ "GenSigTimeoutTime" BU_SG_REL_ BCM_HS SG_ 564 TnDrvTrCtrlOffUnbIO 250;
BA_REL_ "GenSigTimeoutMsg" BU_SG_REL_ BCM_HS SG_ 564 TnDrvTrCtrlOffUnbIO 564;
BA_REL_ "GenSigSuprvResp" BU_SG_REL_ BCM_HS SG_ 564 TnDrvTrCtrlOffUnbIO 1;
BA_REL_ "GenSigTimeoutTime" BU_SG_REL_ BCM_HS SG_ 564 TnDrvStblCtrlOffUnbIO 250;
BA_REL_ "GenSigTimeoutMsg" BU_SG_REL_ BCM_HS SG_ 564 TnDrvStblCtrlOffUnbIO 564;
BA_REL_ "GenSigSuprvResp" BU_SG_REL_ BCM_HS SG_ 564 TnDrvStblCtrlOffUnbIO 1;
BA_REL_ "GenSigTimeoutTime" BU_SG_REL_ BCM_HS SG_ 564 TrlrStabAstActIO 250;
BA_REL_ "GenSigTimeoutMsg" BU_SG_REL_ BCM_HS SG_ 564 TrlrStabAstActIO 564;
BA_REL_ "GenSigSuprvResp" BU_SG_REL_ BCM_HS SG_ 564 TrlrStabAstActIO 1;
BA_REL_ "GenSigTimeoutTime" BU_SG_REL_ BCM_HS SG_ 1296 ACCAutoSetSpdStat 250;
BA_REL_ "GenSigTimeoutMsg" BU_SG_REL_ BCM_HS SG_ 1296 ACCAutoSetSpdStat 1296;
BA_REL_ "GenSigSuprvResp" BU_SG_REL_ BCM_HS SG_ 1296 ACCAutoSetSpdStat 1;
BA_REL_ "GenSigTimeoutTime" BU_SG_REL_ EBCM_HS SG_ 848 TrlrBrkStat 250;
BA_REL_ "GenSigTimeoutMsg" BU_SG_REL_ EBCM_HS SG_ 848 TrlrBrkStat 848;
BA_REL_ "GenSigSuprvResp" BU_SG_REL_ EBCM_HS SG_ 848 TrlrBrkStat 1;
BA_REL_ "GenSigTimeoutTime" BU_SG_REL_ EBCM_HS SG_ 848 TrlrBrkngGainSet 250;
BA_REL_ "GenSigTimeoutMsg" BU_SG_REL_ EBCM_HS SG_ 848 TrlrBrkngGainSet 848;
BA_REL_ "GenSigSuprvResp" BU_SG_REL_ EBCM_HS SG_ 848 TrlrBrkngGainSet 1;
BA_REL_ "GenSigTimeoutTime" BU_SG_REL_ EBCM_HS SG_ 848 TrlrBrkngFrcOtpt 250;
BA_REL_ "GenSigTimeoutMsg" BU_SG_REL_ EBCM_HS SG_ 848 TrlrBrkngFrcOtpt 848;
BA_REL_ "GenSigSuprvResp" BU_SG_REL_ EBCM_HS SG_ 848 TrlrBrkngFrcOtpt 1;
BA_REL_ "GenSigTimeoutTime" BU_SG_REL_ BCM_HS SG_ 848 TrlrHtchSwAtv_ITBC 250;
BA_REL_ "GenSigTimeoutMsg" BU_SG_REL_ BCM_HS SG_ 848 TrlrHtchSwAtv_ITBC 848;
BA_REL_ "GenSigSuprvResp" BU_SG_REL_ BCM_HS SG_ 848 TrlrHtchSwAtv_ITBC 1;
BA_REL_ "GenSigTimeoutTime" BU_SG_REL_ BCM_HS SG_ 1011 BatVltHiRes 625;
BA_REL_ "GenSigTimeoutMsg" BU_SG_REL_ BCM_HS SG_ 1011 BatVltHiRes 1011;
BA_REL_ "GenSigSuprvResp" BU_SG_REL_ BCM_HS SG_ 1011 BatVltHiRes 1;
BA_REL_ "GenSigTimeoutTime" BU_SG_REL_ BCM_HS SG_ 1011 BatCrntExtRng 625;
BA_REL_ "GenSigTimeoutMsg" BU_SG_REL_ BCM_HS SG_ 1011 BatCrntExtRng 1011;
BA_REL_ "GenSigSuprvResp" BU_SG_REL_ BCM_HS SG_ 1011 BatCrntExtRng 1;
BA_REL_ "GenSigTimeoutTime" BU_SG_REL_ BCM_HS SG_ 1011 BatSnsrlntFlt 625;
BA_REL_ "GenSigTimeoutMsg" BU_SG_REL_ BCM_HS SG_ 1011 BatSnsrlntFlt 1011;
BA_REL_ "GenSigSuprvResp" BU_SG_REL_ BCM_HS SG_ 1011 BatSnsrlntFlt 1;
BA_REL_ "GenSigTimeoutTime" BU_SG_REL_ BCM_HS SG_ 993 SvcHybridSysIO 250;
BA_REL_ "GenSigTimeoutMsg" BU_SG_REL_ BCM_HS SG_ 993 SvcHybridSysIO 993;
BA_REL_ "GenSigSuprvResp" BU_SG_REL_ BCM_HS SG_ 993 SvcHybridSysIO 1;
BA_REL_ "GenSigTimeoutTime" BU_SG_REL_ BCM_HS SG_ 490 SrvcFlSysPrkInOpnArIO 250;
BA_REL_ "GenSigTimeoutMsg" BU_SG_REL_ BCM_HS SG_ 490 SrvcFlSysPrkInOpnArIO 490;
BA_REL_ "GenSigSuprvResp" BU_SG_REL_ BCM_HS SG_ 490 SrvcFlSysPrkInOpnArIO 1;
BA_REL_ "GenSigTimeoutTime" BU_SG_REL_ BCM_HS SG_ 490 FuelSysNEmsRltMalfAct 250;
BA_REL_ "GenSigTimeoutMsg" BU_SG_REL_ BCM_HS SG_ 490 FuelSysNEmsRltMalfAct 490;
BA_REL_ "GenSigSuprvResp" BU_SG_REL_ BCM_HS SG_ 490 FuelSysNEmsRltMalfAct 1;
BA_REL_ "GenSigTimeoutTime" BU_SG_REL_ BCM_HS SG_ 490 InActFuelMdFuelLvlIO 250;
BA_REL_ "GenSigTimeoutMsg" BU_SG_REL_ BCM_HS SG_ 490 InActFuelMdFuelLvlIO 490;
BA_REL_ "GenSigSuprvResp" BU_SG_REL_ BCM_HS SG_ 490 InActFuelMdFuelLvlIO 1;
BA_REL_ "GenSigTimeoutTime" BU_SG_REL_ EBCM_HS SG_ 452 FSpRgACCSwADd 250;
BA_REL_ "GenSigTimeoutMsg" BU_SG_REL_ EBCM_HS SG_ 452 FSpRgACCSwADd 452;
BA_REL_ "GenSigSuprvResp" BU_SG_REL_ EBCM_HS SG_ 452 FSpRgACCSwADd 1;
BA_REL_ "GenSigTimeoutTime" BU_SG_REL_ EBCM_HS SG_ 452 AutBrkAccActPsStRC 250;
BA_REL_ "GenSigTimeoutMsg" BU_SG_REL_ EBCM_HS SG_ 452 AutBrkAccActPsStRC 452;
BA_REL_ "GenSigSuprvResp" BU_SG_REL_ EBCM_HS SG_ 452 AutBrkAccActPsStRC 1;
BA_REL_ "GenSigTimeoutTime" BU_SG_REL_ EBCM_HS SG_ 452 AutBrkAccActPsStPVal 250;
BA_REL_ "GenSigTimeoutMsg" BU_SG_REL_ EBCM_HS SG_ 452 AutBrkAccActPsStPVal 452;
BA_REL_ "GenSigSuprvResp" BU_SG_REL_ EBCM_HS SG_ 452 AutBrkAccActPsStPVal 1;
BA_REL_ "GenSigTimeoutTime" BU_SG_REL_ EBCM_HS SG_ 452 ABAAPS_AccPos 250;
BA_REL_ "GenSigTimeoutMsg" BU_SG_REL_ EBCM_HS SG_ 452 ABAAPS_AccPos 452;
BA_REL_ "GenSigSuprvResp" BU_SG_REL_ EBCM_HS SG_ 452 ABAAPS_AccPos 1;
BA_REL_ "GenSigTimeoutTime" BU_SG_REL_ EBCM_HS SG_ 452 ABAAPS_AccPosV 250;
BA_REL_ "GenSigTimeoutMsg" BU_SG_REL_ EBCM_HS SG_ 452 ABAAPS_AccPosV 452;
BA_REL_ "GenSigSuprvResp" BU_SG_REL_ EBCM_HS SG_ 452 ABAAPS_AccPosV 1;
BA_REL_ "GenSigTimeoutTime" BU_SG_REL_ EBCM_HS SG_ 452 AccPdlOvrrdAtv 250;
BA_REL_ "GenSigTimeoutMsg" BU_SG_REL_ EBCM_HS SG_ 452 AccPdlOvrrdAtv 452;
BA_REL_ "GenSigSuprvResp" BU_SG_REL_ EBCM_HS SG_ 452 AccPdlOvrrdAtv 1;
BA_REL_ "GenSigTimeoutTime" BU_SG_REL_ BCM_HS SG_ 1280 TireRRLowTracIO 2500;
BA_REL_ "GenSigTimeoutMsg" BU_SG_REL_ BCM_HS SG_ 1280 TireRRLowTracIO 1280;
BA_REL_ "GenSigSuprvResp" BU_SG_REL_ BCM_HS SG_ 1280 TireRRLowTracIO 1;
BA_REL_ "GenSigTimeoutTime" BU_SG_REL_ BCM_HS SG_ 1280 TireRFLowTracIO 2500;
BA_REL_ "GenSigTimeoutMsg" BU_SG_REL_ BCM_HS SG_ 1280 TireRFLowTracIO 1280;
BA_REL_ "GenSigSuprvResp" BU_SG_REL_ BCM_HS SG_ 1280 TireRFLowTracIO 1;
BA_REL_ "GenSigTimeoutTime" BU_SG_REL_ BCM_HS SG_ 1280 TireLRLowTracIO 2500;
BA_REL_ "GenSigTimeoutMsg" BU_SG_REL_ BCM_HS SG_ 1280 TireLRLowTracIO 1280;
BA_REL_ "GenSigSuprvResp" BU_SG_REL_ BCM_HS SG_ 1280 TireLRLowTracIO 1;
BA_REL_ "GenSigTimeoutTime" BU_SG_REL_ BCM_HS SG_ 1280 TireLFLowTracIO 2500;
BA_REL_ "GenSigTimeoutMsg" BU_SG_REL_ BCM_HS SG_ 1280 TireLFLowTracIO 1280;
BA_REL_ "GenSigSuprvResp" BU_SG_REL_ BCM_HS SG_ 1280 TireLFLowTracIO 1;
BA_REL_ "GenSigTimeoutTime" BU_SG_REL_ EPS_HS SG_ 1280 WhlRotStatTmstmpRes 2500;
BA_REL_ "GenSigTimeoutMsg" BU_SG_REL_ EPS_HS SG_ 1280 WhlRotStatTmstmpRes 1280;
BA_REL_ "GenSigSuprvResp" BU_SG_REL_ EPS_HS SG_ 1280 WhlRotStatTmstmpRes 1;
BA_REL_ "GenSigTimeoutTime" BU_SG_REL_ RDCM_HS SG_ 1280 WhlRotStatTmstmpRes 2500;
BA_REL_ "GenSigTimeoutMsg" BU_SG_REL_ RDCM_HS SG_ 1280 WhlRotStatTmstmpRes 1280;
BA_REL_ "GenSigSuprvResp" BU_SG_REL_ RDCM_HS SG_ 1280 WhlRotStatTmstmpRes 1;
BA_REL_ "GenSigRxStartValue" BU_SG_REL_ RDCM_HS SG_ 1280 WhlPlsPerRevNonDrvn "48 pulses ($30)";
BA_REL_ "GenSigTimeoutTime" BU_SG_REL_ RDCM_HS SG_ 1280 WhlPlsPerRevDrvn 2500;
BA_REL_ "GenSigTimeoutMsg" BU_SG_REL_ RDCM_HS SG_ 1280 WhlPlsPerRevDrvn 1280;
BA_REL_ "GenSigRxStartValue" BU_SG_REL_ RDCM_HS SG_ 1280 WhlPlsPerRevDrvn "48 pulses ($30)";
BA_REL_ "GenSigSuprvResp" BU_SG_REL_ RDCM_HS SG_ 1280 WhlPlsPerRevDrvn 1;
BA_REL_ "GenSigTimeoutTime" BU_SG_REL_ ECM_HS SG_ 562 DrvlneMntsPerfMdRq 250;
BA_REL_ "GenSigTimeoutMsg" BU_SG_REL_ ECM_HS SG_ 562 DrvlneMntsPerfMdRq 562;
BA_REL_ "GenSigSuprvResp" BU_SG_REL_ ECM_HS SG_ 562 DrvlneMntsPerfMdRq 1;
BA_REL_ "GenSigTimeoutTime" BU_SG_REL_ EPS_HS SG_ 562 StgSysPerfMdRq 250;
BA_REL_ "GenSigTimeoutMsg" BU_SG_REL_ EPS_HS SG_ 562 StgSysPerfMdRq 562;
BA_REL_ "GenSigSuprvResp" BU_SG_REL_ EPS_HS SG_ 562 StgSysPerfMdRq 1;
BA_REL_ "GenSigTimeoutTime" BU_SG_REL_ RDCM_HS SG_ 562 AWDPerfMdRq 250;
BA_REL_ "GenSigTimeoutMsg" BU_SG_REL_ RDCM_HS SG_ 562 AWDPerfMdRq 562;
BA_REL_ "GenSigSuprvResp" BU_SG_REL_ RDCM_HS SG_ 562 AWDPerfMdRq 1;
BA_REL_ "GenSigTimeoutTime" BU_SG_REL_ BCM_HS SG_ 562 SndPerfMdCsStAvl 250;
BA_REL_ "GenSigTimeoutMsg" BU_SG_REL_ BCM_HS SG_ 562 SndPerfMdCsStAvl 562;
BA_REL_ "GenSigSuprvResp" BU_SG_REL_ BCM_HS SG_ 562 SndPerfMdCsStAvl 1;
BA_REL_ "GenSigTimeoutTime" BU_SG_REL_ BCM_HS SG_ 562 SndPerfMdCsCrStVal 250;
BA_REL_ "GenSigTimeoutMsg" BU_SG_REL_ BCM_HS SG_ 562 SndPerfMdCsCrStVal 562;
BA_REL_ "GenSigSuprvResp" BU_SG_REL_ BCM_HS SG_ 562 SndPerfMdCsCrStVal 1;
BA_REL_ "GenSigTimeoutTime" BU_SG_REL_ BCM_HS SG_ 562 DispPerfMdCsStAvl 250;
BA_REL_ "GenSigTimeoutMsg" BU_SG_REL_ BCM_HS SG_ 562 DispPerfMdCsStAvl 562;
BA_REL_ "GenSigSuprvResp" BU_SG_REL_ BCM_HS SG_ 562 DispPerfMdCsStAvl 1;
BA_REL_ "GenSigTimeoutTime" BU_SG_REL_ BCM_HS SG_ 562 DispPerfMdCsCrStVal 250;
BA_REL_ "GenSigTimeoutMsg" BU_SG_REL_ BCM_HS SG_ 562 DispPerfMdCsCrStVal 562;
BA_REL_ "GenSigSuprvResp" BU_SG_REL_ BCM_HS SG_ 562 DispPerfMdCsCrStVal 1;
BA_REL_ "GenSigTimeoutTime" BU_SG_REL_ BCM_HS SG_ 562 SndEnhcmtPerfMdRq 250;
BA_REL_ "GenSigTimeoutMsg" BU_SG_REL_ BCM_HS SG_ 562 SndEnhcmtPerfMdRq 562;
BA_REL_ "GenSigSuprvResp" BU_SG_REL_ BCM_HS SG_ 562 SndEnhcmtPerfMdRq 1;
BA_REL_ "GenSigTimeoutTime" BU_SG_REL_ BCM_HS SG_ 562 DsplyPerfMdRq 250;
BA_REL_ "GenSigTimeoutMsg" BU_SG_REL_ BCM_HS SG_ 562 DsplyPerfMdRq 562;
BA_REL_ "GenSigSuprvResp" BU_SG_REL_ BCM_HS SG_ 562 DsplyPerfMdRq 1;
BA_REL_ "GenSigTimeoutTime" BU_SG_REL_ BCM_HS SG_ 386 AHAct 250;
BA_REL_ "GenSigTimeoutMsg" BU_SG_REL_ BCM_HS SG_ 386 AHAct 386;
BA_REL_ "GenSigSuprvResp" BU_SG_REL_ BCM_HS SG_ 386 AHAct 1;
BA_REL_ "GenSigTimeoutTime" BU_SG_REL_ BCM_HS SG_ 386 AHEnbld 250;
BA_REL_ "GenSigTimeoutMsg" BU_SG_REL_ BCM_HS SG_ 386 AHEnbld 386;
BA_REL_ "GenSigSuprvResp" BU_SG_REL_ BCM_HS SG_ 386 AHEnbld 1;
BA_REL_ "GenSigTimeoutTime" BU_SG_REL_ BCM_HS SG_ 386 AHServcIO 250;
BA_REL_ "GenSigTimeoutMsg" BU_SG_REL_ BCM_HS SG_ 386 AHServcIO 386;
BA_REL_ "GenSigSuprvResp" BU_SG_REL_ BCM_HS SG_ 386 AHServcIO 1;
BA_REL_ "GenSigTimeoutTime" BU_SG_REL_ BCM_HS SG_ 386 AHAppBrkPedlIO 250;
BA_REL_ "GenSigTimeoutMsg" BU_SG_REL_ BCM_HS SG_ 386 AHAppBrkPedlIO 386;
BA_REL_ "GenSigSuprvResp" BU_SG_REL_ BCM_HS SG_ 386 AHAppBrkPedlIO 1;
BA_REL_ "GenSigTimeoutTime" BU_SG_REL_ BCM_HS SG_ 386 AHDisbldStbltIO 250;
BA_REL_ "GenSigTimeoutMsg" BU_SG_REL_ BCM_HS SG_ 386 AHDisbldStbltIO 386;
BA_REL_ "GenSigSuprvResp" BU_SG_REL_ BCM_HS SG_ 386 AHDisbldStbltIO 1;
BA_REL_ "GenSigTimeoutTime" BU_SG_REL_ BCM_HS SG_ 386 AHDisbldDrOpnIO 250;
BA_REL_ "GenSigTimeoutMsg" BU_SG_REL_ BCM_HS SG_ 386 AHDisbldDrOpnIO 386;
BA_REL_ "GenSigSuprvResp" BU_SG_REL_ BCM_HS SG_ 386 AHDisbldDrOpnIO 1;
BA_REL_ "GenSigTimeoutTime" BU_SG_REL_ BCM_HS SG_ 386 PMVSS_Disps 250;
BA_REL_ "GenSigTimeoutMsg" BU_SG_REL_ BCM_HS SG_ 386 PMVSS_Disps 386;
BA_REL_ "GenSigSuprvResp" BU_SG_REL_ BCM_HS SG_ 386 PMVSS_Disps 1;
BA_REL_ "GenSigTimeoutTime" BU_SG_REL_ BCM_HS SG_ 386 PMVSS_Exhst 250;
BA_REL_ "GenSigTimeoutMsg" BU_SG_REL_ BCM_HS SG_ 386 PMVSS_Exhst 386;
BA_REL_ "GenSigSuprvResp" BU_SG_REL_ BCM_HS SG_ 386 PMVSS_Exhst 1;
BA_REL_ "GenSigTimeoutTime" BU_SG_REL_ BCM_HS SG_ 386 PMVSS_PsngrSeat 250;
BA_REL_ "GenSigTimeoutMsg" BU_SG_REL_ BCM_HS SG_ 386 PMVSS_PsngrSeat 386;
BA_REL_ "GenSigSuprvResp" BU_SG_REL_ BCM_HS SG_ 386 PMVSS_PsngrSeat 1;
BA_REL_ "GenSigTimeoutTime" BU_SG_REL_ BCM_HS SG_ 386 PMVSS_DrvrSeat 250;
BA_REL_ "GenSigTimeoutMsg" BU_SG_REL_ BCM_HS SG_ 386 PMVSS_DrvrSeat 386;
BA_REL_ "GenSigSuprvResp" BU_SG_REL_ BCM_HS SG_ 386 PMVSS_DrvrSeat 1;
BA_REL_ "GenSigTimeoutTime" BU_SG_REL_ BCM_HS SG_ 386 PMVSS_AdptCrsCnt 250;
BA_REL_ "GenSigTimeoutMsg" BU_SG_REL_ BCM_HS SG_ 386 PMVSS_AdptCrsCnt 386;
BA_REL_ "GenSigSuprvResp" BU_SG_REL_ BCM_HS SG_ 386 PMVSS_AdptCrsCnt 1;
BA_REL_ "GenSigTimeoutTime" BU_SG_REL_ BCM_HS SG_ 386 PMVSS_Drvln 250;
BA_REL_ "GenSigTimeoutMsg" BU_SG_REL_ BCM_HS SG_ 386 PMVSS_Drvln 386;
BA_REL_ "GenSigSuprvResp" BU_SG_REL_ BCM_HS SG_ 386 PMVSS_Drvln 1;
BA_REL_ "GenSigTimeoutTime" BU_SG_REL_ BCM_HS SG_ 386 PMVSS_Susp 250;
BA_REL_ "GenSigTimeoutMsg" BU_SG_REL_ BCM_HS SG_ 386 PMVSS_Susp 386;
BA_REL_ "GenSigSuprvResp" BU_SG_REL_ BCM_HS SG_ 386 PMVSS_Susp 1;
BA_REL_ "GenSigTimeoutTime" BU_SG_REL_ BCM_HS SG_ 386 PMVSS_Strng 250;
BA_REL_ "GenSigTimeoutMsg" BU_SG_REL_ BCM_HS SG_ 386 PMVSS_Strng 386;
BA_REL_ "GenSigSuprvResp" BU_SG_REL_ BCM_HS SG_ 386 PMVSS_Strng 1;
BA_REL_ "GenSigTimeoutTime" BU_SG_REL_ BCM_HS SG_ 386 PMVSS_Trans 250;
BA_REL_ "GenSigTimeoutMsg" BU_SG_REL_ BCM_HS SG_ 386 PMVSS_Trans 386;
BA_REL_ "GenSigSuprvResp" BU_SG_REL_ BCM_HS SG_ 386 PMVSS_Trans 1;
BA_REL_ "GenSigTimeoutTime" BU_SG_REL_ BCM_HS SG_ 386 PMVSS_Eng 250;
BA_REL_ "GenSigTimeoutMsg" BU_SG_REL_ BCM_HS SG_ 386 PMVSS_Eng 386;
BA_REL_ "GenSigSuprvResp" BU_SG_REL_ BCM_HS SG_ 386 PMVSS_Eng 1;
BA_REL_ "GenSigTimeoutTime" BU_SG_REL_ BCM_HS SG_ 386 PMVSS_Snd 250;
BA_REL_ "GenSigTimeoutMsg" BU_SG_REL_ BCM_HS SG_ 386 PMVSS_Snd 386;
BA_REL_ "GenSigSuprvResp" BU_SG_REL_ BCM_HS SG_ 386 PMVSS_Snd 1;
BA_REL_ "GenSigTimeoutTime" BU_SG_REL_ BCM_HS SG_ 386 AWDRecmndIO 250;
BA_REL_ "GenSigTimeoutMsg" BU_SG_REL_ BCM_HS SG_ 386 AWDRecmndIO 386;
BA_REL_ "GenSigSuprvResp" BU_SG_REL_ BCM_HS SG_ 386 AWDRecmndIO 1;
BA_REL_ "GenSigTimeoutTime" BU_SG_REL_ CGM_HS SG_ 532 RedntVSEAct 250;
BA_REL_ "GenSigTimeoutMsg" BU_SG_REL_ CGM_HS SG_ 532 RedntVSEAct 532;
BA_REL_ "GenSigSuprvResp" BU_SG_REL_ CGM_HS SG_ 532 RedntVSEAct 1;
BA_REL_ "GenSigTimeoutTime" BU_SG_REL_ EPS_HS SG_ 532 RedntVSEAct 250;
BA_REL_ "GenSigTimeoutMsg" BU_SG_REL_ EPS_HS SG_ 532 RedntVSEAct 532;
BA_REL_ "GenSigSuprvResp" BU_SG_REL_ EPS_HS SG_ 532 RedntVSEAct 1;
BA_REL_ "GenSigTimeoutTime" BU_SG_REL_ CGM_HS SG_ 532 VehHldDrvrDsblActvFlg 250;
BA_REL_ "GenSigTimeoutMsg" BU_SG_REL_ CGM_HS SG_ 532 VehHldDrvrDsblActvFlg 532;
BA_REL_ "GenSigSuprvResp" BU_SG_REL_ CGM_HS SG_ 532 VehHldDrvrDsblActvFlg 1;
BA_REL_ "GenSigTimeoutTime" BU_SG_REL_ CGM_HS SG_ 532 AutoBrkngAvlbl 250;
BA_REL_ "GenSigTimeoutMsg" BU_SG_REL_ CGM_HS SG_ 532 AutoBrkngAvlbl 532;
BA_REL_ "GenSigSuprvResp" BU_SG_REL_ CGM_HS SG_ 532 AutoBrkngAvlbl 1;
BA_REL_ "GenSigTimeoutTime" BU_SG_REL_ EPS_HS SG_ 532 AutoBrkngAvlbl 250;
BA_REL_ "GenSigTimeoutMsg" BU_SG_REL_ EPS_HS SG_ 532 AutoBrkngAvlbl 532;
BA_REL_ "GenSigSuprvResp" BU_SG_REL_ EPS_HS SG_ 532 AutoBrkngAvlbl 1;
BA_REL_ "GenSigTimeoutTime" BU_SG_REL_ ECM_HS SG_ 532 AutoBrkngAvlbl 250;
BA_REL_ "GenSigTimeoutMsg" BU_SG_REL_ ECM_HS SG_ 532 AutoBrkngAvlbl 532;
BA_REL_ "GenSigSuprvResp" BU_SG_REL_ ECM_HS SG_ 532 AutoBrkngAvlbl 1;
BA_REL_ "GenSigTimeoutTime" BU_SG_REL_ CGM_HS SG_ 532 ABSAutnmsBrkReq 250;
BA_REL_ "GenSigTimeoutMsg" BU_SG_REL_ CGM_HS SG_ 532 ABSAutnmsBrkReq 532;
BA_REL_ "GenSigSuprvResp" BU_SG_REL_ CGM_HS SG_ 532 ABSAutnmsBrkReq 1;
BA_REL_ "GenSigTimeoutTime" BU_SG_REL_ CGM_HS SG_ 532 ABSActvProt 250;
BA_REL_ "GenSigTimeoutMsg" BU_SG_REL_ CGM_HS SG_ 532 ABSActvProt 532;
BA_REL_ "GenSigSuprvResp" BU_SG_REL_ CGM_HS SG_ 532 ABSActvProt 1;
BA_REL_ "GenSigTimeoutTime" BU_SG_REL_ EPS_HS SG_ 532 ABSActvProt 250;
BA_REL_ "GenSigTimeoutMsg" BU_SG_REL_ EPS_HS SG_ 532 ABSActvProt 532;
BA_REL_ "GenSigSuprvResp" BU_SG_REL_ EPS_HS SG_ 532 ABSActvProt 1;
BA_REL_ "GenSigTimeoutTime" BU_SG_REL_ CGM_HS SG_ 532 AutoBrkngAct 250;
BA_REL_ "GenSigTimeoutMsg" BU_SG_REL_ CGM_HS SG_ 532 AutoBrkngAct 532;
BA_REL_ "GenSigSuprvResp" BU_SG_REL_ CGM_HS SG_ 532 AutoBrkngAct 1;
BA_REL_ "GenSigTimeoutTime" BU_SG_REL_ CGM_HS SG_ 532 HilRlbkCtrlActIO 250;
BA_REL_ "GenSigTimeoutMsg" BU_SG_REL_ CGM_HS SG_ 532 HilRlbkCtrlActIO 532;
BA_REL_ "GenSigSuprvResp" BU_SG_REL_ CGM_HS SG_ 532 HilRlbkCtrlActIO 1;
BA_REL_ "GenSigTimeoutTime" BU_SG_REL_ BCM_HS SG_ 532 HilRlbkCtrlActIO 250;
BA_REL_ "GenSigTimeoutMsg" BU_SG_REL_ BCM_HS SG_ 532 HilRlbkCtrlActIO 532;
BA_REL_ "GenSigSuprvResp" BU_SG_REL_ BCM_HS SG_ 532 HilRlbkCtrlActIO 1;
BA_REL_ "GenSigTimeoutTime" BU_SG_REL_ CGM_HS SG_ 532 HlStrAssActIO 250;
BA_REL_ "GenSigTimeoutMsg" BU_SG_REL_ CGM_HS SG_ 532 HlStrAssActIO 532;
BA_REL_ "GenSigSuprvResp" BU_SG_REL_ CGM_HS SG_ 532 HlStrAssActIO 1;
BA_REL_ "GenSigTimeoutTime" BU_SG_REL_ CGM_HS SG_ 532 BrkSysAutBrkFld 250;
BA_REL_ "GenSigTimeoutMsg" BU_SG_REL_ CGM_HS SG_ 532 BrkSysAutBrkFld 532;
BA_REL_ "GenSigSuprvResp" BU_SG_REL_ CGM_HS SG_ 532 BrkSysAutBrkFld 1;
BA_REL_ "GenSigTimeoutTime" BU_SG_REL_ ECM_HS SG_ 532 BrkSysAutBrkFld 250;
BA_REL_ "GenSigTimeoutMsg" BU_SG_REL_ ECM_HS SG_ 532 BrkSysAutBrkFld 532;
BA_REL_ "GenSigSuprvResp" BU_SG_REL_ ECM_HS SG_ 532 BrkSysAutBrkFld 1;
BA_REL_ "GenSigTimeoutTime" BU_SG_REL_ CGM_HS SG_ 532 IntBrkAssPreFilReq 250;
BA_REL_ "GenSigTimeoutMsg" BU_SG_REL_ CGM_HS SG_ 532 IntBrkAssPreFilReq 532;
BA_REL_ "GenSigSuprvResp" BU_SG_REL_ CGM_HS SG_ 532 IntBrkAssPreFilReq 1;
BA_REL_ "GenSigTimeoutTime" BU_SG_REL_ CGM_HS SG_ 532 BrkSysMalFuncIndOn 250;
BA_REL_ "GenSigTimeoutMsg" BU_SG_REL_ CGM_HS SG_ 532 BrkSysMalFuncIndOn 532;
BA_REL_ "GenSigSuprvResp" BU_SG_REL_ CGM_HS SG_ 532 BrkSysMalFuncIndOn 1;
BA_REL_ "GenSigTimeoutTime" BU_SG_REL_ BCM_HS SG_ 532 BrkSysMalFuncIndOn 250;
BA_REL_ "GenSigTimeoutMsg" BU_SG_REL_ BCM_HS SG_ 532 BrkSysMalFuncIndOn 532;
BA_REL_ "GenSigSuprvResp" BU_SG_REL_ BCM_HS SG_ 532 BrkSysMalFuncIndOn 1;
BA_REL_ "GenSigTimeoutTime" BU_SG_REL_ CGM_HS SG_ 532 BPDAPS_BkPDrvApPV 250;
BA_REL_ "GenSigTimeoutMsg" BU_SG_REL_ CGM_HS SG_ 532 BPDAPS_BkPDrvApPV 532;
BA_REL_ "GenSigSuprvResp" BU_SG_REL_ CGM_HS SG_ 532 BPDAPS_BkPDrvApPV 1;
BA_REL_ "GenSigTimeoutTime" BU_SG_REL_ CGM_HS SG_ 532 BPDAPS_BkPDrvApP 250;
BA_REL_ "GenSigTimeoutMsg" BU_SG_REL_ CGM_HS SG_ 532 BPDAPS_BkPDrvApP 532;
BA_REL_ "GenSigSuprvResp" BU_SG_REL_ CGM_HS SG_ 532 BPDAPS_BkPDrvApP 1;
BA_REL_ "GenSigTimeoutTime" BU_SG_REL_ CGM_HS SG_ 532 BrkFldLvlLw 250;
BA_REL_ "GenSigTimeoutMsg" BU_SG_REL_ CGM_HS SG_ 532 BrkFldLvlLw 532;
BA_REL_ "GenSigSuprvResp" BU_SG_REL_ CGM_HS SG_ 532 BrkFldLvlLw 1;
BA_REL_ "GenSigTimeoutTime" BU_SG_REL_ BCM_HS SG_ 532 BrkFldLvlLw 250;
BA_REL_ "GenSigTimeoutMsg" BU_SG_REL_ BCM_HS SG_ 532 BrkFldLvlLw 532;
BA_REL_ "GenSigVBitResp" BU_SG_REL_ BCM_HS SG_ 532 BrkFldLvlLw 1;
BA_REL_ "GenSigSuprvResp" BU_SG_REL_ BCM_HS SG_ 532 BrkFldLvlLw 1;
BA_REL_ "GenSigTimeoutTime" BU_SG_REL_ BCM_HS SG_ 328 StrAsstRdcdLvl3IO 2500;
BA_REL_ "GenSigTimeoutMsg" BU_SG_REL_ BCM_HS SG_ 328 StrAsstRdcdLvl3IO 328;
BA_REL_ "GenSigSuprvResp" BU_SG_REL_ BCM_HS SG_ 328 StrAsstRdcdLvl3IO 1;
BA_REL_ "GenSigTimeoutTime" BU_SG_REL_ BCM_HS SG_ 328 StrAsstRdcdLvl2IO 2500;
BA_REL_ "GenSigTimeoutMsg" BU_SG_REL_ BCM_HS SG_ 328 StrAsstRdcdLvl2IO 328;
BA_REL_ "GenSigSuprvResp" BU_SG_REL_ BCM_HS SG_ 328 StrAsstRdcdLvl2IO 1;
BA_REL_ "GenSigTimeoutTime" BU_SG_REL_ BCM_HS SG_ 328 StrngAsstRdcdIO 2500;
BA_REL_ "GenSigTimeoutMsg" BU_SG_REL_ BCM_HS SG_ 328 StrngAsstRdcdIO 328;
BA_REL_ "GenSigSuprvResp" BU_SG_REL_ BCM_HS SG_ 328 StrngAsstRdcdIO 1;
BA_REL_ "GenSigTimeoutTime" BU_SG_REL_ BCM_HS SG_ 328 PwrStrIO 2500;
BA_REL_ "GenSigTimeoutMsg" BU_SG_REL_ BCM_HS SG_ 328 PwrStrIO 328;
BA_REL_ "GenSigSuprvResp" BU_SG_REL_ BCM_HS SG_ 328 PwrStrIO 1;
BA_REL_ "GenSigTimeoutTime" BU_SG_REL_ BCM_HS SG_ 560 AllNodesVNA 250;
BA_REL_ "GenSigTimeoutMsg" BU_SG_REL_ BCM_HS SG_ 560 AllNodesVNA 560;
BA_REL_ "GenSigSuprvResp" BU_SG_REL_ BCM_HS SG_ 560 AllNodesVNA 1;
BA_REL_ "GenSigTimeoutTime" BU_SG_REL_ BCM_HS SG_ 560 StpOnBrkToRelPBIndOn 250;
BA_REL_ "GenSigTimeoutMsg" BU_SG_REL_ BCM_HS SG_ 560 StpOnBrkToRelPBIndOn 560;
BA_REL_ "GenSigSuprvResp" BU_SG_REL_ BCM_HS SG_ 560 StpOnBrkToRelPBIndOn 1;
BA_REL_ "GenSigTimeoutTime" BU_SG_REL_ BCM_HS SG_ 560 EPBSysDspMsgReq 250;
BA_REL_ "GenSigTimeoutMsg" BU_SG_REL_ BCM_HS SG_ 560 EPBSysDspMsgReq 560;
BA_REL_ "GenSigSuprvResp" BU_SG_REL_ BCM_HS SG_ 560 EPBSysDspMsgReq 1;
BA_REL_ "GenSigTimeoutTime" BU_SG_REL_ BCM_HS SG_ 560 EPBSysAudWarnReq 250;
BA_REL_ "GenSigTimeoutMsg" BU_SG_REL_ BCM_HS SG_ 560 EPBSysAudWarnReq 560;
BA_REL_ "GenSigSuprvResp" BU_SG_REL_ BCM_HS SG_ 560 EPBSysAudWarnReq 1;
BA_REL_ "GenSigTimeoutTime" BU_SG_REL_ RDCM_HS SG_ 560 ElecPrkBrkStat 250;
BA_REL_ "GenSigTimeoutMsg" BU_SG_REL_ RDCM_HS SG_ 560 ElecPrkBrkStat 560;
BA_REL_ "GenSigSuprvResp" BU_SG_REL_ RDCM_HS SG_ 560 ElecPrkBrkStat 1;
BA_REL_ "GenSigTimeoutTime" BU_SG_REL_ BCM_HS SG_ 560 ElecPrkBrkStat 250;
BA_REL_ "GenSigTimeoutMsg" BU_SG_REL_ BCM_HS SG_ 560 ElecPrkBrkStat 560;
BA_REL_ "GenSigSuprvResp" BU_SG_REL_ BCM_HS SG_ 560 ElecPrkBrkStat 1;
BA_REL_ "GenSigTimeoutTime" BU_SG_REL_ BCM_HS SG_ 560 EPBSysBrkLtsReq 250;
BA_REL_ "GenSigTimeoutMsg" BU_SG_REL_ BCM_HS SG_ 560 EPBSysBrkLtsReq 560;
BA_REL_ "GenSigSuprvResp" BU_SG_REL_ BCM_HS SG_ 560 EPBSysBrkLtsReq 1;
BA_REL_ "GenSigTimeoutTime" BU_SG_REL_ EBCM_HS SG_ 451 HillDscntCtrlSwStatPVal 250;
BA_REL_ "GenSigTimeoutMsg" BU_SG_REL_ EBCM_HS SG_ 451 HillDscntCtrlSwStatPVal 451;
BA_REL_ "GenSigSuprvResp" BU_SG_REL_ EBCM_HS SG_ 451 HillDscntCtrlSwStatPVal 1;
BA_REL_ "GenSigTimeoutTime" BU_SG_REL_ EBCM_HS SG_ 451 HillDscntCtrlSwStatARC 250;
BA_REL_ "GenSigTimeoutMsg" BU_SG_REL_ EBCM_HS SG_ 451 HillDscntCtrlSwStatARC 451;
BA_REL_ "GenSigSuprvResp" BU_SG_REL_ EBCM_HS SG_ 451 HillDscntCtrlSwStatARC 1;
BA_REL_ "GenSigTimeoutTime" BU_SG_REL_ EBCM_HS SG_ 451 HillDscntCtrlSwStat 250;
BA_REL_ "GenSigTimeoutMsg" BU_SG_REL_ EBCM_HS SG_ 451 HillDscntCtrlSwStat 451;
BA_REL_ "GenSigSuprvResp" BU_SG_REL_ EBCM_HS SG_ 451 HillDscntCtrlSwStat 1;
BA_REL_ "GenSigTimeoutTime" BU_SG_REL_ EBCM_HS SG_ 451 EngTrqRdFlrSt 250;
BA_REL_ "GenSigTimeoutMsg" BU_SG_REL_ EBCM_HS SG_ 451 EngTrqRdFlrSt 451;
BA_REL_ "GenSigSuprvResp" BU_SG_REL_ EBCM_HS SG_ 451 EngTrqRdFlrSt 1;
BA_REL_ "GenSigTimeoutTime" BU_SG_REL_ RDCM_HS SG_ 451 AccPos 250;
BA_REL_ "GenSigTimeoutMsg" BU_SG_REL_ RDCM_HS SG_ 451 AccPos 451;
BA_REL_ "GenSigSuprvResp" BU_SG_REL_ RDCM_HS SG_ 451 AccPos 1;
BA_REL_ "GenSigTimeoutTime" BU_SG_REL_ EBCM_HS SG_ 451 AccPos 250;
BA_REL_ "GenSigTimeoutMsg" BU_SG_REL_ EBCM_HS SG_ 451 AccPos 451;
BA_REL_ "GenSigSuprvResp" BU_SG_REL_ EBCM_HS SG_ 451 AccPos 1;
BA_REL_ "GenSigTimeoutTime" BU_SG_REL_ BSM_HS SG_ 451 AccPos 500;
BA_REL_ "GenSigTimeoutMsg" BU_SG_REL_ BSM_HS SG_ 451 AccPos 451;
BA_REL_ "GenSigSuprvResp" BU_SG_REL_ BSM_HS SG_ 451 AccPos 1;
BA_REL_ "GenSigTimeoutTime" BU_SG_REL_ BCM_HS SG_ 451 GlwPlgCrnkDelAct 250;
BA_REL_ "GenSigTimeoutMsg" BU_SG_REL_ BCM_HS SG_ 451 GlwPlgCrnkDelAct 451;
BA_REL_ "GenSigSuprvResp" BU_SG_REL_ BCM_HS SG_ 451 GlwPlgCrnkDelAct 1;
BA_REL_ "GenSigTimeoutTime" BU_SG_REL_ EBCM_HS SG_ 451 EngTrqDrRqdExtRng 250;
BA_REL_ "GenSigTimeoutMsg" BU_SG_REL_ EBCM_HS SG_ 451 EngTrqDrRqdExtRng 451;
BA_REL_ "GenSigSuprvResp" BU_SG_REL_ EBCM_HS SG_ 451 EngTrqDrRqdExtRng 1;
BA_REL_ "GenSigTimeoutTime" BU_SG_REL_ BCM_HS SG_ 451 EngTrqDrRqdExtRng 250;
BA_REL_ "GenSigTimeoutMsg" BU_SG_REL_ BCM_HS SG_ 451 EngTrqDrRqdExtRng 451;
BA_REL_ "GenSigSuprvResp" BU_SG_REL_ BCM_HS SG_ 451 EngTrqDrRqdExtRng 1;
BA_REL_ "GenSigTimeoutTime" BU_SG_REL_ RDCM_HS SG_ 451 EngTrqActExtRng 250;
BA_REL_ "GenSigTimeoutMsg" BU_SG_REL_ RDCM_HS SG_ 451 EngTrqActExtRng 451;
BA_REL_ "GenSigRxStartValue" BU_SG_REL_ RDCM_HS SG_ 451 EngTrqActExtRng "$6A0 (0 converted)";
BA_REL_ "GenSigSuprvResp" BU_SG_REL_ RDCM_HS SG_ 451 EngTrqActExtRng 1;
BA_REL_ "GenSigTimeoutTime" BU_SG_REL_ EBCM_HS SG_ 451 EngTrqActExtRng 250;
BA_REL_ "GenSigTimeoutMsg" BU_SG_REL_ EBCM_HS SG_ 451 EngTrqActExtRng 451;
BA_REL_ "GenSigSuprvResp" BU_SG_REL_ EBCM_HS SG_ 451 EngTrqActExtRng 1;
BA_REL_ "GenSigTimeoutTime" BU_SG_REL_ BCM_HS SG_ 451 EngTrqActExtRng 250;
BA_REL_ "GenSigTimeoutMsg" BU_SG_REL_ BCM_HS SG_ 451 EngTrqActExtRng 451;
BA_REL_ "GenSigVBitResp" BU_SG_REL_ BCM_HS SG_ 451 EngTrqActExtRng 1;
BA_REL_ "GenSigSuprvResp" BU_SG_REL_ BCM_HS SG_ 451 EngTrqActExtRng 1;
BA_REL_ "GenSigTimeoutTime" BU_SG_REL_ EBCM_HS SG_ 1282 TireTrdTmpStat 1250;
BA_REL_ "GenSigTimeoutMsg" BU_SG_REL_ EBCM_HS SG_ 1282 TireTrdTmpStat 1282;
BA_REL_ "GenSigSuprvResp" BU_SG_REL_ EBCM_HS SG_ 1282 TireTrdTmpStat 1;
BA_REL_ "GenSigTimeoutTime" BU_SG_REL_ BCM_HS SG_ 880 ACCSysSltdMdDispIO 250;
BA_REL_ "GenSigTimeoutMsg" BU_SG_REL_ BCM_HS SG_ 880 ACCSysSltdMdDispIO 880;
BA_REL_ "GenSigSuprvResp" BU_SG_REL_ BCM_HS SG_ 880 ACCSysSltdMdDispIO 1;
BA_REL_ "GenSigTimeoutTime" BU_SG_REL_ BCM_HS SG_ 880 ACCSysSltdMd 250;
BA_REL_ "GenSigTimeoutMsg" BU_SG_REL_ BCM_HS SG_ 880 ACCSysSltdMd 880;
BA_REL_ "GenSigSuprvResp" BU_SG_REL_ BCM_HS SG_ 880 ACCSysSltdMd 1;
BA_REL_ "GenSigTimeoutTime" BU_SG_REL_ BCM_HS SG_ 880 FOAI_VehAhdIndRq 250;
BA_REL_ "GenSigSuprvResp" BU_SG_REL_ BCM_HS SG_ 880 FOAI_VehAhdIndRq 1;
BA_REL_ "GenSigTimeoutTime" BU_SG_REL_ BCM_HS SG_ 880 FOAI_AlrtWrnIndRq 250;
BA_REL_ "GenSigSuprvResp" BU_SG_REL_ BCM_HS SG_ 880 FOAI_AlrtWrnIndRq 1;
BA_REL_ "GenSigTimeoutTime" BU_SG_REL_ BCM_HS SG_ 880 FOAI_AlrtChmIhbRq 250;
BA_REL_ "GenSigSuprvResp" BU_SG_REL_ BCM_HS SG_ 880 FOAI_AlrtChmIhbRq 1;
BA_REL_ "GenSigTimeoutTime" BU_SG_REL_ BCM_HS SG_ 880 FwdClnAlrtPr 250;
BA_REL_ "GenSigSuprvResp" BU_SG_REL_ BCM_HS SG_ 880 FwdClnAlrtPr 1;
BA_REL_ "GenSigTimeoutTime" BU_SG_REL_ BCM_HS SG_ 880 ACCUnavlbleDTWthrIO 250;
BA_REL_ "GenSigSuprvResp" BU_SG_REL_ BCM_HS SG_ 880 ACCUnavlbleDTWthrIO 1;
BA_REL_ "GenSigTimeoutTime" BU_SG_REL_ TCM_HS SG_ 880 ACCAct370 250;
BA_REL_ "GenSigTimeoutMsg" BU_SG_REL_ TCM_HS SG_ 880 ACCAct370 880;
BA_REL_ "GenSigSuprvResp" BU_SG_REL_ TCM_HS SG_ 880 ACCAct370 1;
BA_REL_ "GenSigTimeoutTime" BU_SG_REL_ EBCM_HS SG_ 880 ACCAct370 500;
BA_REL_ "GenSigTimeoutMsg" BU_SG_REL_ EBCM_HS SG_ 880 ACCAct370 880;
BA_REL_ "GenSigSuprvResp" BU_SG_REL_ EBCM_HS SG_ 880 ACCAct370 1;
BA_REL_ "GenSigTimeoutTime" BU_SG_REL_ BCM_HS SG_ 880 ACCAct370 250;
BA_REL_ "GenSigTimeoutMsg" BU_SG_REL_ BCM_HS SG_ 880 ACCAct370 880;
BA_REL_ "GenSigSuprvResp" BU_SG_REL_ BCM_HS SG_ 880 ACCAct370 1;
BA_REL_ "GenSigTimeoutTime" BU_SG_REL_ BCM_HS SG_ 880 DrvThrtlOvrdIO 250;
BA_REL_ "GenSigTimeoutMsg" BU_SG_REL_ BCM_HS SG_ 880 DrvThrtlOvrdIO 880;
BA_REL_ "GenSigSuprvResp" BU_SG_REL_ BCM_HS SG_ 880 DrvThrtlOvrdIO 1;
BA_REL_ "GenSigTimeoutTime" BU_SG_REL_ BCM_HS SG_ 880 ServAdpCrsCtrlIndOn 250;
BA_REL_ "GenSigTimeoutMsg" BU_SG_REL_ BCM_HS SG_ 880 ServAdpCrsCtrlIndOn 880;
BA_REL_ "GenSigSuprvResp" BU_SG_REL_ BCM_HS SG_ 880 ServAdpCrsCtrlIndOn 1;
BA_REL_ "GenSigTimeoutTime" BU_SG_REL_ ECM_HS SG_ 880 ACCDrvrSeltdSpd 250;
BA_REL_ "GenSigTimeoutMsg" BU_SG_REL_ ECM_HS SG_ 880 ACCDrvrSeltdSpd 880;
BA_REL_ "GenSigSuprvResp" BU_SG_REL_ ECM_HS SG_ 880 ACCDrvrSeltdSpd 1;
BA_REL_ "GenSigTimeoutTime" BU_SG_REL_ BCM_HS SG_ 880 ACCDrvrSeltdSpd 250;
BA_REL_ "GenSigSuprvResp" BU_SG_REL_ BCM_HS SG_ 880 ACCDrvrSeltdSpd 1;
BA_REL_ "GenSigTimeoutTime" BU_SG_REL_ BCM_HS SG_ 880 ACCHdwayStngIO 250;
BA_REL_ "GenSigTimeoutMsg" BU_SG_REL_ BCM_HS SG_ 880 ACCHdwayStngIO 880;
BA_REL_ "GenSigSuprvResp" BU_SG_REL_ BCM_HS SG_ 880 ACCHdwayStngIO 1;
BA_REL_ "GenSigTimeoutTime" BU_SG_REL_ BCM_HS SG_ 880 ACCHdwyStg 250;
BA_REL_ "GenSigSuprvResp" BU_SG_REL_ BCM_HS SG_ 880 ACCHdwyStg 1;
BA_REL_ "GenSigTimeoutTime" BU_SG_REL_ BCM_HS SG_ 880 ACCSnsClnRqdIO 250;
BA_REL_ "GenSigTimeoutMsg" BU_SG_REL_ BCM_HS SG_ 880 ACCSnsClnRqdIO 880;
BA_REL_ "GenSigSuprvResp" BU_SG_REL_ BCM_HS SG_ 880 ACCSnsClnRqdIO 1;
BA_REL_ "GenSigTimeoutTime" BU_SG_REL_ BCM_HS SG_ 880 ACCTmpUnavlbleIO 250;
BA_REL_ "GenSigTimeoutMsg" BU_SG_REL_ BCM_HS SG_ 880 ACCTmpUnavlbleIO 880;
BA_REL_ "GenSigSuprvResp" BU_SG_REL_ BCM_HS SG_ 880 ACCTmpUnavlbleIO 1;
BA_REL_ "GenSigTimeoutTime" BU_SG_REL_ BCM_HS SG_ 880 ACCDrvrSeltdSpdIO 250;
BA_REL_ "GenSigTimeoutMsg" BU_SG_REL_ BCM_HS SG_ 880 ACCDrvrSeltdSpdIO 880;
BA_REL_ "GenSigSuprvResp" BU_SG_REL_ BCM_HS SG_ 880 ACCDrvrSeltdSpdIO 1;
BA_REL_ "GenSigTimeoutTime" BU_SG_REL_ CGM_HS SG_ 485 StrWhlAngSenTyp 250;
BA_REL_ "GenSigTimeoutMsg" BU_SG_REL_ CGM_HS SG_ 485 StrWhlAngSenTyp 485;
BA_REL_ "GenSigSuprvResp" BU_SG_REL_ CGM_HS SG_ 485 StrWhlAngSenTyp 1;
BA_REL_ "GenSigTimeoutTime" BU_SG_REL_ EBCM_HS SG_ 485 StrWhlAngSenTyp 100;
BA_REL_ "GenSigTimeoutMsg" BU_SG_REL_ EBCM_HS SG_ 485 StrWhlAngSenTyp 485;
BA_REL_ "GenSigSuprvResp" BU_SG_REL_ EBCM_HS SG_ 485 StrWhlAngSenTyp 1;
BA_REL_ "GenSigTimeoutTime" BU_SG_REL_ CGM_HS SG_ 485 StrWhAngGrd 250;
BA_REL_ "GenSigTimeoutMsg" BU_SG_REL_ CGM_HS SG_ 485 StrWhAngGrd 485;
BA_REL_ "GenSigSuprvResp" BU_SG_REL_ CGM_HS SG_ 485 StrWhAngGrd 1;
BA_REL_ "GenSigTimeoutTime" BU_SG_REL_ TCM_HS SG_ 485 StrWhAngGrd 250;
BA_REL_ "GenSigTimeoutMsg" BU_SG_REL_ TCM_HS SG_ 485 StrWhAngGrd 485;
BA_REL_ "GenSigSuprvResp" BU_SG_REL_ TCM_HS SG_ 485 StrWhAngGrd 1;
BA_REL_ "GenSigTimeoutTime" BU_SG_REL_ EBCM_HS SG_ 485 StrWhAngGrd 100;
BA_REL_ "GenSigTimeoutMsg" BU_SG_REL_ EBCM_HS SG_ 485 StrWhAngGrd 485;
BA_REL_ "GenSigSuprvResp" BU_SG_REL_ EBCM_HS SG_ 485 StrWhAngGrd 1;
BA_REL_ "GenSigTimeoutTime" BU_SG_REL_ CGM_HS SG_ 485 StrWhlAngSenCalStat 250;
BA_REL_ "GenSigTimeoutMsg" BU_SG_REL_ CGM_HS SG_ 485 StrWhlAngSenCalStat 485;
BA_REL_ "GenSigSuprvResp" BU_SG_REL_ CGM_HS SG_ 485 StrWhlAngSenCalStat 1;
BA_REL_ "GenSigTimeoutTime" BU_SG_REL_ TCM_HS SG_ 485 StrWhlAngSenCalStat 250;
BA_REL_ "GenSigTimeoutMsg" BU_SG_REL_ TCM_HS SG_ 485 StrWhlAngSenCalStat 485;
BA_REL_ "GenSigSuprvResp" BU_SG_REL_ TCM_HS SG_ 485 StrWhlAngSenCalStat 1;
BA_REL_ "GenSigRxStartValue" BU_SG_REL_ RDCM_HS SG_ 485 StrWhlAngSenCalStat "$2 - Calibrated";
BA_REL_ "GenSigTimeoutTime" BU_SG_REL_ ECM_HS SG_ 485 StrWhlAngSenCalStat 250;
BA_REL_ "GenSigTimeoutMsg" BU_SG_REL_ ECM_HS SG_ 485 StrWhlAngSenCalStat 485;
BA_REL_ "GenSigSuprvResp" BU_SG_REL_ ECM_HS SG_ 485 StrWhlAngSenCalStat 1;
BA_REL_ "GenSigTimeoutTime" BU_SG_REL_ EBCM_HS SG_ 485 StrWhlAngSenCalStat 100;
BA_REL_ "GenSigTimeoutMsg" BU_SG_REL_ EBCM_HS SG_ 485 StrWhlAngSenCalStat 485;
BA_REL_ "GenSigSuprvResp" BU_SG_REL_ EBCM_HS SG_ 485 StrWhlAngSenCalStat 1;
BA_REL_ "GenSigTimeoutTime" BU_SG_REL_ CGM_HS SG_ 485 StrWhAng 250;
BA_REL_ "GenSigTimeoutMsg" BU_SG_REL_ CGM_HS SG_ 485 StrWhAng 485;
BA_REL_ "GenSigSuprvResp" BU_SG_REL_ CGM_HS SG_ 485 StrWhAng 1;
BA_REL_ "GenSigTimeoutTime" BU_SG_REL_ TCM_HS SG_ 485 StrWhAng 250;
BA_REL_ "GenSigTimeoutMsg" BU_SG_REL_ TCM_HS SG_ 485 StrWhAng 485;
BA_REL_ "GenSigSuprvResp" BU_SG_REL_ TCM_HS SG_ 485 StrWhAng 1;
BA_REL_ "GenSigTimeoutTime" BU_SG_REL_ RDCM_HS SG_ 485 StrWhAng 250;
BA_REL_ "GenSigTimeoutMsg" BU_SG_REL_ RDCM_HS SG_ 485 StrWhAng 485;
BA_REL_ "GenSigVBitResp" BU_SG_REL_ RDCM_HS SG_ 485 StrWhAng 1;
BA_REL_ "GenSigVDAFailComment" BU_SG_REL_ RDCM_HS SG_ 485 StrWhAng "Steering Wheel Angle Virtual Device Availability";
BA_REL_ "GenSigVDAFailResp" BU_SG_REL_ RDCM_HS SG_ 485 StrWhAng 1;
BA_REL_ "GenSigSuprvResp" BU_SG_REL_ RDCM_HS SG_ 485 StrWhAng 1;
BA_REL_ "GenSigTimeoutTime" BU_SG_REL_ EPS_HS SG_ 485 StrWhAng 250;
BA_REL_ "GenSigTimeoutMsg" BU_SG_REL_ EPS_HS SG_ 485 StrWhAng 485;
BA_REL_ "GenSigSuprvResp" BU_SG_REL_ EPS_HS SG_ 485 StrWhAng 1;
BA_REL_ "GenSigTimeoutTime" BU_SG_REL_ ECM_HS SG_ 485 StrWhAng 250;
BA_REL_ "GenSigTimeoutMsg" BU_SG_REL_ ECM_HS SG_ 485 StrWhAng 485;
BA_REL_ "GenSigSuprvResp" BU_SG_REL_ ECM_HS SG_ 485 StrWhAng 1;
BA_REL_ "GenSigTimeoutTime" BU_SG_REL_ EBCM_HS SG_ 485 StrWhAng 100;
BA_REL_ "GenSigTimeoutMsg" BU_SG_REL_ EBCM_HS SG_ 485 StrWhAng 485;
BA_REL_ "GenSigSuprvResp" BU_SG_REL_ EBCM_HS SG_ 485 StrWhAng 1;
BA_REL_ "GenSigTimeoutTime" BU_SG_REL_ BCM_HS SG_ 485 StrWhAng 250;
BA_REL_ "GenSigTimeoutMsg" BU_SG_REL_ BCM_HS SG_ 485 StrWhAng 485;
BA_REL_ "GenSigVBitResp" BU_SG_REL_ BCM_HS SG_ 485 StrWhAng 1;
BA_REL_ "GenSigSuprvResp" BU_SG_REL_ BCM_HS SG_ 485 StrWhAng 1;
BA_REL_ "GenSigTimeoutTime" BU_SG_REL_ CGM_HS SG_ 1001 DistRollCntAvgDrvnSrc 250;
BA_REL_ "GenSigTimeoutMsg" BU_SG_REL_ CGM_HS SG_ 1001 DistRollCntAvgDrvnSrc 1001;
BA_REL_ "GenSigSuprvResp" BU_SG_REL_ CGM_HS SG_ 1001 DistRollCntAvgDrvnSrc 1;
BA_REL_ "GenSigTimeoutTime" BU_SG_REL_ EBCM_HS SG_ 1001 DistRollCntAvgDrvnSrc 1000;
BA_REL_ "GenSigTimeoutMsg" BU_SG_REL_ EBCM_HS SG_ 1001 DistRollCntAvgDrvnSrc 1001;
BA_REL_ "GenSigSuprvResp" BU_SG_REL_ EBCM_HS SG_ 1001 DistRollCntAvgDrvnSrc 1;
BA_REL_ "GenSigTimeoutTime" BU_SG_REL_ CGM_HS SG_ 1001 VehSpdAvgDrvnSrc 250;
BA_REL_ "GenSigTimeoutMsg" BU_SG_REL_ CGM_HS SG_ 1001 VehSpdAvgDrvnSrc 1001;
BA_REL_ "GenSigSuprvResp" BU_SG_REL_ CGM_HS SG_ 1001 VehSpdAvgDrvnSrc 1;
BA_REL_ "GenSigTimeoutTime" BU_SG_REL_ EBCM_HS SG_ 1001 VehSpdAvgDrvnSrc 1000;
BA_REL_ "GenSigTimeoutMsg" BU_SG_REL_ EBCM_HS SG_ 1001 VehSpdAvgDrvnSrc 1001;
BA_REL_ "GenSigSuprvResp" BU_SG_REL_ EBCM_HS SG_ 1001 VehSpdAvgDrvnSrc 1;
BA_REL_ "GenSigTimeoutTime" BU_SG_REL_ CGM_HS SG_ 1001 DstRolCntAvNDrRstOc 250;
BA_REL_ "GenSigTimeoutMsg" BU_SG_REL_ CGM_HS SG_ 1001 DstRolCntAvNDrRstOc 1001;
BA_REL_ "GenSigSuprvResp" BU_SG_REL_ CGM_HS SG_ 1001 DstRolCntAvNDrRstOc 1;
BA_REL_ "GenSigTimeoutTime" BU_SG_REL_ EBCM_HS SG_ 1001 DstRolCntAvNDrRstOc 1000;
BA_REL_ "GenSigTimeoutMsg" BU_SG_REL_ EBCM_HS SG_ 1001 DstRolCntAvNDrRstOc 1001;
BA_REL_ "GenSigSuprvResp" BU_SG_REL_ EBCM_HS SG_ 1001 DstRolCntAvNDrRstOc 1;
BA_REL_ "GenSigTimeoutTime" BU_SG_REL_ CGM_HS SG_ 1001 DstRolCntAvgNonDrvn 250;
BA_REL_ "GenSigTimeoutMsg" BU_SG_REL_ CGM_HS SG_ 1001 DstRolCntAvgNonDrvn 1001;
BA_REL_ "GenSigSuprvResp" BU_SG_REL_ CGM_HS SG_ 1001 DstRolCntAvgNonDrvn 1;
BA_REL_ "GenSigTimeoutTime" BU_SG_REL_ EBCM_HS SG_ 1001 DstRolCntAvgNonDrvn 1000;
BA_REL_ "GenSigTimeoutMsg" BU_SG_REL_ EBCM_HS SG_ 1001 DstRolCntAvgNonDrvn 1001;
BA_REL_ "GenSigSuprvResp" BU_SG_REL_ EBCM_HS SG_ 1001 DstRolCntAvgNonDrvn 1;
BA_REL_ "GenSigTimeoutTime" BU_SG_REL_ BSM_HS SG_ 1001 DstRolCntAvgNonDrvn 500;
BA_REL_ "GenSigTimeoutMsg" BU_SG_REL_ BSM_HS SG_ 1001 DstRolCntAvgNonDrvn 1001;
BA_REL_ "GenSigSuprvResp" BU_SG_REL_ BSM_HS SG_ 1001 DstRolCntAvgNonDrvn 1;
BA_REL_ "GenSigTimeoutTime" BU_SG_REL_ BCM_HS SG_ 1001 DstRolCntAvgNonDrvn 250;
BA_REL_ "GenSigTimeoutMsg" BU_SG_REL_ BCM_HS SG_ 1001 DstRolCntAvgNonDrvn 1001;
BA_REL_ "GenSigVBitResp" BU_SG_REL_ BCM_HS SG_ 1001 DstRolCntAvgNonDrvn 1;
BA_REL_ "GenSigSuprvResp" BU_SG_REL_ BCM_HS SG_ 1001 DstRolCntAvgNonDrvn 1;
BA_REL_ "GenSigTimeoutTime" BU_SG_REL_ CGM_HS SG_ 1001 DstRolCntAvgDrnRstOc 250;
BA_REL_ "GenSigTimeoutMsg" BU_SG_REL_ CGM_HS SG_ 1001 DstRolCntAvgDrnRstOc 1001;
BA_REL_ "GenSigSuprvResp" BU_SG_REL_ CGM_HS SG_ 1001 DstRolCntAvgDrnRstOc 1;
BA_REL_ "GenSigTimeoutTime" BU_SG_REL_ EBCM_HS SG_ 1001 DstRolCntAvgDrnRstOc 1000;
BA_REL_ "GenSigTimeoutMsg" BU_SG_REL_ EBCM_HS SG_ 1001 DstRolCntAvgDrnRstOc 1001;
BA_REL_ "GenSigSuprvResp" BU_SG_REL_ EBCM_HS SG_ 1001 DstRolCntAvgDrnRstOc 1;
BA_REL_ "GenSigTimeoutTime" BU_SG_REL_ CGM_HS SG_ 1001 DistRollCntAvgDrvn 250;
BA_REL_ "GenSigTimeoutMsg" BU_SG_REL_ CGM_HS SG_ 1001 DistRollCntAvgDrvn 1001;
BA_REL_ "GenSigSuprvResp" BU_SG_REL_ CGM_HS SG_ 1001 DistRollCntAvgDrvn 1;
BA_REL_ "GenSigTimeoutTime" BU_SG_REL_ EBCM_HS SG_ 1001 DistRollCntAvgDrvn 1000;
BA_REL_ "GenSigTimeoutMsg" BU_SG_REL_ EBCM_HS SG_ 1001 DistRollCntAvgDrvn 1001;
BA_REL_ "GenSigSuprvResp" BU_SG_REL_ EBCM_HS SG_ 1001 DistRollCntAvgDrvn 1;
BA_REL_ "GenSigTimeoutTime" BU_SG_REL_ BSM_HS SG_ 1001 DistRollCntAvgDrvn 500;
BA_REL_ "GenSigTimeoutMsg" BU_SG_REL_ BSM_HS SG_ 1001 DistRollCntAvgDrvn 1001;
BA_REL_ "GenSigSuprvResp" BU_SG_REL_ BSM_HS SG_ 1001 DistRollCntAvgDrvn 1;
BA_REL_ "GenSigTimeoutTime" BU_SG_REL_ BCM_HS SG_ 1001 DistRollCntAvgDrvn 250;
BA_REL_ "GenSigTimeoutMsg" BU_SG_REL_ BCM_HS SG_ 1001 DistRollCntAvgDrvn 1001;
BA_REL_ "GenSigVBitResp" BU_SG_REL_ BCM_HS SG_ 1001 DistRollCntAvgDrvn 1;
BA_REL_ "GenSigSuprvResp" BU_SG_REL_ BCM_HS SG_ 1001 DistRollCntAvgDrvn 1;
BA_REL_ "GenSigTimeoutTime" BU_SG_REL_ CGM_HS SG_ 1001 VehSpdAvgNDrvn 250;
BA_REL_ "GenSigTimeoutMsg" BU_SG_REL_ CGM_HS SG_ 1001 VehSpdAvgNDrvn 1001;
BA_REL_ "GenSigSuprvResp" BU_SG_REL_ CGM_HS SG_ 1001 VehSpdAvgNDrvn 1;
BA_REL_ "GenSigTimeoutTime" BU_SG_REL_ EBCM_HS SG_ 1001 VehSpdAvgNDrvn 1000;
BA_REL_ "GenSigTimeoutMsg" BU_SG_REL_ EBCM_HS SG_ 1001 VehSpdAvgNDrvn 1001;
BA_REL_ "GenSigSuprvResp" BU_SG_REL_ EBCM_HS SG_ 1001 VehSpdAvgNDrvn 1;
BA_REL_ "GenSigTimeoutTime" BU_SG_REL_ BSM_HS SG_ 1001 VehSpdAvgNDrvn 500;
BA_REL_ "GenSigTimeoutMsg" BU_SG_REL_ BSM_HS SG_ 1001 VehSpdAvgNDrvn 1001;
BA_REL_ "GenSigSuprvResp" BU_SG_REL_ BSM_HS SG_ 1001 VehSpdAvgNDrvn 1;
BA_REL_ "GenSigTimeoutTime" BU_SG_REL_ BCM_HS SG_ 1001 VehSpdAvgNDrvn 250;
BA_REL_ "GenSigTimeoutMsg" BU_SG_REL_ BCM_HS SG_ 1001 VehSpdAvgNDrvn 1001;
BA_REL_ "GenSigVBitResp" BU_SG_REL_ BCM_HS SG_ 1001 VehSpdAvgNDrvn 1;
BA_REL_ "GenSigSuprvResp" BU_SG_REL_ BCM_HS SG_ 1001 VehSpdAvgNDrvn 1;
BA_REL_ "GenSigTimeoutTime" BU_SG_REL_ CGM_HS SG_ 1001 VehSpdAvgDrvn 250;
BA_REL_ "GenSigTimeoutMsg" BU_SG_REL_ CGM_HS SG_ 1001 VehSpdAvgDrvn 1001;
BA_REL_ "GenSigSuprvResp" BU_SG_REL_ CGM_HS SG_ 1001 VehSpdAvgDrvn 1;
BA_REL_ "GenSigTimeoutTime" BU_SG_REL_ EPS_HS SG_ 1001 VehSpdAvgDrvn 250;
BA_REL_ "GenSigTimeoutMsg" BU_SG_REL_ EPS_HS SG_ 1001 VehSpdAvgDrvn 1001;
BA_REL_ "GenSigSuprvResp" BU_SG_REL_ EPS_HS SG_ 1001 VehSpdAvgDrvn 1;
BA_REL_ "GenSigTimeoutTime" BU_SG_REL_ EBCM_HS SG_ 1001 VehSpdAvgDrvn 1000;
BA_REL_ "GenSigTimeoutMsg" BU_SG_REL_ EBCM_HS SG_ 1001 VehSpdAvgDrvn 1001;
BA_REL_ "GenSigSuprvResp" BU_SG_REL_ EBCM_HS SG_ 1001 VehSpdAvgDrvn 1;
BA_REL_ "GenSigTimeoutTime" BU_SG_REL_ BSM_HS SG_ 1001 VehSpdAvgDrvn 500;
BA_REL_ "GenSigTimeoutMsg" BU_SG_REL_ BSM_HS SG_ 1001 VehSpdAvgDrvn 1001;
BA_REL_ "GenSigSuprvResp" BU_SG_REL_ BSM_HS SG_ 1001 VehSpdAvgDrvn 1;
BA_REL_ "GenSigTimeoutTime" BU_SG_REL_ BCM_HS SG_ 1001 VehSpdAvgDrvn 250;
BA_REL_ "GenSigTimeoutMsg" BU_SG_REL_ BCM_HS SG_ 1001 VehSpdAvgDrvn 1001;
BA_REL_ "GenSigVBitResp" BU_SG_REL_ BCM_HS SG_ 1001 VehSpdAvgDrvn 1;
BA_REL_ "GenSigSuprvResp" BU_SG_REL_ BCM_HS SG_ 1001 VehSpdAvgDrvn 1;
BA_REL_ "GenSigTimeoutTime" BU_SG_REL_ CGM_HS SG_ 842 WhlRotDrctnlSRtNDrvn 250;
BA_REL_ "GenSigTimeoutMsg" BU_SG_REL_ CGM_HS SG_ 842 WhlRotDrctnlSRtNDrvn 842;
BA_REL_ "GenSigSuprvResp" BU_SG_REL_ CGM_HS SG_ 842 WhlRotDrctnlSRtNDrvn 1;
BA_REL_ "GenSigTimeoutTime" BU_SG_REL_ EPS_HS SG_ 842 WhlRotDrctnlSRtNDrvn 250;
BA_REL_ "GenSigTimeoutMsg" BU_SG_REL_ EPS_HS SG_ 842 WhlRotDrctnlSRtNDrvn 842;
BA_REL_ "GenSigSuprvResp" BU_SG_REL_ EPS_HS SG_ 842 WhlRotDrctnlSRtNDrvn 1;
BA_REL_ "GenSigTimeoutTime" BU_SG_REL_ CGM_HS SG_ 842 WhlRotDrctnlStLfNDrvn 250;
BA_REL_ "GenSigTimeoutMsg" BU_SG_REL_ CGM_HS SG_ 842 WhlRotDrctnlStLfNDrvn 842;
BA_REL_ "GenSigSuprvResp" BU_SG_REL_ CGM_HS SG_ 842 WhlRotDrctnlStLfNDrvn 1;
BA_REL_ "GenSigTimeoutTime" BU_SG_REL_ EPS_HS SG_ 842 WhlRotDrctnlStLfNDrvn 250;
BA_REL_ "GenSigTimeoutMsg" BU_SG_REL_ EPS_HS SG_ 842 WhlRotDrctnlStLfNDrvn 842;
BA_REL_ "GenSigSuprvResp" BU_SG_REL_ EPS_HS SG_ 842 WhlRotDrctnlStLfNDrvn 1;
BA_REL_ "GenSigTimeoutTime" BU_SG_REL_ CGM_HS SG_ 842 WhlGrndVlctyRtNnDrvn 250;
BA_REL_ "GenSigTimeoutMsg" BU_SG_REL_ CGM_HS SG_ 842 WhlGrndVlctyRtNnDrvn 842;
BA_REL_ "GenSigSuprvResp" BU_SG_REL_ CGM_HS SG_ 842 WhlGrndVlctyRtNnDrvn 1;
BA_REL_ "GenSigTimeoutTime" BU_SG_REL_ EPS_HS SG_ 842 WhlGrndVlctyRtNnDrvn 250;
BA_REL_ "GenSigTimeoutMsg" BU_SG_REL_ EPS_HS SG_ 842 WhlGrndVlctyRtNnDrvn 842;
BA_REL_ "GenSigSuprvResp" BU_SG_REL_ EPS_HS SG_ 842 WhlGrndVlctyRtNnDrvn 1;
BA_REL_ "GenSigTimeoutTime" BU_SG_REL_ BCM_HS SG_ 842 WhlGrndVlctyRtNnDrvn 250;
BA_REL_ "GenSigTimeoutMsg" BU_SG_REL_ BCM_HS SG_ 842 WhlGrndVlctyRtNnDrvn 842;
BA_REL_ "GenSigVBitResp" BU_SG_REL_ BCM_HS SG_ 842 WhlGrndVlctyRtNnDrvn 1;
BA_REL_ "GenSigSuprvResp" BU_SG_REL_ BCM_HS SG_ 842 WhlGrndVlctyRtNnDrvn 1;
BA_REL_ "GenSigTimeoutTime" BU_SG_REL_ CGM_HS SG_ 842 WhlGrndVlctyLftNnDrvn 250;
BA_REL_ "GenSigTimeoutMsg" BU_SG_REL_ CGM_HS SG_ 842 WhlGrndVlctyLftNnDrvn 842;
BA_REL_ "GenSigSuprvResp" BU_SG_REL_ CGM_HS SG_ 842 WhlGrndVlctyLftNnDrvn 1;
BA_REL_ "GenSigTimeoutTime" BU_SG_REL_ RDCM_HS SG_ 842 WhlGrndVlctyLftNnDrvn 250;
BA_REL_ "GenSigTimeoutMsg" BU_SG_REL_ RDCM_HS SG_ 842 WhlGrndVlctyLftNnDrvn 842;
BA_REL_ "GenSigVBitResp" BU_SG_REL_ RDCM_HS SG_ 842 WhlGrndVlctyLftNnDrvn 1;
BA_REL_ "GenSigSuprvResp" BU_SG_REL_ RDCM_HS SG_ 842 WhlGrndVlctyLftNnDrvn 1;
BA_REL_ "GenSigTimeoutTime" BU_SG_REL_ BCM_HS SG_ 842 WhlGrndVlctyLftNnDrvn 250;
BA_REL_ "GenSigTimeoutMsg" BU_SG_REL_ BCM_HS SG_ 842 WhlGrndVlctyLftNnDrvn 842;
BA_REL_ "GenSigVBitResp" BU_SG_REL_ BCM_HS SG_ 842 WhlGrndVlctyLftNnDrvn 1;
BA_REL_ "GenSigSuprvResp" BU_SG_REL_ BCM_HS SG_ 842 WhlGrndVlctyLftNnDrvn 1;
BA_REL_ "GenSigTimeoutTime" BU_SG_REL_ BSM_HS SG_ 1019 FuelAlcoholComp 625;
BA_REL_ "GenSigTimeoutMsg" BU_SG_REL_ BSM_HS SG_ 1019 FuelAlcoholComp 1019;
BA_REL_ "GenSigSuprvResp" BU_SG_REL_ BSM_HS SG_ 1019 FuelAlcoholComp 1;
BA_REL_ "GenSigTimeoutTime" BU_SG_REL_ EBCM_HS SG_ 1265 EngOffTmPT 2500;
BA_REL_ "GenSigTimeoutMsg" BU_SG_REL_ EBCM_HS SG_ 1265 EngOffTmPT 1265;
BA_REL_ "GenSigSuprvResp" BU_SG_REL_ EBCM_HS SG_ 1265 EngOffTmPT 1;
BA_REL_ "GenSigTimeoutTime" BU_SG_REL_ TCM_HS SG_ 1265 WhlDistPrRevNDrvn 2500;
BA_REL_ "GenSigTimeoutMsg" BU_SG_REL_ TCM_HS SG_ 1265 WhlDistPrRevNDrvn 1265;
BA_REL_ "GenSigSuprvResp" BU_SG_REL_ TCM_HS SG_ 1265 WhlDistPrRevNDrvn 1;
BA_REL_ "GenSigRxStartValue" BU_SG_REL_ RDCM_HS SG_ 1265 WhlDistPrRevNDrvn "2000 mm ($190)";
BA_REL_ "GenSigTimeoutTime" BU_SG_REL_ EPS_HS SG_ 1265 WhlDistPrRevNDrvn 2500;
BA_REL_ "GenSigTimeoutMsg" BU_SG_REL_ EPS_HS SG_ 1265 WhlDistPrRevNDrvn 1265;
BA_REL_ "GenSigSuprvResp" BU_SG_REL_ EPS_HS SG_ 1265 WhlDistPrRevNDrvn 1;
BA_REL_ "GenSigTimeoutTime" BU_SG_REL_ EBCM_HS SG_ 1265 WhlDistPrRevNDrvn 2500;
BA_REL_ "GenSigTimeoutMsg" BU_SG_REL_ EBCM_HS SG_ 1265 WhlDistPrRevNDrvn 1265;
BA_REL_ "GenSigSuprvResp" BU_SG_REL_ EBCM_HS SG_ 1265 WhlDistPrRevNDrvn 1;
BA_REL_ "GenSigTimeoutTime" BU_SG_REL_ TCM_HS SG_ 1265 WhlDistPrRevDrvn 2500;
BA_REL_ "GenSigTimeoutMsg" BU_SG_REL_ TCM_HS SG_ 1265 WhlDistPrRevDrvn 1265;
BA_REL_ "GenSigSuprvResp" BU_SG_REL_ TCM_HS SG_ 1265 WhlDistPrRevDrvn 1;
BA_REL_ "GenSigTimeoutTime" BU_SG_REL_ RDCM_HS SG_ 1265 WhlDistPrRevDrvn 2500;
BA_REL_ "GenSigTimeoutMsg" BU_SG_REL_ RDCM_HS SG_ 1265 WhlDistPrRevDrvn 1265;
BA_REL_ "GenSigRxStartValue" BU_SG_REL_ RDCM_HS SG_ 1265 WhlDistPrRevDrvn "2000 mm ($190)";
BA_REL_ "GenSigSuprvResp" BU_SG_REL_ RDCM_HS SG_ 1265 WhlDistPrRevDrvn 1;
BA_REL_ "GenSigTimeoutTime" BU_SG_REL_ EPS_HS SG_ 1265 WhlDistPrRevDrvn 2500;
BA_REL_ "GenSigTimeoutMsg" BU_SG_REL_ EPS_HS SG_ 1265 WhlDistPrRevDrvn 1265;
BA_REL_ "GenSigSuprvResp" BU_SG_REL_ EPS_HS SG_ 1265 WhlDistPrRevDrvn 1;
BA_REL_ "GenSigTimeoutTime" BU_SG_REL_ EBCM_HS SG_ 1265 WhlDistPrRevDrvn 2500;
BA_REL_ "GenSigTimeoutMsg" BU_SG_REL_ EBCM_HS SG_ 1265 WhlDistPrRevDrvn 1265;
BA_REL_ "GenSigSuprvResp" BU_SG_REL_ EBCM_HS SG_ 1265 WhlDistPrRevDrvn 1;
BA_REL_ "GenSigTimeoutTime" BU_SG_REL_ BCM_HS SG_ 1265 WhlDistPrRevDrvn 2500;
BA_REL_ "GenSigTimeoutMsg" BU_SG_REL_ BCM_HS SG_ 1265 WhlDistPrRevDrvn 1265;
BA_REL_ "GenSigSuprvResp" BU_SG_REL_ BCM_HS SG_ 1265 WhlDistPrRevDrvn 1;
BA_REL_ "GenSigTimeoutTime" BU_SG_REL_ TCM_HS SG_ 1265 DrvlnFnlAxleRatio 2500;
BA_REL_ "GenSigTimeoutMsg" BU_SG_REL_ TCM_HS SG_ 1265 DrvlnFnlAxleRatio 1265;
BA_REL_ "GenSigSuprvResp" BU_SG_REL_ TCM_HS SG_ 1265 DrvlnFnlAxleRatio 1;
BA_REL_ "GenSigTimeoutTime" BU_SG_REL_ EBCM_HS SG_ 1265 DrvlnFnlAxleRatio 2500;
BA_REL_ "GenSigTimeoutMsg" BU_SG_REL_ EBCM_HS SG_ 1265 DrvlnFnlAxleRatio 1265;
BA_REL_ "GenSigSuprvResp" BU_SG_REL_ EBCM_HS SG_ 1265 DrvlnFnlAxleRatio 1;
BA_REL_ "GenSigTimeoutTime" BU_SG_REL_ BCM_HS SG_ 1265 DrvlnFnlAxleRatio 2500;
BA_REL_ "GenSigTimeoutMsg" BU_SG_REL_ BCM_HS SG_ 1265 DrvlnFnlAxleRatio 1265;
BA_REL_ "GenSigSuprvResp" BU_SG_REL_ BCM_HS SG_ 1265 DrvlnFnlAxleRatio 1;
BA_REL_ "GenSigTimeoutTime" BU_SG_REL_ TCM_HS SG_ 417 EngRunng 62;
BA_REL_ "GenSigTimeoutMsg" BU_SG_REL_ TCM_HS SG_ 417 EngRunng 417;
BA_REL_ "GenSigSuprvResp" BU_SG_REL_ TCM_HS SG_ 417 EngRunng 1;
BA_REL_ "GenSigTimeoutTime" BU_SG_REL_ TCM_HS SG_ 417 EngCylDeactMd 62;
BA_REL_ "GenSigTimeoutMsg" BU_SG_REL_ TCM_HS SG_ 417 EngCylDeactMd 417;
BA_REL_ "GenSigSuprvResp" BU_SG_REL_ TCM_HS SG_ 417 EngCylDeactMd 1;
BA_REL_ "GenSigTimeoutTime" BU_SG_REL_ TCM_HS SG_ 417 TracCntlSysPwrtrnInhbt 62;
BA_REL_ "GenSigTimeoutMsg" BU_SG_REL_ TCM_HS SG_ 417 TracCntlSysPwrtrnInhbt 417;
BA_REL_ "GenSigSuprvResp" BU_SG_REL_ TCM_HS SG_ 417 TracCntlSysPwrtrnInhbt 1;
BA_REL_ "GenSigTimeoutTime" BU_SG_REL_ TCM_HS SG_ 417 EngMtlProtAtv 62;
BA_REL_ "GenSigTimeoutMsg" BU_SG_REL_ TCM_HS SG_ 417 EngMtlProtAtv 417;
BA_REL_ "GenSigSuprvResp" BU_SG_REL_ TCM_HS SG_ 417 EngMtlProtAtv 1;
BA_REL_ "GenSigTimeoutTime" BU_SG_REL_ TCM_HS SG_ 417 EngDgTrqCnvClUnlkRqd 62;
BA_REL_ "GenSigTimeoutMsg" BU_SG_REL_ TCM_HS SG_ 417 EngDgTrqCnvClUnlkRqd 417;
BA_REL_ "GenSigSuprvResp" BU_SG_REL_ TCM_HS SG_ 417 EngDgTrqCnvClUnlkRqd 1;
BA_REL_ "GenSigTimeoutTime" BU_SG_REL_ TCM_HS SG_ 417 EngCyldrDeactReqd 62;
BA_REL_ "GenSigTimeoutMsg" BU_SG_REL_ TCM_HS SG_ 417 EngCyldrDeactReqd 417;
BA_REL_ "GenSigSuprvResp" BU_SG_REL_ TCM_HS SG_ 417 EngCyldrDeactReqd 1;
BA_REL_ "GenSigTimeoutTime" BU_SG_REL_ TCM_HS SG_ 417 ETGRReqdGear 62;
BA_REL_ "GenSigTimeoutMsg" BU_SG_REL_ TCM_HS SG_ 417 ETGRReqdGear 417;
BA_REL_ "GenSigSuprvResp" BU_SG_REL_ TCM_HS SG_ 417 ETGRReqdGear 1;
BA_REL_ "GenSigTimeoutTime" BU_SG_REL_ TCM_HS SG_ 417 ETGRReqType 62;
BA_REL_ "GenSigTimeoutMsg" BU_SG_REL_ TCM_HS SG_ 417 ETGRReqType 417;
BA_REL_ "GenSigSuprvResp" BU_SG_REL_ TCM_HS SG_ 417 ETGRReqType 1;
BA_REL_ "GenSigTimeoutTime" BU_SG_REL_ BCM_HS SG_ 1233 PTExPrtclFltWrng3IO 1250;
BA_REL_ "GenSigTimeoutMsg" BU_SG_REL_ BCM_HS SG_ 1233 PTExPrtclFltWrng3IO 1233;
BA_REL_ "GenSigSuprvResp" BU_SG_REL_ BCM_HS SG_ 1233 PTExPrtclFltWrng3IO 1;
BA_REL_ "GenSigTimeoutTime" BU_SG_REL_ BCM_HS SG_ 1233 PTExPartFltManRegStat 1250;
BA_REL_ "GenSigTimeoutMsg" BU_SG_REL_ BCM_HS SG_ 1233 PTExPartFltManRegStat 1233;
BA_REL_ "GenSigSuprvResp" BU_SG_REL_ BCM_HS SG_ 1233 PTExPartFltManRegStat 1;
BA_REL_ "GenSigTimeoutTime" BU_SG_REL_ BCM_HS SG_ 1233 EngShtdwnAct 1250;
BA_REL_ "GenSigTimeoutMsg" BU_SG_REL_ BCM_HS SG_ 1233 EngShtdwnAct 1233;
BA_REL_ "GenSigSuprvResp" BU_SG_REL_ BCM_HS SG_ 1233 EngShtdwnAct 1;
BA_REL_ "GenSigTimeoutTime" BU_SG_REL_ BCM_HS SG_ 1233 FlLvlPct 1250;
BA_REL_ "GenSigTimeoutMsg" BU_SG_REL_ BCM_HS SG_ 1233 FlLvlPct 1233;
BA_REL_ "GenSigVBitResp" BU_SG_REL_ BCM_HS SG_ 1233 FlLvlPct 1;
BA_REL_ "GenSigSuprvResp" BU_SG_REL_ BCM_HS SG_ 1233 FlLvlPct 1;
BA_REL_ "GenSigTimeoutTime" BU_SG_REL_ EPS_HS SG_ 1233 EngOilTmp 1250;
BA_REL_ "GenSigTimeoutMsg" BU_SG_REL_ EPS_HS SG_ 1233 EngOilTmp 1233;
BA_REL_ "GenSigSuprvResp" BU_SG_REL_ EPS_HS SG_ 1233 EngOilTmp 1;
BA_REL_ "GenSigTimeoutTime" BU_SG_REL_ BCM_HS SG_ 1233 EngOilTmp 1250;
BA_REL_ "GenSigTimeoutMsg" BU_SG_REL_ BCM_HS SG_ 1233 EngOilTmp 1233;
BA_REL_ "GenSigVBitResp" BU_SG_REL_ BCM_HS SG_ 1233 EngOilTmp 1;
BA_REL_ "GenSigSuprvResp" BU_SG_REL_ BCM_HS SG_ 1233 EngOilTmp 1;
BA_REL_ "GenSigTimeoutTime" BU_SG_REL_ BCM_HS SG_ 1233 EngOilPrs 1250;
BA_REL_ "GenSigTimeoutMsg" BU_SG_REL_ BCM_HS SG_ 1233 EngOilPrs 1233;
BA_REL_ "GenSigVBitResp" BU_SG_REL_ BCM_HS SG_ 1233 EngOilPrs 1;
BA_REL_ "GenSigSuprvResp" BU_SG_REL_ BCM_HS SG_ 1233 EngOilPrs 1;
BA_REL_ "GenSigTimeoutTime" BU_SG_REL_ TCM_HS SG_ 1217 LDMaxEngCltTmpRchd 1250;
BA_REL_ "GenSigTimeoutMsg" BU_SG_REL_ TCM_HS SG_ 1217 LDMaxEngCltTmpRchd 1217;
BA_REL_ "GenSigSuprvResp" BU_SG_REL_ TCM_HS SG_ 1217 LDMaxEngCltTmpRchd 1;
BA_REL_ "GenSigTimeoutTime" BU_SG_REL_ CGM_HS SG_ 1217 LDMinEngCltTmpRchd 1250;
BA_REL_ "GenSigTimeoutMsg" BU_SG_REL_ CGM_HS SG_ 1217 LDMinEngCltTmpRchd 1217;
BA_REL_ "GenSigSuprvResp" BU_SG_REL_ CGM_HS SG_ 1217 LDMinEngCltTmpRchd 1;
BA_REL_ "GenSigTimeoutTime" BU_SG_REL_ TCM_HS SG_ 1217 LDMinEngCltTmpRchd 1250;
BA_REL_ "GenSigTimeoutMsg" BU_SG_REL_ TCM_HS SG_ 1217 LDMinEngCltTmpRchd 1217;
BA_REL_ "GenSigSuprvResp" BU_SG_REL_ TCM_HS SG_ 1217 LDMinEngCltTmpRchd 1;
BA_REL_ "GenSigTimeoutTime" BU_SG_REL_ TCM_HS SG_ 1217 CdClrInhbt 1250;
BA_REL_ "GenSigTimeoutMsg" BU_SG_REL_ TCM_HS SG_ 1217 CdClrInhbt 1217;
BA_REL_ "GenSigSuprvResp" BU_SG_REL_ TCM_HS SG_ 1217 CdClrInhbt 1;
BA_REL_ "GenSigTimeoutTime" BU_SG_REL_ EBCM_HS SG_ 1217 CdClrInhbt 1250;
BA_REL_ "GenSigTimeoutMsg" BU_SG_REL_ EBCM_HS SG_ 1217 CdClrInhbt 1217;
BA_REL_ "GenSigSuprvResp" BU_SG_REL_ EBCM_HS SG_ 1217 CdClrInhbt 1;
BA_REL_ "GenSigTimeoutTime" BU_SG_REL_ BSM_HS SG_ 1217 CdClrInhbt 1250;
BA_REL_ "GenSigTimeoutMsg" BU_SG_REL_ BSM_HS SG_ 1217 CdClrInhbt 1217;
BA_REL_ "GenSigSuprvResp" BU_SG_REL_ BSM_HS SG_ 1217 CdClrInhbt 1;
BA_REL_ "GenSigTimeoutTime" BU_SG_REL_ CGM_HS SG_ 1217 LegPstDTCClrDrvCyCm 1250;
BA_REL_ "GenSigTimeoutMsg" BU_SG_REL_ CGM_HS SG_ 1217 LegPstDTCClrDrvCyCm 1217;
BA_REL_ "GenSigSuprvResp" BU_SG_REL_ CGM_HS SG_ 1217 LegPstDTCClrDrvCyCm 1;
BA_REL_ "GenSigTimeoutTime" BU_SG_REL_ EBCM_HS SG_ 1217 LegPstDTCClrDrvCyCm 1250;
BA_REL_ "GenSigTimeoutMsg" BU_SG_REL_ EBCM_HS SG_ 1217 LegPstDTCClrDrvCyCm 1217;
BA_REL_ "GenSigSuprvResp" BU_SG_REL_ EBCM_HS SG_ 1217 LegPstDTCClrDrvCyCm 1;
BA_REL_ "GenSigTimeoutTime" BU_SG_REL_ CGM_HS SG_ 1217 LegDiagColdStCndMet 1250;
BA_REL_ "GenSigTimeoutMsg" BU_SG_REL_ CGM_HS SG_ 1217 LegDiagColdStCndMet 1217;
BA_REL_ "GenSigSuprvResp" BU_SG_REL_ CGM_HS SG_ 1217 LegDiagColdStCndMet 1;
BA_REL_ "GenSigTimeoutTime" BU_SG_REL_ EBCM_HS SG_ 1217 LegDiagColdStCndMet 1250;
BA_REL_ "GenSigTimeoutMsg" BU_SG_REL_ EBCM_HS SG_ 1217 LegDiagColdStCndMet 1217;
BA_REL_ "GenSigSuprvResp" BU_SG_REL_ EBCM_HS SG_ 1217 LegDiagColdStCndMet 1;
BA_REL_ "GenSigTimeoutTime" BU_SG_REL_ CGM_HS SG_ 1217 LegDiagColdStCndFltPr 1250;
BA_REL_ "GenSigTimeoutMsg" BU_SG_REL_ CGM_HS SG_ 1217 LegDiagColdStCndFltPr 1217;
BA_REL_ "GenSigSuprvResp" BU_SG_REL_ CGM_HS SG_ 1217 LegDiagColdStCndFltPr 1;
BA_REL_ "GenSigTimeoutTime" BU_SG_REL_ EBCM_HS SG_ 1217 LegDiagColdStCndFltPr 1250;
BA_REL_ "GenSigTimeoutMsg" BU_SG_REL_ EBCM_HS SG_ 1217 LegDiagColdStCndFltPr 1217;
BA_REL_ "GenSigSuprvResp" BU_SG_REL_ EBCM_HS SG_ 1217 LegDiagColdStCndFltPr 1;
BA_REL_ "GenSigTimeoutTime" BU_SG_REL_ CGM_HS SG_ 1217 LegDiagStndCndMet 1250;
BA_REL_ "GenSigTimeoutMsg" BU_SG_REL_ CGM_HS SG_ 1217 LegDiagStndCndMet 1217;
BA_REL_ "GenSigSuprvResp" BU_SG_REL_ CGM_HS SG_ 1217 LegDiagStndCndMet 1;
BA_REL_ "GenSigTimeoutTime" BU_SG_REL_ EBCM_HS SG_ 1217 LegDiagStndCndMet 1250;
BA_REL_ "GenSigTimeoutMsg" BU_SG_REL_ EBCM_HS SG_ 1217 LegDiagStndCndMet 1217;
BA_REL_ "GenSigSuprvResp" BU_SG_REL_ EBCM_HS SG_ 1217 LegDiagStndCndMet 1;
BA_REL_ "GenSigTimeoutTime" BU_SG_REL_ CGM_HS SG_ 1217 LegDiagStndCndFltPr 1250;
BA_REL_ "GenSigTimeoutMsg" BU_SG_REL_ CGM_HS SG_ 1217 LegDiagStndCndFltPr 1217;
BA_REL_ "GenSigSuprvResp" BU_SG_REL_ CGM_HS SG_ 1217 LegDiagStndCndFltPr 1;
BA_REL_ "GenSigTimeoutTime" BU_SG_REL_ EBCM_HS SG_ 1217 LegDiagStndCndFltPr 1250;
BA_REL_ "GenSigTimeoutMsg" BU_SG_REL_ EBCM_HS SG_ 1217 LegDiagStndCndFltPr 1217;
BA_REL_ "GenSigSuprvResp" BU_SG_REL_ EBCM_HS SG_ 1217 LegDiagStndCndFltPr 1;
BA_REL_ "GenSigTimeoutTime" BU_SG_REL_ CGM_HS SG_ 1217 EngWrmUpAch 1250;
BA_REL_ "GenSigTimeoutMsg" BU_SG_REL_ CGM_HS SG_ 1217 EngWrmUpAch 1217;
BA_REL_ "GenSigSuprvResp" BU_SG_REL_ CGM_HS SG_ 1217 EngWrmUpAch 1;
BA_REL_ "GenSigTimeoutTime" BU_SG_REL_ EBCM_HS SG_ 1217 EngWrmUpAch 1250;
BA_REL_ "GenSigTimeoutMsg" BU_SG_REL_ EBCM_HS SG_ 1217 EngWrmUpAch 1217;
BA_REL_ "GenSigSuprvResp" BU_SG_REL_ EBCM_HS SG_ 1217 EngWrmUpAch 1;
BA_REL_ "GenSigTimeoutTime" BU_SG_REL_ CGM_HS SG_ 1217 DslExhFldRmngDstHRs 1250;
BA_REL_ "GenSigTimeoutMsg" BU_SG_REL_ CGM_HS SG_ 1217 DslExhFldRmngDstHRs 1217;
BA_REL_ "GenSigSuprvResp" BU_SG_REL_ CGM_HS SG_ 1217 DslExhFldRmngDstHRs 1;
BA_REL_ "GenSigTimeoutTime" BU_SG_REL_ CGM_HS SG_ 1217 EngOilHotIO 1250;
BA_REL_ "GenSigTimeoutMsg" BU_SG_REL_ CGM_HS SG_ 1217 EngOilHotIO 1217;
BA_REL_ "GenSigSuprvResp" BU_SG_REL_ CGM_HS SG_ 1217 EngOilHotIO 1;
BA_REL_ "GenSigTimeoutTime" BU_SG_REL_ CGM_HS SG_ 1217 OAT_PT_Est 1250;
BA_REL_ "GenSigTimeoutMsg" BU_SG_REL_ CGM_HS SG_ 1217 OAT_PT_Est 1217;
BA_REL_ "GenSigSuprvResp" BU_SG_REL_ CGM_HS SG_ 1217 OAT_PT_Est 1;
BA_REL_ "GenSigTimeoutTime" BU_SG_REL_ TCM_HS SG_ 1217 OAT_PT_Est 1250;
BA_REL_ "GenSigTimeoutMsg" BU_SG_REL_ TCM_HS SG_ 1217 OAT_PT_Est 1217;
BA_REL_ "GenSigSuprvResp" BU_SG_REL_ TCM_HS SG_ 1217 OAT_PT_Est 1;
BA_REL_ "GenSigTimeoutTime" BU_SG_REL_ RDCM_HS SG_ 1217 OAT_PT_Est 1250;
BA_REL_ "GenSigTimeoutMsg" BU_SG_REL_ RDCM_HS SG_ 1217 OAT_PT_Est 1217;
BA_REL_ "GenSigVBitResp" BU_SG_REL_ RDCM_HS SG_ 1217 OAT_PT_Est 1;
BA_REL_ "GenSigRxStartValue" BU_SG_REL_ RDCM_HS SG_ 1217 OAT_PT_Est "0 degrees ($80)";
BA_REL_ "GenSigSuprvResp" BU_SG_REL_ RDCM_HS SG_ 1217 OAT_PT_Est 1;
BA_REL_ "GenSigTimeoutTime" BU_SG_REL_ EBCM_HS SG_ 1217 OAT_PT_Est 1250;
BA_REL_ "GenSigTimeoutMsg" BU_SG_REL_ EBCM_HS SG_ 1217 OAT_PT_Est 1217;
BA_REL_ "GenSigSuprvResp" BU_SG_REL_ EBCM_HS SG_ 1217 OAT_PT_Est 1;
BA_REL_ "GenSigTimeoutTime" BU_SG_REL_ BSM_HS SG_ 1217 OAT_PT_Est 1250;
BA_REL_ "GenSigTimeoutMsg" BU_SG_REL_ BSM_HS SG_ 1217 OAT_PT_Est 1217;
BA_REL_ "GenSigSuprvResp" BU_SG_REL_ BSM_HS SG_ 1217 OAT_PT_Est 1;
BA_REL_ "GenSigTimeoutTime" BU_SG_REL_ BCM_HS SG_ 1217 OAT_PT_Est 1250;
BA_REL_ "GenSigTimeoutMsg" BU_SG_REL_ BCM_HS SG_ 1217 OAT_PT_Est 1217;
BA_REL_ "GenSigVBitResp" BU_SG_REL_ BCM_HS SG_ 1217 OAT_PT_Est 1;
BA_REL_ "GenSigSuprvResp" BU_SG_REL_ BCM_HS SG_ 1217 OAT_PT_Est 1;
BA_REL_ "GenSigTimeoutTime" BU_SG_REL_ CGM_HS SG_ 1217 EngIntAirTmp 1250;
BA_REL_ "GenSigTimeoutMsg" BU_SG_REL_ CGM_HS SG_ 1217 EngIntAirTmp 1217;
BA_REL_ "GenSigSuprvResp" BU_SG_REL_ CGM_HS SG_ 1217 EngIntAirTmp 1;
BA_REL_ "GenSigTimeoutTime" BU_SG_REL_ RDCM_HS SG_ 1217 EngIntAirTmp 1250;
BA_REL_ "GenSigTimeoutMsg" BU_SG_REL_ RDCM_HS SG_ 1217 EngIntAirTmp 1217;
BA_REL_ "GenSigSuprvResp" BU_SG_REL_ RDCM_HS SG_ 1217 EngIntAirTmp 1;
BA_REL_ "GenSigTimeoutTime" BU_SG_REL_ EBCM_HS SG_ 1217 EngIntAirTmp 1250;
BA_REL_ "GenSigTimeoutMsg" BU_SG_REL_ EBCM_HS SG_ 1217 EngIntAirTmp 1217;
BA_REL_ "GenSigSuprvResp" BU_SG_REL_ EBCM_HS SG_ 1217 EngIntAirTmp 1;
BA_REL_ "GenSigTimeoutTime" BU_SG_REL_ BSM_HS SG_ 1217 EngIntAirTmp 1250;
BA_REL_ "GenSigTimeoutMsg" BU_SG_REL_ BSM_HS SG_ 1217 EngIntAirTmp 1217;
BA_REL_ "GenSigSuprvResp" BU_SG_REL_ BSM_HS SG_ 1217 EngIntAirTmp 1;
BA_REL_ "GenSigTimeoutTime" BU_SG_REL_ BCM_HS SG_ 1217 EngIntAirTmp 1250;
BA_REL_ "GenSigTimeoutMsg" BU_SG_REL_ BCM_HS SG_ 1217 EngIntAirTmp 1217;
BA_REL_ "GenSigVBitResp" BU_SG_REL_ BCM_HS SG_ 1217 EngIntAirTmp 1;
BA_REL_ "GenSigSuprvResp" BU_SG_REL_ BCM_HS SG_ 1217 EngIntAirTmp 1;
BA_REL_ "GenSigTimeoutTime" BU_SG_REL_ CGM_HS SG_ 1217 EngCltTmp 1250;
BA_REL_ "GenSigTimeoutMsg" BU_SG_REL_ CGM_HS SG_ 1217 EngCltTmp 1217;
BA_REL_ "GenSigSuprvResp" BU_SG_REL_ CGM_HS SG_ 1217 EngCltTmp 1;
BA_REL_ "GenSigTimeoutTime" BU_SG_REL_ TCM_HS SG_ 1217 EngCltTmp 1250;
BA_REL_ "GenSigTimeoutMsg" BU_SG_REL_ TCM_HS SG_ 1217 EngCltTmp 1217;
BA_REL_ "GenSigSuprvResp" BU_SG_REL_ TCM_HS SG_ 1217 EngCltTmp 1;
BA_REL_ "GenSigTimeoutTime" BU_SG_REL_ EPS_HS SG_ 1217 EngCltTmp 1250;
BA_REL_ "GenSigTimeoutMsg" BU_SG_REL_ EPS_HS SG_ 1217 EngCltTmp 1217;
BA_REL_ "GenSigSuprvResp" BU_SG_REL_ EPS_HS SG_ 1217 EngCltTmp 1;
BA_REL_ "GenSigTimeoutTime" BU_SG_REL_ EBCM_HS SG_ 1217 EngCltTmp 1250;
BA_REL_ "GenSigTimeoutMsg" BU_SG_REL_ EBCM_HS SG_ 1217 EngCltTmp 1217;
BA_REL_ "GenSigSuprvResp" BU_SG_REL_ EBCM_HS SG_ 1217 EngCltTmp 1;
BA_REL_ "GenSigTimeoutTime" BU_SG_REL_ BSM_HS SG_ 1217 EngCltTmp 1250;
BA_REL_ "GenSigTimeoutMsg" BU_SG_REL_ BSM_HS SG_ 1217 EngCltTmp 1217;
BA_REL_ "GenSigSuprvResp" BU_SG_REL_ BSM_HS SG_ 1217 EngCltTmp 1;
BA_REL_ "GenSigTimeoutTime" BU_SG_REL_ BCM_HS SG_ 1217 EngCltTmp 1250;
BA_REL_ "GenSigTimeoutMsg" BU_SG_REL_ BCM_HS SG_ 1217 EngCltTmp 1217;
BA_REL_ "GenSigVBitResp" BU_SG_REL_ BCM_HS SG_ 1217 EngCltTmp 1;
BA_REL_ "GenSigSuprvResp" BU_SG_REL_ BCM_HS SG_ 1217 EngCltTmp 1;
BA_REL_ "GenSigTimeoutTime" BU_SG_REL_ CGM_HS SG_ 1217 BarPrsAbsV 1250;
BA_REL_ "GenSigTimeoutMsg" BU_SG_REL_ CGM_HS SG_ 1217 BarPrsAbsV 1217;
BA_REL_ "GenSigSuprvResp" BU_SG_REL_ CGM_HS SG_ 1217 BarPrsAbsV 1;
BA_REL_ "GenSigTimeoutTime" BU_SG_REL_ CGM_HS SG_ 1217 BarPrsAbs 1250;
BA_REL_ "GenSigTimeoutMsg" BU_SG_REL_ CGM_HS SG_ 1217 BarPrsAbs 1217;
BA_REL_ "GenSigSuprvResp" BU_SG_REL_ CGM_HS SG_ 1217 BarPrsAbs 1;
BA_REL_ "GenSigTimeoutTime" BU_SG_REL_ EBCM_HS SG_ 1217 BarPrsAbs 1250;
BA_REL_ "GenSigTimeoutMsg" BU_SG_REL_ EBCM_HS SG_ 1217 BarPrsAbs 1217;
BA_REL_ "GenSigSuprvResp" BU_SG_REL_ EBCM_HS SG_ 1217 BarPrsAbs 1;
BA_REL_ "GenSigTimeoutTime" BU_SG_REL_ BSM_HS SG_ 1217 BarPrsAbs 1250;
BA_REL_ "GenSigTimeoutMsg" BU_SG_REL_ BSM_HS SG_ 1217 BarPrsAbs 1217;
BA_REL_ "GenSigSuprvResp" BU_SG_REL_ BSM_HS SG_ 1217 BarPrsAbs 1;
BA_REL_ "GenSigTimeoutTime" BU_SG_REL_ BCM_HS SG_ 1217 BarPrsAbs 1250;
BA_REL_ "GenSigTimeoutMsg" BU_SG_REL_ BCM_HS SG_ 1217 BarPrsAbs 1217;
BA_REL_ "GenSigVBitResp" BU_SG_REL_ BCM_HS SG_ 1217 BarPrsAbs 1;
BA_REL_ "GenSigSuprvResp" BU_SG_REL_ BCM_HS SG_ 1217 BarPrsAbs 1;
VAL_ 463 FourWhlDrvIdReqExtRng 15 "Front Wheel Drive Mode Active" 14 "Front Wheel Drive Mode Pending" 13 "AWD Connected Mode Active" 12 "AWD Connected Mode Pending" 11 "Position Undetermined Active" 10 "Transfer Case Neutral Active" 9 "Transfer Case Neutral Pending" 8 "Four Wheel Drive Low Lock Active" 7 "Four Wheel Drive Low Lock Pending" 6 "Four Wheel Drive High Lock Active" 5 "Four Wheel Drive High Lock Pending" 4 "Four Wheel Drive High Auto Active" 3 "Four Wheel Drive High Auto Pending" 2 "Two Wheel Drive High Active" 1 "Two Wheel Drive High Pending" 0 "No Indication" ;
VAL_ 463 FourWhlDrvIndReq 0 "No Indication" 1 "Indication 1" 2 "Indication 2" 3 "Indication 3" 4 "Indication 4" 5 "Indication 5" 6 "Indication 6" 7 "Indication 7" ;
VAL_ 463 SecAxlNonEmMalfIO 1 "true" 0 "false" ;
VAL_ 463 SecAxlOperMod 3 "Active All Wheel Drive (High)" 2 "4 Wheel Drive Low Locked" 1 "4 Wheel Drive High Locked" 0 "2 Wheel Drive High" 15 "Neutral" 14 "Unknown" 7 "2 Wheel Drive Low" 6 "Active All Wheel Drive (Low)" 5 "4 Wheel Drive Low Open" 4 "4 Wheel Drive High Open" ;
VAL_ 463 SecAxlTmpInhIO 1 "true" 0 "false" ;
VAL_ 869 TnDrvGapAdjUnbIO 1 "true" 0 "false" ;
VAL_ 869 CPSCA_Resrv3Avail 1 "true" 0 "false" ;
VAL_ 869 CPSCA_Resrv2Avail 1 "true" 0 "false" ;
VAL_ 869 CPSCA_Resrv1Avail 1 "true" 0 "false" ;
VAL_ 869 CPSCA_AlrtBrkStrAvail 1 "true" 0 "false" ;
VAL_ 869 CPSCA_AlrtBrkAvail 1 "true" 0 "false" ;
VAL_ 869 CPSCA_AlrtAvail 1 "true" 0 "false" ;
VAL_ 869 CPSCA_OffAvail 1 "true" 0 "false" ;
VAL_ 869 FwdClnMtgnBrkReqAct 1 "true" 0 "false" ;
VAL_ 869 FCACustStngAvlbl 1 "true" 0 "false" ;
VAL_ 869 FwdClnAlrtCustCrntSetngVal 0 "No Action" 1 "Off" 2 "On" ;
VAL_ 869 GNCustSetngAvlbl 1 "true" 0 "false" ;
VAL_ 869 CPSUnblIO 1 "true" 0 "false" ;
VAL_ 869 ColPrSysStngAvl 1 "true" 0 "false" ;
VAL_ 869 CPSOffIO 1 "true" 0 "false" ;
VAL_ 869 CPSFldIO 1 "true" 0 "false" ;
VAL_ 869 ColPrSysCrntStng 4 "Alert and Brake and Steer" 0 "No Action" 1 "Off" 2 "Alert" 3 "Alert and Brake" ;
VAL_ 869 CPSAlrtOnlIO 1 "true" 0 "false" ;
VAL_ 869 GNCustCrntStngVal 0 "No Action" 1 "Off" 2 "On" ;
VAL_ 564 AdptDrvrSeatStng 7 "Performance Mode 7" 6 "Performance Mode 6" 5 "Performance Mode 5" 4 "Performance Mode 4" 3 "Performance Mode 3" 2 "Performance Mode 2" 1 "Performance Mode 1" 0 "No Action" ;
VAL_ 564 AdptPsngrSeatStng 7 "Performance Mode 7" 6 "Performance Mode 6" 5 "Performance Mode 5" 4 "Performance Mode 4" 3 "Performance Mode 3" 2 "Performance Mode 2" 1 "Performance Mode 1" 0 "No Action" ;
VAL_ 564 TnDrvTrCtrlOffUnbIO 1 "true" 0 "false" ;
VAL_ 564 TnDrvStblCtrlOffUnbIO 1 "true" 0 "false" ;
VAL_ 564 VehRollAngleV 1 "Invalid" 0 "Valid" ;
VAL_ 564 VehPitchAngleV 1 "Invalid" 0 "Valid" ;
VAL_ 564 RdWhlAngV 1 "Invalid" 0 "Valid" ;
VAL_ 564 TrlrStabAstActIO 1 "true" 0 "false" ;
VAL_ 564 PerfTrcCrnExStngVal 0 "No Action" 1 "Off" 2 "Setting 1" 3 "Setting 2" 4 "Setting 3" 5 "Setting 4" 6 "Setting 5" 7 "Setting 6" 8 "Setting 7" 9 "Setting 8" 10 "Setting 9" 11 "Setting 10" 12 "Setting 11" 13 "Setting 12" 14 "Setting 13" 15 "Setting 14" 16 "Setting 15" ;
VAL_ 1296 ACCAutoSetSpdStat 0 "No Set Speed Change" 1 "Proposed Speed Limit Change" 2 "Accepted Speed Limit Change" 3 "Declined Speed Limit Change" ;
VAL_ 1296 FwdClnAlrtOffIO 1 "true" 0 "false" ;
VAL_ 1296 VADIR_IndLvl 0 "No indication" 1 "Indication level 1" 2 "Indication Level 2" 3 "Indication Level 3" 4 "Indication Level 4" 5 "Indication Level 5" 6 "Indication Level 6" 7 "Indication Level 7" 8 "Indication Level 8" ;
VAL_ 848 TrlrBrkProfStat 1 "Inactive" 0 "Active" ;
VAL_ 848 TrlrBrkStat 6 "Integration Calibrated Off" 0 "Normal Operation" 1 "Brake Control Interactive" 2 "Temporary Inhibit" 3 "Temporarily Limited" 4 "Permanently Failed" 5 "Communication Failed" ;
VAL_ 848 TrlrBrkngSysBrkLtsReq 1 "true" 0 "false" ;
VAL_ 848 SrvTrlrBrkngSysIO 1 "true" 0 "false" ;
VAL_ 848 TrlrWiringFltIO 1 "true" 0 "false" ;
VAL_ 848 TrlrCnctdIO 1 "true" 0 "false" ;
VAL_ 848 TrlrBrkngGainSetIO 1 "true" 0 "false" ;
VAL_ 848 ChkTrlrIO 1 "true" 0 "false" ;
VAL_ 848 TrlrHtchSwAtv_ITBC 1 "true" 0 "false" ;
VAL_ 1011 BatVltHiResV 1 "Invalid" 0 "Valid" ;
VAL_ 1011 BatCrntExtRngV 1 "Invalid" 0 "Valid" ;
VAL_ 1011 BatSnsrlntFlt 1 "true" 0 "false" ;
VAL_ 1011 BatCrntExtRngM 1 "Use Data" 0 "Don't Use Data" ;
VAL_ 1011 BatVltHiResM 1 "Use Data" 0 "Don't Use Data" ;
VAL_ 993 HybVehHiVltSysDisbld 1 "true" 0 "false" ;
VAL_ 993 CstmrUsblSOCV 1 "Invalid" 0 "Valid" ;
VAL_ 993 JmpStrtStat 0 "Inactive" 1 "In Progress" 2 "Complete" 3 "Power Mode" 4 "Disabled" ;
VAL_ 993 SvcHybridSysIO 1 "true" 0 "false" ;
VAL_ 993 HybMdDisp 15 "Engine Charging Battery While Idle" 14 "Engine Charging Battery Moving" 13 "Engine Power Load Sharing" 12 "Battery Power Load Sharing" 11 "Undetermined" 10 "Charging With Engine On" 9 "Charging With Engine Off" 8 "Hybrid Power 4WD" 7 "Hybrid Power 2WD" 6 "Engine Power 4WD" 5 "Engine Power 2WD" 4 "Battery Power 4WD" 3 "Battery Power 2WD" 2 "Auto Stop" 1 "Engine Idle" 0 "Default / Accessory" ;
VAL_ 490 SrvcFlSysPrkInOpnArIO 1 "true" 0 "false" ;
VAL_ 490 FuelSysNEmsRltMalfAct 1 "true" 0 "false" ;
VAL_ 490 InActFuelMdFuelLvlIO 1 "true" 0 "false" ;
VAL_ 490 FlLvlTank2PctV 1 "Invalid" 0 "Valid" ;
VAL_ 490 AltFuelPHeatAct 1 "true" 0 "false" ;
VAL_ 490 AltFuelMdReqDndIO 1 "true" 0 "false" ;
VAL_ 490 AltFuelLvlLo 1 "true" 0 "false" ;
VAL_ 490 AltFuelAccWrnngAct 1 "true" 0 "false" ;
VAL_ 490 FuelMdStat 3 "Alternative Fuel Cut-off Active" 2 "Liquified Petroleum Gas Mode" 1 "Natural Gas Mode" 0 "Gasoline Mode" ;
VAL_ 452 ACCATCS_LmtgStat 3 "Request Rate Limited" 2 "Request Value Limited Maximum" 1 "Request Value Limited Minimum" 0 "Request Not Limited" ;
VAL_ 452 ACCATCS_RqStat 4 "Request Suspended Till Driver Input" 3 "Request Denied" 2 "Lost Arbitration" 1 "Request Honored" 0 "No Request" ;
VAL_ 452 CPSATCS_ReqStatus 0 "No Request" 1 "Request Honored" 2 "Lost Arbitration" 3 "Serial Data Failure Temporary" 4 "Serial Data Failure Permanent" 5 "Control System Failure Temporary" 6 "Control System Failure Permanent" ;
VAL_ 452 CPSATCS_LmtngStatus 0 "Request Not Limited" 1 "Request Value Limited to Minimum" 2 "Request Value Limited to Maximum" 3 "Request Rate Limited" ;
VAL_ 452 RVBATCS_ReqStat 0 "No Request" 1 "Request Honored" 2 "Lost Arbitration" 3 "Serial Data Failure Temporary" 4 "Serial Data Failure Permanent" 5 "Control System Failure Temporary" 6 "Control System Failure Permanent" ;
VAL_ 452 RVBATCS_LmtngStat 0 "Request Not Limited" 1 "Request Value Limited to Minimum" 2 "Request Value Limited to Maximum" 3 "Request Rate Limited" ;
VAL_ 452 FSpRgACCSwADd 1 "true" 0 "false" ;
VAL_ 452 ABAAPS_AccPosV 1 "Invalid" 0 "Valid" ;
VAL_ 452 AccPdlOvrrdAtv 1 "true" 0 "false" ;
VAL_ 1280 TireRRLowTracIO 1 "true" 0 "false" ;
VAL_ 1280 TireRFLowTracIO 1 "true" 0 "false" ;
VAL_ 1280 TireLRLowTracIO 1 "true" 0 "false" ;
VAL_ 1280 TireLFLowTracIO 1 "true" 0 "false" ;
VAL_ 562 BrkSysAutBrkStat 0 "Not active" 1 "Active" 2 "Limited" 3 "Failed" ;
VAL_ 562 FSRACCBrkngReqDenied 1 "true" 0 "false" ;
VAL_ 562 BrkSysExtHldCpbltyFld 1 "true" 0 "false" ;
VAL_ 562 DrvlneMntsPerfMdRq 0 "No Action" 1 "Performance Mode 1" 2 "Performance Mode 2" 3 "Performance Mode 3" 4 "Performance Mode 4" 5 "Performance Mode 5" 6 "Performance Mode 6" 7 "Performance Mode 7" ;
VAL_ 562 RideCntrlPerfMdRq 7 "Performance Mode 7" 6 "Performance Mode 6" 5 "Performance Mode 5" 4 "Performance Mode 4" 3 "Performance Mode 3" 2 "Performance Mode 2" 1 "Performance Mode 1" 0 "No Action" ;
VAL_ 562 StgSysPerfMdRq 7 "Performance Mode 7" 6 "Performance Mode 6" 5 "Performance Mode 5" 4 "Performance Mode 4" 3 "Performance Mode 3" 2 "Performance Mode 2" 1 "Performance Mode 1" 0 "No Action" ;
VAL_ 562 DiffPerfMdRq 7 "Performance Mode 7" 6 "Performance Mode 6" 5 "Performance Mode 5" 4 "Performance Mode 4" 3 "Performance Mode 3" 2 "Performance Mode 2" 1 "Performance Mode 1" 0 "No Action" ;
VAL_ 562 ExhstPerfMdRq 7 "Performance Mode 7" 6 "Performance Mode 6" 5 "Performance Mode 5" 4 "Performance Mode 4" 3 "Performance Mode 3" 2 "Performance Mode 2" 1 "Performance Mode 1" 0 "No Action" ;
VAL_ 562 AWDPerfMdRq 7 "Performance Mode 7" 6 "Performance Mode 6" 5 "Performance Mode 5" 4 "Performance Mode 4" 3 "Performance Mode 3" 2 "Performance Mode 2" 1 "Performance Mode 1" 0 "No Action" ;
VAL_ 562 SndPerfMdCsStAvl 1 "true" 0 "false" ;
VAL_ 562 SndPerfMdCsCrStVal 0 "No Action" 1 "Performance Mode 1" 2 "Performance Mode 2" 3 "Performance Mode 3" 4 "Performance Mode 4" 5 "Performance Mode 5" 6 "Performance Mode 6" 7 "Auto" ;
VAL_ 562 DispPerfMdCsStAvl 1 "true" 0 "false" ;
VAL_ 562 DispPerfMdCsCrStVal 0 "No Action" 1 "Performance Mode 1" 2 "Performance Mode 2" 3 "Performance Mode 3" 4 "Performance Mode 4" 5 "Performance Mode 5" 6 "Performance Mode 6" 7 "Auto" ;
VAL_ 562 SndEnhcmtPerfMdRq 7 "Performance Mode 7" 6 "Performance Mode 6" 5 "Performance Mode 5" 4 "Performance Mode 4" 3 "Performance Mode 3" 2 "Performance Mode 2" 1 "Performance Mode 1" 0 "No Action" ;
VAL_ 562 DsplyPerfMdRq 7 "Performance Mode 7" 6 "Performance Mode 6" 5 "Performance Mode 5" 4 "Performance Mode 4" 3 "Performance Mode 3" 2 "Performance Mode 2" 1 "Performance Mode 1" 0 "No Action" ;
VAL_ 562 HillDscntCntlSysStat 4 "Temporarily Inhibited" 3 "Failed" 2 "Active" 1 "Enabled" 0 "Normal" ;
VAL_ 562 SusCustStngAvlbl 1 "true" 0 "false" ;
VAL_ 562 SusCustCurrStngVal 7 "Auto" 6 "Performance Mode 6" 5 "Performance Mode 5" 4 "Performance Mode 4" 3 "Performance Mode 3" 0 "No Action" 1 "Performance Mode 1" 2 "Performance Mode 2" ;
VAL_ 562 StrCustStngAvlbl 1 "true" 0 "false" ;
VAL_ 562 StrCustCurrStngVal 2 "Performance Mode 2" 7 "Auto" 6 "Performance Mode 6" 5 "Performance Mode 5" 4 "Performance Mode 4" 3 "Performance Mode 3" 0 "No Action" 1 "Performance Mode 1" ;
VAL_ 562 DrvlnCustStngAvlbl 1 "true" 0 "false" ;
VAL_ 562 DrvlnCustCurrStngVal 7 "Auto" 6 "Performance Mode 6" 5 "Performance Mode 5" 4 "Performance Mode 4" 3 "Performance Mode 3" 0 "No Action" 1 "Performance Mode 1" 2 "Performance Mode 2" ;
VAL_ 386 AdptCruzCtrlStg 7 "Performance Mode 7" 6 "Performance Mode 6" 5 "Performance Mode 5" 4 "Performance Mode 4" 3 "Performance Mode 3" 2 "Performance Mode 2" 1 "Performance Mode 1" 0 "No Action" ;
VAL_ 386 AHAct 1 "true" 0 "false" ;
VAL_ 386 AHEnbld 1 "true" 0 "false" ;
VAL_ 386 ShfToPrkBfExtngIO 1 "true" 0 "false" ;
VAL_ 386 AHServcIO 1 "true" 0 "false" ;
VAL_ 386 AHAppBrkPedlIO 1 "true" 0 "false" ;
VAL_ 386 AHDisbldStbltIO 1 "true" 0 "false" ;
VAL_ 386 AHDisbldDrOpnIO 1 "true" 0 "false" ;
VAL_ 386 PMVSS_Disps 7 "Visualization Type 7" 6 "Visualization Type 6" 5 "Visualization Type 5" 4 "Visualization Type 4" 3 "Visualization Type 3" 2 "Visualization Type 2" 1 "Visualization Type 1" 0 "No Action" ;
VAL_ 386 PMVSS_Exhst 7 "Visualization Type 7" 6 "Visualization Type 6" 5 "Visualization Type 5" 4 "Visualization Type 4" 3 "Visualization Type 3" 2 "Visualization Type 2" 1 "Visualization Type 1" 0 "No Action" ;
VAL_ 386 PMVSS_PsngrSeat 7 "Visualization Type 7" 6 "Visualization Type 6" 5 "Visualization Type 5" 4 "Visualization Type 4" 3 "Visualization Type 3" 2 "Visualization Type 2" 1 "Visualization Type 1" 0 "No Action" ;
VAL_ 386 PMVSS_DrvrSeat 7 "Visualization Type 7" 6 "Visualization Type 6" 5 "Visualization Type 5" 4 "Visualization Type 4" 3 "Visualization Type 3" 2 "Visualization Type 2" 1 "Visualization Type 1" 0 "No Action" ;
VAL_ 386 PMVSS_AdptCrsCnt 7 "Visualization Type 7" 6 "Visualization Type 6" 5 "Visualization Type 5" 4 "Visualization Type 4" 3 "Visualization Type 3" 2 "Visualization Type 2" 1 "Visualization Type 1" 0 "No Action" ;
VAL_ 386 PMVSS_Drvln 7 "Visualization Type 7" 6 "Visualization Type 6" 5 "Visualization Type 5" 4 "Visualization Type 4" 3 "Visualization Type 3" 2 "Visualization Type 2" 1 "Visualization Type 1" 0 "No Action" ;
VAL_ 386 PMVSS_Susp 7 "Visualization Type 7" 6 "Visualization Type 6" 5 "Visualization Type 5" 4 "Visualization Type 4" 3 "Visualization Type 3" 2 "Visualization Type 2" 1 "Visualization Type 1" 0 "No Action" ;
VAL_ 386 PMVSS_Strng 7 "Visualization Type 7" 6 "Visualization Type 6" 5 "Visualization Type 5" 4 "Visualization Type 4" 3 "Visualization Type 3" 2 "Visualization Type 2" 1 "Visualization Type 1" 0 "No Action" ;
VAL_ 386 PMVSS_Trans 7 "Visualization Type 7" 6 "Visualization Type 6" 5 "Visualization Type 5" 4 "Visualization Type 4" 3 "Visualization Type 3" 2 "Visualization Type 2" 1 "Visualization Type 1" 0 "No Action" ;
VAL_ 386 PMVSS_Eng 7 "Visualization Type 7" 6 "Visualization Type 6" 5 "Visualization Type 5" 4 "Visualization Type 4" 3 "Visualization Type 3" 2 "Visualization Type 2" 1 "Visualization Type 1" 0 "No Action" ;
VAL_ 386 PMVSS_Snd 7 "Visualization Type 7" 6 "Visualization Type 6" 5 "Visualization Type 5" 4 "Visualization Type 4" 3 "Visualization Type 3" 2 "Visualization Type 2" 1 "Visualization Type 1" 0 "No Action" ;
VAL_ 386 AWDRecmndIO 1 "true" 0 "false" ;
VAL_ 386 EnvIdRspSt4 3 "Environment_id_request" 2 "Incorrect_immo_id" 1 "Info_valid" 0 "No_info" ;
VAL_ 532 RedntVSEAct 1 "true" 0 "false" ;
VAL_ 532 VehHldDrvrDsblActvFlg 1 "true" 0 "false" ;
VAL_ 532 AutoBrkngAvlbl 1 "true" 0 "false" ;
VAL_ 532 ABSAutnmsBrkReq 1 "true" 0 "false" ;
VAL_ 532 ABSActvProt 1 "true" 0 "false" ;
VAL_ 532 AutoBrkngAct 1 "true" 0 "false" ;
VAL_ 532 HilRlbkCtrlActIO 1 "true" 0 "false" ;
VAL_ 532 HlStrAssActIO 1 "true" 0 "false" ;
VAL_ 532 BrkSysAutBrkFld 1 "true" 0 "false" ;
VAL_ 532 IntBrkAssPreFilReq 1 "true" 0 "false" ;
VAL_ 532 BrkSysMalFuncIndOn 1 "true" 0 "false" ;
VAL_ 532 BPDAPS_BkPDrvApPV 1 "Invalid" 0 "Valid" ;
VAL_ 532 BrkFldLvlLwV 1 "Invalid" 0 "Valid" ;
VAL_ 532 BrkFldLvlLw 1 "true" 0 "false" ;
VAL_ 328 StrAsstRdcdLvl3IO 1 "true" 0 "false" ;
VAL_ 328 StrAsstRdcdLvl2IO 1 "true" 0 "false" ;
VAL_ 328 StrngAsstRdcdIO 1 "true" 0 "false" ;
VAL_ 328 PwrStrIO 1 "true" 0 "false" ;
VAL_ 560 ElecPrkBrkSwStatV 1 "Invalid" 0 "Valid" ;
VAL_ 560 ElecPrkBrkSwStat 3 "Active" 2 "Apply" 1 "Release" 0 "NotActive" ;
VAL_ 560 EPBC_EPBrkAutBrkRq 1 "true" 0 "false" ;
VAL_ 560 AllNodesVNA 1 "Activate Virtual Network" 0 "No Activation" ;
VAL_ 560 StpOnBrkToRelPBIndOn 1 "true" 0 "false" ;
VAL_ 560 EPBSysDspMsgReq 7 "Message #7" 6 "Message #6" 5 "Message #5" 4 "Message #4" 3 "Message #3" 2 "Message #2" 1 "Message #1" 0 "Off" ;
VAL_ 560 EPBSysAudWarnReq 2 "Warning #2" 1 "Warning #1" 0 "Off" ;
VAL_ 560 ElecPrkBrkStat 2 "Fault" 1 "Applied" 0 "Released" ;
VAL_ 560 EPBCrsCanRq 1 "true" 0 "false" ;
VAL_ 560 EPBSysStatIndReq 3 "Flash Rate 2 Indication" 2 "Flash Rate 1 Indication" 1 "Continuous Indication" 0 "No Indication" ;
VAL_ 560 EPBSysWrnIndReq 3 "Flash Rate #2 Indication" 2 "Flash Rate #1 Indication" 1 "Continuous Indication" 0 "No Indication" ;
VAL_ 560 EPBSysBrkLtsReq 1 "true" 0 "false" ;
VAL_ 451 HillDscntCtrlSwStat 0 "No Activation" 1 "Increment" 2 "Decrement" 3 "Faulted" ;
VAL_ 451 AccPosV 1 "Invalid" 0 "Valid" ;
VAL_ 451 EngTrqRdFlrSt 4 "Torq Reduction Communication Failed" 3 "Torque Reduction Limited" 2 "Torque Reduction Permanently Failed" 1 "Torque Reduction Temporarily Failed" 0 "Torque Reduction OK" ;
VAL_ 451 GlwPlgCrnkDelAct 1 "true" 0 "false" ;
VAL_ 451 AuxHtrAlwd 1 "true" 0 "false" ;
VAL_ 451 AppCltchAutSrtIO 1 "true" 0 "false" ;
VAL_ 451 EngTrqDrRqdExtRngV 1 "Invalid" 0 "Valid" ;
VAL_ 451 EngTrqActExtRngV 1 "Invalid" 0 "Valid" ;
VAL_ 1282 TireTrdTmpStat 0 "No Action (unknown)" 1 "Frozen" 2 "Cold" 3 "Warm" 4 "Hot" 5 "Overheated" ;
VAL_ 1282 AllNodesVNA_502 1 "Activate Virtual Network" 0 "No Activation" ;
VAL_ 880 ACCSysSltdMdDispIO 1 "true" 0 "false" ;
VAL_ 880 ACCSysSltdMd 3 "Unused And Reserved" 2 "Enhanced Cruise Control" 1 "Adaptive Cruise Control" 0 "Cruise Control Mode Switching Not Supported" ;
VAL_ 880 FOAI_VehAhdIndRq 0 "No Alert" 1 "Alert Level 1" 2 "Alert Level 2" 3 "Alert Level 3" ;
VAL_ 880 FOAI_AlrtWrnIndRq 0 "No Alert" 1 "Alert Level 1" 2 "Alert Level 2" 3 "Alert Level 3" ;
VAL_ 880 FOAI_AlrtChmIhbRq 0 "Allow Chime" 1 "Inhibit Chime" ;
VAL_ 880 FwdClnAlrtPr 1 "true" 0 "false" ;
VAL_ 880 ACCUnavlbleDTWthrIO 1 "true" 0 "false" ;
VAL_ 880 ACCAct370 1 "true" 0 "false" ;
VAL_ 880 DrvThrtlOvrdIO 1 "true" 0 "false" ;
VAL_ 880 ServAdpCrsCtrlIndOn 1 "true" 0 "false" ;
VAL_ 880 ACCHdwayStngIO 1 "true" 0 "false" ;
VAL_ 880 ACCHdwyStg 7 "Headway Setting 7" 6 "Headway Setting 6" 5 "Headway Setting 5" 4 "Headway Setting 4" 3 "Headway Setting 3" 2 "Headway Setting 2" 1 "Headway Setting 1" 0 "Minimum Headway Setting" ;
VAL_ 880 ACCSnsClnRqdIO 1 "true" 0 "false" ;
VAL_ 880 ACCTmpUnavlbleIO 1 "true" 0 "false" ;
VAL_ 880 ACCDrvrSeltdSpdIO 1 "true" 0 "false" ;
VAL_ 485 StrWhAngGrdV 1 "Invalid" 0 "Valid" ;
VAL_ 485 StrWhAngGrdMsk 0 "Don't Use Data" 1 "Use Data" ;
VAL_ 485 StrWhAngMsk 0 "Don't Use Data" 1 "Use Data" ;
VAL_ 485 StrWhlAngSenTyp 0 "Type 1" 1 "Type 2" 2 "Type 3" 3 "Type 4" ;
VAL_ 485 StrWhlAngSenCalStat 2 "Calibrated" 1 "Estimated" 0 "Unknown" ;
VAL_ 485 StrWhAngV 1 "Invalid" 0 "Valid" ;
VAL_ 1001 DistRollCntAvgDrvnSrc 1 "Wheel Speed" 0 "Transmission Output Speed" ;
VAL_ 1001 VehSpdAvgDrvnSrc 1 "Wheel Speed" 0 "Transmission Output Speed" ;
VAL_ 1001 DstRolCntAvgNonDrvnV 1 "Invalid" 0 "Valid" ;
VAL_ 1001 DstRolCntAvNDrRstOc 1 "true" 0 "false" ;
VAL_ 1001 DistRollCntAvgDrvnV 1 "Invalid" 0 "Valid" ;
VAL_ 1001 DstRolCntAvgDrnRstOc 1 "true" 0 "false" ;
VAL_ 1001 VehSpdAvgNDrvnV 1 "Invalid" 0 "Valid" ;
VAL_ 1001 VehSpdAvgDrvnV 1 "Invalid" 0 "Valid" ;
VAL_ 842 WhlRotDrctnlSRtNDrvn 0 "Unknown" 1 "Forward" 2 "Reverse" 3 "Not Supported" 4 "Failed" 5 "Reserved 1" 6 "Reserved 2" 7 "Reserved 3" ;
VAL_ 842 WhlRotDrctnlStLfNDrvn 0 "Unknown" 1 "Forward" 2 "Reverse" 3 "Not Supported" 4 "Failed" 5 "Reserved 1" 6 "Reserved 2" 7 "Reserved 3" ;
VAL_ 842 WhlGrndVlctyRtNnDrvnV 1 "Invalid" 0 "Valid" ;
VAL_ 842 WhlGrndVlctyLftNnDrvnV 1 "Invalid" 0 "Valid" ;
VAL_ 1019 FuelLvlEmnsRelStat 0 "Valid" 1 "Invalid" ;
VAL_ 1019 EmnsRelFuelLvlLw 1 "true" 0 "false" ;
VAL_ 1019 EngFuelCntlState 2 "Stoichiometric Closed Loop" 1 "Non-Stoichiometric Closed Loop" 0 "Open Loop" ;
VAL_ 1019 FuelAlchlCompAdptnPrg 1 "true" 0 "false" ;
VAL_ 1019 FuelAlcoholCompV 1 "Invalid" 0 "Valid" ;
VAL_ 1265 EngOffTmPTV 1 "Invalid" 0 "Valid" ;
VAL_ 1265 EngOffTmPTM 1 "Use Data" 0 "Don't Use Data" ;
VAL_ 1265 IdlRecmndToClEngIO 1 "true" 0 "false" ;
VAL_ 417 EngRunng 1 "true" 0 "false" ;
VAL_ 417 EngCrsCntrlMode 5 "Tap" 4 "Coast" 3 "Accel" 2 "Resume" 1 "Engaged" 0 "Inactive" ;
VAL_ 417 EngPstOxgSnsDgAstRq 1 "true" 0 "false" ;
VAL_ 417 CrsCtrlCnstSpdAct 1 "true" 0 "false" ;
VAL_ 417 WrmUpShftPtrnRq 1 "Active" 0 "Inactive" ;
VAL_ 417 EngAlwCltAdp 1 "true" 0 "false" ;
VAL_ 417 AccPdlPosPcntFullRngV 1 "Invalid" 0 "Valid" ;
VAL_ 417 DslPrtFltrIdlRgtnMdReq 1 "true" 0 "false" ;
VAL_ 417 DslPartFltrClngAlgActM 1 "Use Data" 0 "Don't Use Data" ;
VAL_ 417 DslPartFltrClngAlgAct 1 "true" 0 "false" ;
VAL_ 417 EngCylDeactMd 3 "Reactivation In Progress" 2 "Half of Total Cylinders Active" 1 "Deactivation In Progress" 0 "All Cylinders Active" ;
VAL_ 417 ParkNeutralSwStatV 1 "Invalid" 0 "Valid" ;
VAL_ 417 ParkNeutralSwStat 1 "Not Park/Neutral" 0 "Park/Neutral" ;
VAL_ 417 EngColdHiIdleActive 1 "true" 0 "false" ;
VAL_ 417 EngCyDactTqSmtAct 1 "true" 0 "false" ;
VAL_ 417 EngBrkStat 2 "Active Absorbing Torque" 1 "Active Not Absorbing Torque" 0 "Inactive" ;
VAL_ 417 TracCntlSysPwrtrnInhbt 1 "true" 0 "false" ;
VAL_ 417 EngMtlProtAtv 1 "true" 0 "false" ;
VAL_ 417 EngDgTrqCnvClUnlkRqd 1 "true" 0 "false" ;
VAL_ 417 EngCyldrDeactReqd 1 "true" 0 "false" ;
VAL_ 417 ETGRReqdGear 10 "Tenth Gear" 9 "Ninth Gear" 8 "Eighth Gear" 7 "Seventh Gear" 6 "Sixth Gear" 5 "Fifth Gear" 4 "Fourth Gear" 3 "Third Gear" 2 "Second Gear" 1 "First Gear" 0 "No Action" ;
VAL_ 417 ETGRReqType 0 "No Action" 3 "Hold Gear" 2 "Min Gear Request" 1 "Max Gear Request" ;
VAL_ 417 ACCmCltEngd 1 "true" 0 "false" ;
VAL_ 1233 a_12VBatSysUnstab 1 "true" 0 "false" ;
VAL_ 1233 PTExPrtclFltWrng3IO 1 "true" 0 "false" ;
VAL_ 1233 PTExPartFltManRegStat 7 "Unused and Reserved 2" 6 "Unused and Reserved 1" 5 "Pending Driver Input" 4 "Complete" 3 "In Progress" 2 "Not Allowed" 1 "Allowed" 0 "Cleaning Not Required" ;
VAL_ 1233 EngShtdwnAct 1 "true" 0 "false" ;
VAL_ 1233 EngShtdwnPndgIO 1 "true" 0 "false" ;
VAL_ 1233 FuelFltChgNwIO 1 "true" 0 "false" ;
VAL_ 1233 PTExPrtclFltrWrn2IO 1 "true" 0 "false" ;
VAL_ 1233 PTHiElecLdReqd 1 "true" 0 "false" ;
VAL_ 1233 PTExPrtclFltrWrnIO 1 "true" 0 "false" ;
VAL_ 1233 AirCndOffIO 1 "true" 0 "false" ;
VAL_ 1233 DslGlwPlgIO 1 "true" 0 "false" ;
VAL_ 1233 RdcdPwrIO 1 "true" 0 "false" ;
VAL_ 1233 FlLvlPctV 1 "Invalid" 0 "Valid" ;
VAL_ 1233 EngWtrInFlIO 1 "true" 0 "false" ;
VAL_ 1233 EngOilTmpV 1 "Invalid" 0 "Valid" ;
VAL_ 1233 EngOilPrsV 1 "Invalid" 0 "Valid" ;
VAL_ 1233 EngOilPrsLwIO 1 "true" 0 "false" ;
VAL_ 1233 EngOilLvlLwIO 1 "true" 0 "false" ;
VAL_ 1233 EngOilChngIO 1 "true" 0 "false" ;
VAL_ 1233 EngHt_StpEngIO 1 "true" 0 "false" ;
VAL_ 1233 EngHotFuelEnrchmntIO 1 "true" 0 "false" ;
VAL_ 1233 CkFlFilrCapIO 1 "true" 0 "false" ;
VAL_ 1217 LDMaxEngCltTmpRchd 1 "true" 0 "false" ;
VAL_ 1217 LDMinEngCltTmpRchd 1 "true" 0 "false" ;
VAL_ 1217 CdClrInhbt 1 "true" 0 "false" ;
VAL_ 1217 LegPstDTCClrDrvCyCm 1 "true" 0 "false" ;
VAL_ 1217 EngIntAirTmpM 1 "Use Data" 0 "Dont Use Data" ;
VAL_ 1217 LegDiagColdStCndMet 1 "true" 0 "false" ;
VAL_ 1217 LegDiagColdStCndFltPr 1 "true" 0 "false" ;
VAL_ 1217 LegDiagStndCndMet 1 "true" 0 "false" ;
VAL_ 1217 LegDiagStndCndFltPr 1 "true" 0 "false" ;
VAL_ 1217 EngWrmUpAch 1 "true" 0 "false" ;
VAL_ 1217 DslExhFldRmngDstHRsV 1 "Invalid" 0 "Valid" ;
VAL_ 1217 EngOilHotIO 1 "true" 0 "false" ;
VAL_ 1217 OAT_PT_EstV 1 "Invalid" 0 "Valid" ;
VAL_ 1217 OAT_PT_EstM 1 "Use Data" 0 "Don't Use Data" ;
VAL_ 1217 EngIntAirTmpV 1 "Invalid" 0 "Valid" ;
VAL_ 1217 EngCltTmpV 1 "Invalid" 0 "Valid" ;
VAL_ 1217 BarPrsAbsV 1 "Invalid" 0 "Valid" ;
VAL_ 665 EngFuelCntlState_299 2 "Stoichiometric Closed Loop" 1 "Non-Stoichiometric Closed Loop" 0 "Open Loop" ;
VAL_ 665 RdGasFuelDsblAct 1 "true" 0 "false" ;
VAL_ 665 RdDistFuelMdCmd 3 "FICM" 2 "Dual" 1 "ECM" 0 "Indeterminate" ;
VAL_ 665 PetrolFuelSysReqAval 3 "Not Available" 2 "Fault Transition Required" 1 "Fault Transition Requests" 0 "Available" ;
VAL_ 665 AltFuelSysReqAlwd 1 "true" 0 "false" ;
VAL_ 665 AltFuelInjHCmdLwRes 1 "FICM" 0 "ECM" ;
VAL_ 665 AltFuelInjGCmdLwRes 1 "FICM" 0 "ECM" ;
VAL_ 665 AltFuelInjFCmdLwRes 1 "FICM" 0 "ECM" ;
VAL_ 665 AltFuelInjECmdLwRes 1 "FICM" 0 "ECM" ;
VAL_ 665 AltFuelInjDCmdLwRes 1 "FICM" 0 "ECM" ;
VAL_ 665 AltFuelInjCCmdLwRes 1 "FICM" 0 "ECM" ;
VAL_ 665 AltFuelInjBCmdLwRes 1 "FICM" 0 "ECM" ;
VAL_ 665 AltFuelInjACmdLwRes 1 "FICM" 0 "ECM" ;
VAL_ 665 BiFuelRflGaslinIndReq 7 "Unused and Reserved 5" 6 "Unused and Reserved 4" 5 "Unused and Reserved 3" 4 "Unused and Reserved 2" 3 "Unused and Reserved 1" 2 "Indication 2" ;
SIG_GROUP_ 869 ColPrepSysCustAvail 1 : CPSCA_Resrv3Avail CPSCA_Resrv2Avail CPSCA_Resrv1Avail CPSCA_AlrtBrkStrAvail CPSCA_AlrtBrkAvail CPSCA_AlrtAvail CPSCA_OffAvail;
SIG_GROUP_ 1296 VhlAhdDstIndReq 1 : VADIR_IndLvl VADIR_FlwTme VADIR_FlwDst;
SIG_GROUP_ 452 AutBrkAccActPsSt 1 : ABAAPS_AccPos ABAAPS_AccPosV;
SIG_GROUP_ 452 ACCAxlTrqCmdStat 1 : ACCATCS_LmtgStat ACCATCS_RqStat;
SIG_GROUP_ 452 ColPrSysAxlTrqCmdStat 1 : CPSATCS_ReqStatus CPSATCS_LmtngStatus;
SIG_GROUP_ 452 RrVrtBmpAxlTrqCmdStat 1 : RVBATCS_ReqStat RVBATCS_LmtngStat;
SIG_GROUP_ 386 PerfMdVislztnScrnStat 1 : PMVSS_Disps PMVSS_Exhst PMVSS_PsngrSeat PMVSS_DrvrSeat PMVSS_AdptCrsCnt PMVSS_Drvln PMVSS_Susp PMVSS_Strng PMVSS_Trans PMVSS_Eng PMVSS_Snd;
SIG_GROUP_ 532 BrkPdDrvAppPrsStat 1 : BPDAPS_BkPDrvApPV BPDAPS_BkPDrvApP;
SIG_GROUP_ 560 ElecPrkBrkCmd 1 : EPBC_EPBAccRq EPBC_EPBrkAutBrkRq;
SIG_GROUP_ 1282 Alrm3ExtRngReq 1 :;
SIG_GROUP_ 880 FwdObjAlrtInd 1 : FOAI_VehAhdIndRq FOAI_AlrtWrnIndRq FOAI_AlrtChmIhbRq;
SIG_GROUP_ 417 EngTransGearReq 1 : ETGRReqdGear ETGRReqType;
